VERSION ""

NS_ :

BS_:

BU_: Turbocharger OnBoardDataLogger OffBoardDiagnosticTool2 OffBoardDiagnosticTool1 FileServer ParkingBrakeController SeatControl2 FanDriveController SteeringColumnUnit CommunicationUnitRadio CommunicationUnitSatellite CommunicationUnitCellular PropulsionBatteryCharger ChassisController2 ChassisController1 EngineValveControl AuxiliaryHeater2 AuxiliaryHeater1 ClutchUnit RampControl InformationSystem1 SuspensionSystemController2 OilSensor VehicleDynamicStability ExhaustEmissionController TransmissionDisplay2 TransmissionDisplay1 ClimateControl2 WaterPumpController RearAxleSteeringController LightingOperatorControl SeatController1 IgnitionController2 IgnitionController1 TirePressureController CabController2 CabController1 PneumaticSystemController SuspensionSystemController1 HydraulicPumpController EnduranceBrakingSystem RetarderExhaustEngine2 OnBoardDiagnosticUnit HeadwayController RetarderExhaustEngine1 CabDisplay1 ManagementComputer VirtualTerminal OffVehicleGateway PowerTakeOffFront HitchControl AuxiliaryValveControl BodyController TractorTrailerBridge1 StarterSystem ElectricalSystem VehicleSecurity VehicleNavigation AerodynamicControl ElectricalChargingSystem ClimateControl1 TripRecorder InstrumentCluster SuspensionDriveAxle2 SuspensionDriveAxle1 SuspensionSteerAxle SteeringController FuelSystem CruiseControl RetarderDriveline RetarderEngine BrakesDriveAxle2 BrakesDriveAxle1 BrakesSystemController BrakesSteerAxle AxleDrive2 AxleDrive1 AxleSteering PowerTakeOff ShiftConsoleSecondary ShiftConsolePrimary Transmission2 Transmission1 Engine2 Engine1

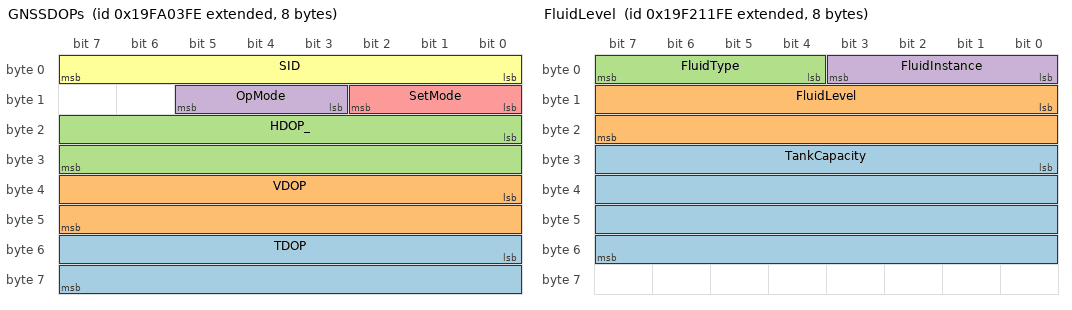
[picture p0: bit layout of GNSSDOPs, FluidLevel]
BO_ 2583299070 GNSSDOPs: 8 Vector__XXX
 SG_ TDOP : 48|16@1- (0.01,0) [-327.64|327.64] "" Vector__XXX
 SG_ VDOP : 32|16@1- (0.01,0) [-327.64|327.64] "" Vector__XXX
 SG_ HDOP_ : 16|16@1- (0.01,0) [-327.64|327.64] "" Vector__XXX
 SG_ OpMode : 11|3@1+ (1,0) [0|7] "" Vector__XXX
 SG_ SetMode : 8|3@1+ (1,0) [0|7] "" Vector__XXX
 SG_ SID : 0|8@1+ (1,0) [0|252] "" Vector__XXX

BO_ 2583298814 GNSSCtrlStatus: 16 Vector__XXX
 SG_ UseAntennaAltitudeFor2DMode : 120|2@1+ (1,0) [0|3] "" Vector__XXX
 SG_ AntennaAltitudeFor2DMode : 88|32@1- (0.01,0) [-21470000|21470000] "m" Vector__XXX
 SG_ MaxCorrectionAge : 72|16@1+ (0.01,0) [0|655.32] "sec" Vector__XXX
 SG_ Pos_VelocityFilter : 70|2@1+ (1,0) [0|3] "" Vector__XXX
 SG_ DGNSSMode : 67|3@1+ (1,0) [0|7] "" Vector__XXX
 SG_ GNSSMode : 64|3@1+ (1,0) [0|7] "" Vector__XXX
 SG_ SNRMask : 48|16@1- (0.01,0) [-327.64|327.64] "dB" Vector__XXX
 SG_ PDOPSwitch : 32|16@1- (0.01,0) [-327.64|327.64] "" Vector__XXX
 SG_ PDOPMask : 16|16@1- (0.01,0) [-327.64|327.64] "" Vector__XXX
 SG_ SVElevationMask : 0|16@1- (0.0001,0) [-3.14159|3.14159] "rad" Vector__XXX

BO_ 2583303422 GLONASSAlmanacData: 26 Vector__XXX
 SG_ tnA2 : 196|12@1+ (1,0) [0|4095] "" Vector__XXX
 SG_ tcA : 168|28@1+ (1,0) [0|268435455] "" Vector__XXX
 SG_ inA : 144|24@1+ (1,0) [0|16777215] "" Vector__XXX
 SG_ nA3 : 120|24@1+ (1,0) [0|16777215] "" Vector__XXX
 SG_ tnA : 96|24@1+ (1,0) [0|16777215] "" Vector__XXX
 SG_ TnA : 72|24@1+ (1,0) [0|16777215] "" Vector__XXX
 SG_ nA2 : 56|16@1+ (1,0) [0|65535] "" Vector__XXX
 SG_ DOT : 48|8@1+ (1,0) [0|255] "" Vector__XXX
 SG_ nA : 32|16@1+ (1,0) [0|65535] "" Vector__XXX
 SG_ HnA : 27|5@1+ (1,0) [0|31] "" Vector__XXX
 SG_ CnA : 26|1@1+ (1,0) [0|1] "" Vector__XXX
 SG_ NA : 8|16@1+ (1,0) [0|65532] "" Vector__XXX
 SG_ PRN : 0|8@1+ (1,0) [0|252] "" Vector__XXX

BO_ 2582778366 FluidLevel: 8 Vector__XXX
 SG_ TankCapacity : 24|32@1+ (0.0001,0) [0|429600] "cu m" Vector__XXX
 SG_ FluidLevel : 8|16@1- (1,0) [-124|124] "" Vector__XXX
 SG_ FluidType : 4|4@1+ (1,0) [0|15] "" Vector__XXX
 SG_ FluidInstance : 0|4@1+ (1,0) [0|15] "" Vector__XXX

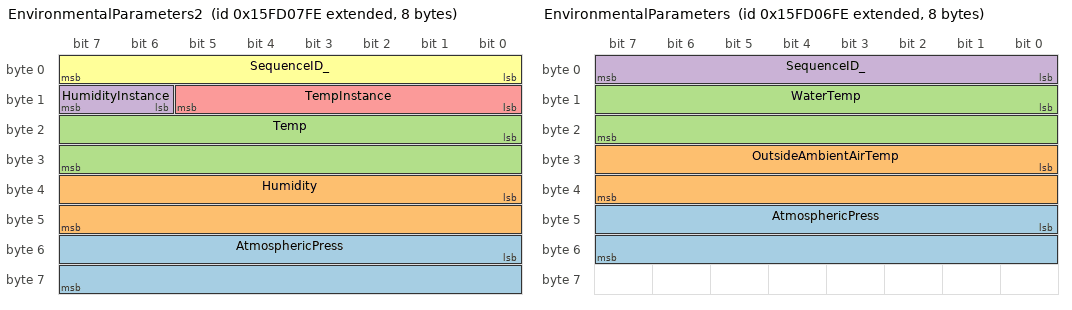
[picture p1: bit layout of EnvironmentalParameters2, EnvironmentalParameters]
BO_ 2516387838 EnvironmentalParameters2: 8 Vector__XXX
 SG_ AtmosphericPress : 48|16@1+ (100,0) [0|6553200] "Pa" Vector__XXX
 SG_ Humidity : 32|16@1- (1,0) [-124|124] "" Vector__XXX
 SG_ Temp : 16|16@1+ (0.01,0) [0|655.32] "°K" Vector__XXX
 SG_ HumidityInstance : 14|2@1+ (1,0) [0|3] "" Vector__XXX
 SG_ TempInstance : 8|6@1+ (1,0) [0|63] "" Vector__XXX
 SG_ SequenceID_ : 0|8@1+ (1,0) [0|252] "" Vector__XXX

BO_ 2516387582 EnvironmentalParameters: 8 Vector__XXX
 SG_ AtmosphericPress : 40|16@1+ (100,0) [0|6553200] "Pa" Vector__XXX
 SG_ OutsideAmbientAirTemp : 24|16@1+ (0.01,0) [0|655.32] "°K" Vector__XXX
 SG_ WaterTemp : 8|16@1+ (0.01,0) [0|655.32] "°K" Vector__XXX
 SG_ SequenceID_ : 0|8@1+ (1,0) [0|252] "" Vector__XXX

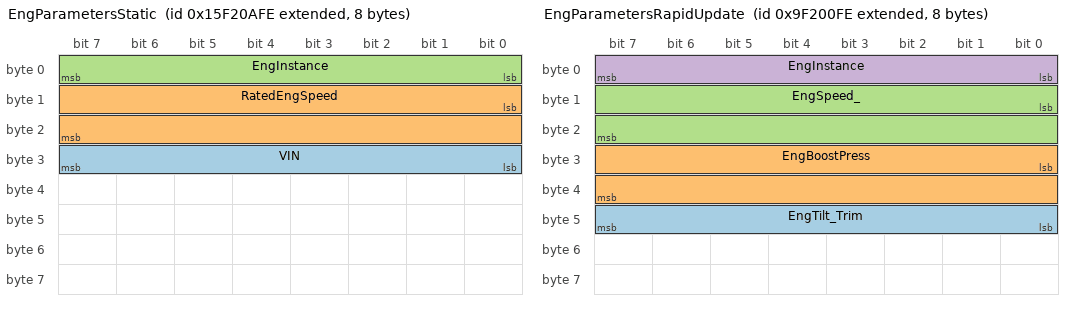
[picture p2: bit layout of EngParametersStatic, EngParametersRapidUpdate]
BO_ 2515667710 EngParametersStatic: 8 Vector__XXX
 SG_ VIN : 24|8@1+ (1,0) [0|255] "ASCII" Vector__XXX
 SG_ RatedEngSpeed : 8|16@1+ (1,0) [0|16383] "rpm" Vector__XXX
 SG_ EngInstance : 0|8@1+ (1,0) [0|255] "" Vector__XXX

BO_ 2314338558 EngParametersRapidUpdate: 8 Vector__XXX
 SG_ EngTilt_Trim : 40|8@1- (1,0) [-124|124] "" Vector__XXX
 SG_ EngBoostPress : 24|16@1+ (100,0) [0|6553200] "Pa" Vector__XXX
 SG_ EngSpeed_ : 8|16@1+ (1,0) [0|16383] "rpm" Vector__XXX
 SG_ EngInstance : 0|8@1+ (1,0) [0|255] "" Vector__XXX

BO_ 2314338814 EngParametersDynamic: 26 Vector__XXX
 SG_ PercentEngTorque : 200|8@1- (1,0) [-124|124] "" Vector__XXX
 SG_ PercentEngLoad : 192|8@1- (1,0) [-124|124] "" Vector__XXX
 SG_ EngDiscreteStatus2 : 176|16@1+ (1,0) [0|65535] "" Vector__XXX
 SG_ EngDiscreteStatus1 : 160|16@1+ (1,0) [0|65535] "" Vector__XXX
 SG_ FuelPress : 136|16@1+ (1000,0) [0|65532000] "Pa" Vector__XXX
 SG_ EngCoolantPress_ : 120|16@1+ (100,0) [0|6553200] "Pa" Vector__XXX
 SG_ TotalEngHours : 88|32@1+ (1,0) [0|32704] "sec" Vector__XXX
 SG_ FuelRate : 72|16@1- (0.0001,0) [-3.2764|3.2764] "(cu m)/hr" Vector__XXX
 SG_ AltPotential : 56|16@1- (0.01,0) [-327.64|327.64] "V" Vector__XXX
 SG_ EngTemp : 40|16@1+ (0.01,0) [0|655.32] "°K" Vector__XXX
 SG_ EngOilTemp : 24|16@1+ (0.1,0) [0|6553.2] "°K" Vector__XXX
 SG_ EngOilPress_ : 8|16@1+ (100,0) [0|6553200] "Pa" Vector__XXX
 SG_ EngInstance : 0|8@1+ (1,0) [0|255] "" Vector__XXX

BO_ 2582975486 DistanceLog: 14 Vector__XXX
 SG_ DistanceSinceLastReset : 80|32@1+ (1,0) [0|32704] "m" Vector__XXX
 SG_ TotalCumulativeDistance : 48|32@1+ (1,0) [0|32704] "m" Vector__XXX
 SG_ MeasurementTime : 16|32@1+ (0.0001,0) [0|86401] "sec" Vector__XXX
 SG_ MeasurementDate : 0|16@1+ (1,0) [0|65532] "day" Vector__XXX

BO_ 2382238206 DirectionData: 14 Vector__XXX
 SG_ Drift : 96|16@1+ (0.01,0) [0|655.32] "m/s" Vector__XXX
 SG_ Set : 80|16@1+ (0.0001,0) [0|6.28318] "rad" Vector__XXX
 SG_ SpeedThroughWater : 64|16@1+ (0.01,0) [0|655.32] "m/s" Vector__XXX
 SG_ Heading : 48|16@1+ (0.0001,0) [0|6.28318] "rad" Vector__XXX
 SG_ SpeedOverGround : 32|16@1+ (0.01,0) [0|655.32] "m/s" Vector__XXX
 SG_ CourseOverGround : 16|16@1+ (0.0001,0) [0|6.28318] "rad" Vector__XXX
 SG_ SID : 8|8@1+ (1,0) [0|252] "" Vector__XXX
 SG_ Set_COG_HeadingRef : 4|2@1+ (1,0) [0|3] "" Vector__XXX
 SG_ DataMode : 0|4@1+ (1,0) [0|15] "" Vector__XXX

BO_ 2583172350 Datum: 8 Vector__XXX
 SG_ LocalDatum : 0|8@1+ (1,0) [0|255] "ASCII" Vector__XXX

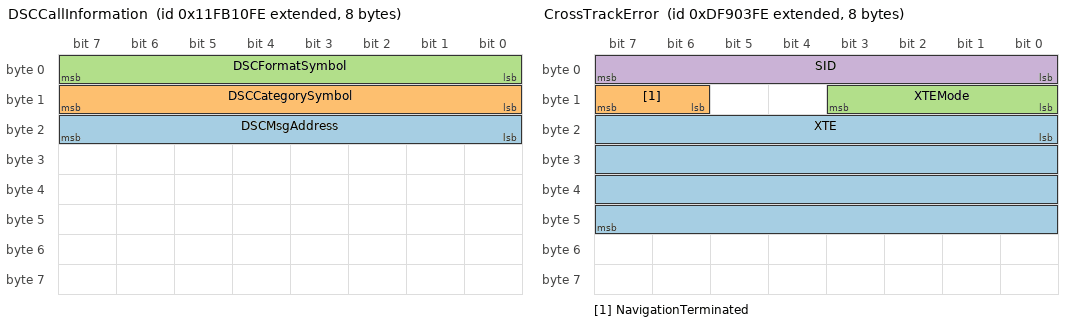
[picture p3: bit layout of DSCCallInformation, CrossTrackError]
BO_ 2449150206 DSCCallInformation: 8 Vector__XXX
 SG_ DSCMsgAddress : 16|8@1+ (1,0) [0|255] "ASCII" Vector__XXX
 SG_ DSCCategorySymbol : 8|8@1+ (1,0) [0|252] "" Vector__XXX
 SG_ DSCFormatSymbol : 0|8@1+ (1,0) [0|252] "" Vector__XXX

BO_ 2583301630 DGNSSCorrections: 16 Vector__XXX
 SG_ IOD : 120|8@1+ (1,0) [0|252] "" Vector__XXX
 SG_ UDRE : 104|16@1+ (0.01,0) [0|655.32] "m" Vector__XXX
 SG_ RRC : 88|16@1- (0.0001,0) [-3.2764|3.2764] "m/s" Vector__XXX
 SG_ PRC : 56|32@1- (0.0001,0) [-214700|214700] "m" Vector__XXX
 SG_ SatelliteID : 48|8@1+ (1,0) [0|252] "" Vector__XXX
 SG_ StationHealth : 40|4@1+ (1,0) [0|15] "" Vector__XXX
 SG_ TimeOfCorrections : 24|16@1+ (1,0) [0|6553.2] "sec" Vector__XXX
 SG_ ReferenceStationType : 20|4@1+ (1,0) [0|15] "" Vector__XXX
 SG_ ReferenceStationID : 8|12@1+ (1,0) [0|4095] "" Vector__XXX
 SG_ SequenceID_ : 0|8@1+ (1,0) [0|252] "" Vector__XXX

BO_ 2583499518 CurrentStationData: 26 Vector__XXX
 SG_ StationIDString : 200|8@1+ (1,0) [0|255] "ASCII" Vector__XXX
 SG_ WaterTemp : 184|16@1+ (0.01,0) [0|655.32] "°K" Vector__XXX
 SG_ CurrentFlowDirection : 168|16@1+ (0.0001,0) [0|6.28318] "rad" Vector__XXX
 SG_ CurrentSpeed : 152|16@1+ (0.01,0) [0|655.32] "m/s" Vector__XXX
 SG_ MeasurementDepth : 120|32@1+ (0.01,0) [0|42950000] "m" Vector__XXX
 SG_ StationLocationLongitude : 88|32@1- (1E-007,0) [-180|180] "deg" Vector__XXX
 SG_ StationLocationLatitude : 56|32@1- (1E-007,0) [-90|90] "deg" Vector__XXX
 SG_ MeasurementTime : 24|32@1+ (0.0001,0) [0|86401] "sec" Vector__XXX
 SG_ MeasurementDate : 8|16@1+ (1,0) [0|65532] "day" Vector__XXX
 SG_ State : 4|3@1+ (1,0) [0|7] "" Vector__XXX
 SG_ Mode : 0|4@1+ (1,0) [0|15] "" Vector__XXX

BO_ 2381906942 CrossTrackError: 8 Vector__XXX
 SG_ XTE : 16|32@1- (0.01,0) [-21470000|21470000] "m" Vector__XXX
 SG_ NavigationTerminated : 14|2@1+ (1,0) [0|3] "" Vector__XXX
 SG_ XTEMode : 8|4@1+ (1,0) [0|15] "" Vector__XXX
 SG_ SID : 0|8@1+ (1,0) [0|252] "" Vector__XXX

BO_ 2582648574 ConfigInformation: 8 Vector__XXX
 SG_ InstallationDescriptionField1 : 0|8@1+ (1,0) [0|255] "ASCII" Vector__XXX

BO_ 2583238398 BringAndDistanceBetweenTwoMarks: 17 Vector__XXX
 SG_ DestinationMarkID : 104|32@1+ (1,0) [0|4294967292] "" Vector__XXX
 SG_ OriginMarkId : 72|32@1+ (1,0) [0|4294967292] "" Vector__XXX
 SG_ DestinationMarkType : 68|4@1+ (1,0) [0|15] "" Vector__XXX
 SG_ OriginMarkType : 64|4@1+ (1,0) [0|15] "" Vector__XXX
 SG_ Distance : 32|32@1- (0.01,0) [-21470000|21470000] "m" Vector__XXX
 SG_ BearingiginToDestination : 16|16@1+ (0.0001,0) [0|6.28318] "rad" Vector__XXX
 SG_ CalculationType : 10|2@1+ (1,0) [0|3] "" Vector__XXX
 SG_ BearingRef : 8|2@1+ (1,0) [0|3] "" Vector__XXX
 SG_ SID : 0|8@1+ (1,0) [0|252] "" Vector__XXX

BO_ 2381450750 BinarySwitchBankStatus: 8 Vector__XXX
 SG_ Indic28 : 62|2@1+ (1,0) [0|3] "" Vector__XXX
 SG_ Indic27 : 60|2@1+ (1,0) [0|3] "" Vector__XXX
 SG_ Indic26 : 58|2@1+ (1,0) [0|3] "" Vector__XXX
 SG_ Indic25 : 56|2@1+ (1,0) [0|3] "" Vector__XXX
 SG_ Indic24 : 54|2@1+ (1,0) [0|3] "" Vector__XXX
 SG_ Indic23 : 52|2@1+ (1,0) [0|3] "" Vector__XXX
 SG_ Indic22 : 50|2@1+ (1,0) [0|3] "" Vector__XXX
 SG_ Indic21 : 48|2@1+ (1,0) [0|3] "" Vector__XXX
 SG_ Indic20 : 46|2@1+ (1,0) [0|3] "" Vector__XXX
 SG_ Indic19 : 44|2@1+ (1,0) [0|3] "" Vector__XXX
 SG_ Indic18 : 42|2@1+ (1,0) [0|3] "" Vector__XXX
 SG_ Indic17 : 40|2@1+ (1,0) [0|3] "" Vector__XXX
 SG_ Indic16 : 38|2@1+ (1,0) [0|3] "" Vector__XXX
 SG_ Indic15 : 36|2@1+ (1,0) [0|3] "" Vector__XXX
 SG_ Indic14 : 34|2@1+ (1,0) [0|3] "" Vector__XXX
 SG_ Indic13 : 32|2@1+ (1,0) [0|3] "" Vector__XXX
 SG_ Indic12 : 30|2@1+ (1,0) [0|3] "" Vector__XXX
 SG_ Indic11 : 28|2@1+ (1,0) [0|3] "" Vector__XXX
 SG_ Indic10 : 26|2@1+ (1,0) [0|3] "" Vector__XXX
 SG_ Indic9 : 24|2@1+ (1,0) [0|3] "" Vector__XXX
 SG_ Indic8 : 22|2@1+ (1,0) [0|3] "" Vector__XXX
 SG_ Indic7 : 20|2@1+ (1,0) [0|3] "" Vector__XXX
 SG_ Indic6 : 18|2@1+ (1,0) [0|3] "" Vector__XXX
 SG_ Indic5 : 16|2@1+ (1,0) [0|3] "" Vector__XXX
 SG_ Indic4 : 14|2@1+ (1,0) [0|3] "" Vector__XXX
 SG_ Indic3 : 12|2@1+ (1,0) [0|3] "" Vector__XXX
 SG_ Indic2 : 10|2@1+ (1,0) [0|3] "" Vector__XXX
 SG_ Indic1 : 8|2@1+ (1,0) [0|3] "" Vector__XXX
 SG_ IndicatorBankInstance : 0|8@1+ (1,0) [0|252] "" Vector__XXX

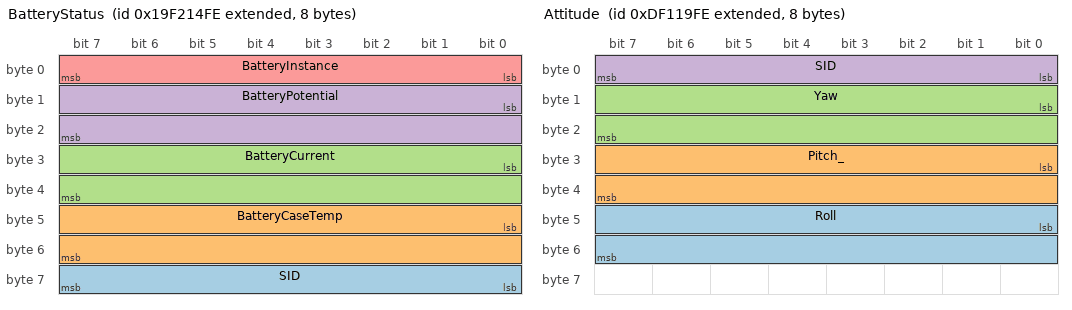
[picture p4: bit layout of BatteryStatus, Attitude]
BO_ 2582779134 BatteryStatus: 8 Vector__XXX
 SG_ SID : 56|8@1+ (1,0) [0|252] "" Vector__XXX
 SG_ BatteryCaseTemp : 40|16@1+ (0.01,0) [0|655.32] "°K" Vector__XXX
 SG_ BatteryCurrent : 24|16@1- (0.1,0) [-3276.4|3276.4] "A" Vector__XXX
 SG_ BatteryPotential : 8|16@1- (0.01,0) [-327.64|327.64] "V" Vector__XXX
 SG_ BatteryInstance : 0|8@1+ (1,0) [0|252] "" Vector__XXX

BO_ 2381388286 Attitude: 8 Vector__XXX
 SG_ Roll : 40|16@1- (0.0001,0) [-3.14159|3.14159] "rad" Vector__XXX
 SG_ Pitch_ : 24|16@1+ (0.0001,0) [-3.14159|3.14159] "rad" Vector__XXX
 SG_ Yaw : 8|16@1- (0.0001,0) [-3.14159|3.14159] "rad" Vector__XXX
 SG_ SID : 0|8@1+ (1,0) [0|252] "" Vector__XXX

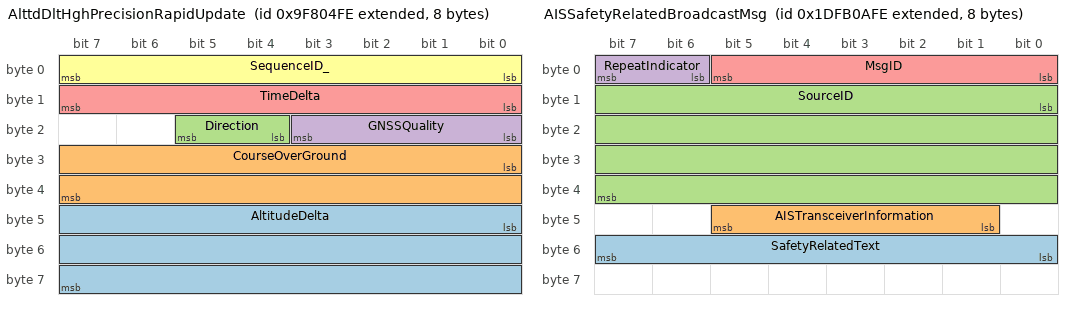
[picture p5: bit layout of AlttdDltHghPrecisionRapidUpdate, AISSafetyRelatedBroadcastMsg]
BO_ 2314732798 AlttdDltHghPrecisionRapidUpdate: 8 Vector__XXX
 SG_ AltitudeDelta : 40|24@1- (0.001,0) [-8388|8388] "m" Vector__XXX
 SG_ CourseOverGround : 24|16@1+ (0.0001,0) [0|6.28318] "rad" Vector__XXX
 SG_ Direction : 20|2@1+ (1,0) [0|3] "" Vector__XXX
 SG_ GNSSQuality : 16|4@1+ (1,0) [0|15] "" Vector__XXX
 SG_ TimeDelta : 8|8@1+ (0.005,0) [0|1.26] "sec" Vector__XXX
 SG_ SequenceID_ : 0|8@1+ (1,0) [0|252] "" Vector__XXX

BO_ 2650474750 AISUTC_DateInquiry: 11 Vector__XXX
 SG_ DestinationID : 48|32@1+ (1,0) [0|4294967292] "" Vector__XXX
 SG_ AISTransceiverInformation : 41|5@1+ (1,0) [0|31] "" Vector__XXX
 SG_ SourceID : 8|32@1+ (1,0) [0|4294967292] "" Vector__XXX
 SG_ RepeatIndicator : 6|2@1+ (1,0) [0|3] "" Vector__XXX
 SG_ MsgID : 0|6@1+ (1,0) [0|63] "" Vector__XXX

BO_ 2650472958 AISUTCAndDateReport: 26 Vector__XXX
 SG_ TypeOfElectronicPosingDevice : 188|4@1+ (1,0) [0|15] "" Vector__XXX
 SG_ PosDate : 168|16@1+ (1,0) [0|65532] "day" Vector__XXX
 SG_ AISTransceiverInformation : 163|5@1+ (1,0) [0|31] "" Vector__XXX
 SG_ CommunicationState : 144|19@1+ (1,0) [0|524287] "" Vector__XXX
 SG_ PosTime : 112|32@1+ (0.0001,0) [0|86401] "sec" Vector__XXX
 SG_ RAIMflag : 105|1@1+ (1,0) [0|1] "" Vector__XXX
 SG_ PosAccuracy : 104|1@1+ (1,0) [0|1] "" Vector__XXX
 SG_ Latitude_ : 72|32@1- (1E-007,0) [-90|90] "deg" Vector__XXX
 SG_ Longitude_ : 40|32@1- (1E-007,0) [-180|180] "deg" Vector__XXX
 SG_ UserID : 8|32@1+ (1,0) [0|4294967292] "" Vector__XXX
 SG_ RepeatIndicator : 6|2@1+ (1,0) [0|3] "" Vector__XXX
 SG_ MsgID : 0|6@1+ (1,0) [0|63] "" Vector__XXX

BO_ 2650475262 AISSafetyRelatedBroadcastMsg: 8 Vector__XXX
 SG_ SafetyRelatedText : 48|8@1+ (1,0) [0|255] "ASCII" Vector__XXX
 SG_ AISTransceiverInformation : 41|5@1+ (1,0) [0|31] "" Vector__XXX
 SG_ SourceID : 8|32@1+ (1,0) [0|4294967292] "" Vector__XXX
 SG_ RepeatIndicator : 6|2@1+ (1,0) [0|3] "" Vector__XXX
 SG_ MsgID : 0|6@1+ (1,0) [0|63] "" Vector__XXX

BO_ 2650474238 AISSARAircraftPosReport: 27 Vector__XXX
 SG_ DataTerminalEquipment : 208|1@1+ (1,0) [0|1] "" Vector__XXX
 SG_ Altitude_ : 168|32@1- (0.01,0) [-21470000|21470000] "m" Vector__XXX
 SG_ AISTransceiverInformation : 163|5@1+ (1,0) [0|31] "" Vector__XXX
 SG_ CommunicationState : 144|19@1+ (1,0) [0|524287] "" Vector__XXX
 SG_ SOG : 128|16@1+ (0.01,0) [0|655.32] "m/s" Vector__XXX
 SG_ COG : 112|16@1+ (0.0001,0) [0|6.28318] "rad" Vector__XXX
 SG_ TimeStamp : 106|6@1+ (1,0) [0|63] "" Vector__XXX
 SG_ RAIMFlag : 105|1@1+ (1,0) [0|1] "" Vector__XXX
 SG_ PosAccuracy : 104|1@1+ (1,0) [0|1] "" Vector__XXX
 SG_ Latitude_ : 72|32@1- (1E-007,0) [-90|90] "deg" Vector__XXX
 SG_ Longitude_ : 40|32@1- (1E-007,0) [-180|180] "deg" Vector__XXX
 SG_ UserID : 8|32@1+ (1,0) [0|4294967292] "" Vector__XXX
 SG_ RepeatIndicator : 6|2@1+ (1,0) [0|3] "" Vector__XXX
 SG_ MsgID : 0|6@1+ (1,0) [0|63] "" Vector__XXX

BO_ 2650475518 AISInterrogation: 25 Vector__XXX
 SG_ SlotOffset21 : 176|16@1+ (1,0) [0|65532] "" Vector__XXX
 SG_ MsgID21 : 170|6@1+ (1,0) [0|63] "" Vector__XXX
 SG_ DestinationID2 : 136|32@1+ (1,0) [0|4294967292] "" Vector__XXX
 SG_ SlotOffset12 : 112|16@1+ (1,0) [0|65532] "" Vector__XXX
 SG_ MsgID12 : 106|6@1+ (1,0) [0|63] "" Vector__XXX
 SG_ SlotOffset11 : 88|16@1+ (1,0) [0|65532] "" Vector__XXX
 SG_ MsgID11 : 82|6@1+ (1,0) [0|63] "" Vector__XXX
 SG_ DestinationID1 : 48|32@1+ (1,0) [0|4294967292] "" Vector__XXX
 SG_ AISTransceiverInformation : 41|5@1+ (1,0) [0|31] "" Vector__XXX
 SG_ SourceID : 8|32@1+ (1,0) [0|4294967292] "" Vector__XXX
 SG_ RepeatIndicator : 6|2@1+ (1,0) [0|3] "" Vector__XXX
 SG_ MsgID : 0|6@1+ (1,0) [0|63] "" Vector__XXX

BO_ 2650476030 AISDataLinkManagementMsg: 31 Vector__XXX
 SG_ Increment4 : 224|16@1+ (1,0) [0|65532] "" Vector__XXX
 SG_ TimeOut4 : 216|8@1+ (1,0) [0|252] "" Vector__XXX
 SG_ NumberOfSlots4 : 208|8@1+ (1,0) [0|252] "" Vector__XXX
 SG_ OffsetNumber4 : 192|16@1+ (1,0) [0|65532] "" Vector__XXX
 SG_ Increment3 : 176|16@1+ (1,0) [0|65532] "" Vector__XXX
 SG_ TimeOut3 : 168|8@1+ (1,0) [0|252] "" Vector__XXX
 SG_ NumberOfSlots3 : 160|8@1+ (1,0) [0|252] "" Vector__XXX
 SG_ OffsetNumber3 : 144|16@1+ (1,0) [0|65532] "" Vector__XXX
 SG_ Increment2 : 128|16@1+ (1,0) [0|65532] "" Vector__XXX
 SG_ TimeOut2 : 120|8@1+ (1,0) [0|252] "" Vector__XXX
 SG_ NumberOfSlots2 : 112|8@1+ (1,0) [0|252] "" Vector__XXX
 SG_ OffsetNumber2 : 96|16@1+ (1,0) [0|65532] "" Vector__XXX
 SG_ Increment1 : 80|16@1+ (1,0) [0|65532] "" Vector__XXX
 SG_ TimeOut1 : 72|8@1+ (1,0) [0|252] "" Vector__XXX
 SG_ NumberOfSlots1 : 64|8@1+ (1,0) [0|252] "" Vector__XXX
 SG_ OffsetNumber1 : 48|16@1+ (1,0) [0|65532] "" Vector__XXX
 SG_ AISTransceiverInformation : 41|5@1+ (1,0) [0|31] "" Vector__XXX
 SG_ SourceStationID : 8|32@1+ (1,0) [0|4294967292] "" Vector__XXX
 SG_ RepeatIndicator : 6|2@1+ (1,0) [0|3] "" Vector__XXX
 SG_ MsgID : 0|6@1+ (1,0) [0|63] "" Vector__XXX

BO_ 2583363838 AISDGNSSBroadcastBinaryMsg: 17 Vector__XXX
 SG_ NumberOfBitsInBinaryDataField : 120|16@1+ (1,0) [0|65532] "" Vector__XXX
 SG_ Latitude_ : 80|32@1- (1E-007,0) [-90|90] "deg" Vector__XXX
 SG_ Longitude_ : 48|32@1- (1E-007,0) [-180|180] "deg" Vector__XXX
 SG_ AISTransceiverInformation : 41|5@1+ (1,0) [0|31] "" Vector__XXX
 SG_ SourceID : 8|32@1+ (1,0) [0|4294967292] "" Vector__XXX
 SG_ RepeatIndicator : 6|2@1+ (1,0) [0|3] "" Vector__XXX
 SG_ MsgID : 0|6@1+ (1,0) [0|63] "" Vector__XXX

BO_ 2650473214 AISClssASttcAndVyageRelatedData: 10 Vector__XXX
 SG_ CallSign : 72|8@1+ (1,0) [0|255] "ASCII" Vector__XXX
 SG_ IMO : 40|32@1+ (1,0) [0|4294967292] "" Vector__XXX
 SG_ UserID : 8|32@1+ (1,0) [0|4294967292] "" Vector__XXX
 SG_ RepeatIndicator : 6|2@1+ (1,0) [0|3] "" Vector__XXX
 SG_ MsgID : 0|6@1+ (1,0) [0|63] "" Vector__XXX

BO_ 2448953342 AISClassBPosReport: 26 Vector__XXX
 SG_ ComminicationStateSelectorFlag : 200|1@1+ (1,0) [0|1] "" Vector__XXX
 SG_ TrueHeading : 168|16@1+ (0.0001,0) [0|6.28318] "rad" Vector__XXX
 SG_ AISTransceiverInformation : 163|5@1+ (1,0) [0|31] "" Vector__XXX
 SG_ CommunicationState : 144|19@1+ (1,0) [0|524287] "" Vector__XXX
 SG_ SOG : 128|16@1+ (0.01,0) [0|655.32] "m/s" Vector__XXX
 SG_ COG : 112|16@1+ (0.0001,0) [0|6.28318] "rad" Vector__XXX
 SG_ TimeStamp : 106|6@1+ (1,0) [0|63] "" Vector__XXX
 SG_ RAIMflag : 105|1@1+ (1,0) [0|1] "" Vector__XXX
 SG_ PosAccuracy : 104|1@1+ (1,0) [0|1] "" Vector__XXX
 SG_ Latitude_ : 72|32@1- (1E-007,0) [-90|90] "deg" Vector__XXX
 SG_ Longitude_ : 40|32@1- (1E-007,0) [-180|180] "deg" Vector__XXX
 SG_ UserID : 8|32@1+ (1,0) [0|4294967292] "" Vector__XXX
 SG_ RepeatIndicator : 6|2@1+ (1,0) [0|3] "" Vector__XXX
 SG_ MsgID : 0|6@1+ (1,0) [0|63] "" Vector__XXX

BO_ 2448953598 AISClassBExPosReport: 33 Vector__XXX
 SG_ Name : 256|8@1+ (1,0) [0|255] "ASCII" Vector__XXX
 SG_ PosReferencePointAftOfShipsBow : 240|16@1+ (0.1,0) [0|6553.2] "m" Vector__XXX
 SG_ PosReferencePointFromStarboard : 224|16@1+ (0.1,0) [0|6553.2] "m" Vector__XXX
 SG_ ShipBeam : 208|16@1+ (0.1,0) [0|6553.2] "m" Vector__XXX
 SG_ ShipLength : 192|16@1+ (0.1,0) [0|6553.2] "m" Vector__XXX
 SG_ TypeOfElectronicPosingDevice : 188|4@1+ (1,0) [0|15] "" Vector__XXX
 SG_ TrueHeading : 168|16@1+ (0.0001,0) [0|6.28318] "rad" Vector__XXX
 SG_ Ship_CargoType : 160|8@1+ (1,0) [0|255] "" Vector__XXX
 SG_ SOG : 128|16@1+ (0.01,0) [0|655.32] "m/s" Vector__XXX
 SG_ COG : 112|16@1+ (0.0001,0) [0|6.28318] "rad" Vector__XXX
 SG_ TimeStamp : 106|6@1+ (1,0) [0|63] "" Vector__XXX
 SG_ RAIMflag : 105|1@1+ (1,0) [0|1] "" Vector__XXX
 SG_ PosAccuracy : 104|1@1+ (1,0) [0|1] "" Vector__XXX
 SG_ Latitude_ : 72|32@1- (1E-007,0) [-90|90] "deg" Vector__XXX
 SG_ Longitude_ : 40|32@1- (1E-007,0) [-180|180] "deg" Vector__XXX
 SG_ UserID : 8|32@1+ (1,0) [0|4294967292] "" Vector__XXX
 SG_ RepeatIndicator : 6|2@1+ (1,0) [0|3] "" Vector__XXX
 SG_ MsgID : 0|6@1+ (1,0) [0|63] "" Vector__XXX

BO_ 2448953086 AISClassAPosReport: 27 Vector__XXX
 SG_ NavigationalStatus : 200|4@1+ (1,0) [0|15] "" Vector__XXX
 SG_ RateOfTurn : 184|16@1- (1,0) [-32768|32767] "rad/s" Vector__XXX
 SG_ TrueHeading : 168|16@1+ (0.0001,0) [0|6.28318] "rad" Vector__XXX
 SG_ AISTransceiverInformation : 163|5@1+ (1,0) [0|31] "" Vector__XXX
 SG_ CommunicationState : 144|19@1+ (1,0) [0|524287] "" Vector__XXX
 SG_ SOG : 128|16@1+ (0.01,0) [0|655.32] "m/s" Vector__XXX
 SG_ COG : 112|16@1+ (0.0001,0) [0|6.28318] "rad" Vector__XXX
 SG_ TimeStamp : 106|6@1+ (1,0) [0|63] "" Vector__XXX
 SG_ RAIMflag : 105|1@1+ (1,0) [0|1] "" Vector__XXX
 SG_ PosAccuracy : 104|1@1+ (1,0) [0|1] "" Vector__XXX
 SG_ Latitude_ : 72|32@1- (1E-007,0) [-90|90] "deg" Vector__XXX
 SG_ Longitude_ : 40|32@1- (1E-007,0) [-180|180] "deg" Vector__XXX
 SG_ UserID : 8|32@1+ (1,0) [0|4294967292] "" Vector__XXX
 SG_ RepeatIndicator : 6|2@1+ (1,0) [0|3] "" Vector__XXX
 SG_ MsgID : 0|6@1+ (1,0) [0|63] "" Vector__XXX

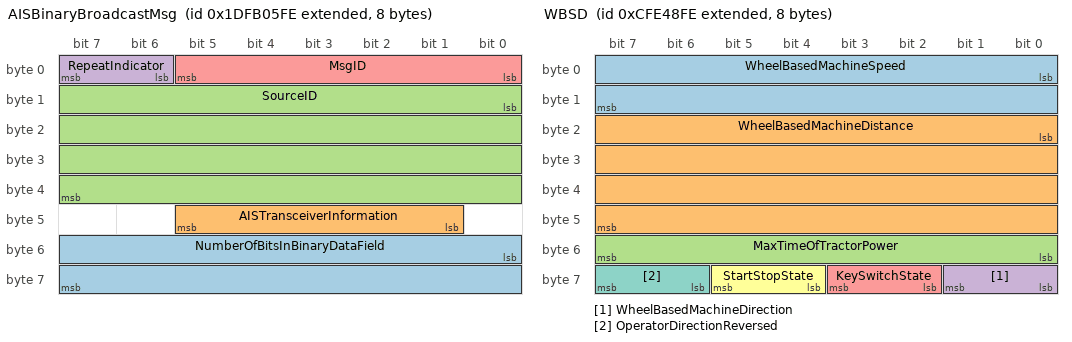
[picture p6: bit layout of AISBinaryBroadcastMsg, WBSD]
BO_ 2650473982 AISBinaryBroadcastMsg: 8 Vector__XXX
 SG_ NumberOfBitsInBinaryDataField : 48|16@1+ (1,0) [0|65532] "" Vector__XXX
 SG_ AISTransceiverInformation : 41|5@1+ (1,0) [0|31] "" Vector__XXX
 SG_ SourceID : 8|32@1+ (1,0) [0|4294967292] "" Vector__XXX
 SG_ RepeatIndicator : 6|2@1+ (1,0) [0|3] "" Vector__XXX
 SG_ MsgID : 0|6@1+ (1,0) [0|63] "" Vector__XXX

BO_ 2650475774 AISAssignmentModeCmd: 23 Vector__XXX
 SG_ IncrementB : 160|16@1+ (1,0) [0|65532] "" Vector__XXX
 SG_ OffsetB : 144|16@1+ (1,0) [0|65532] "" Vector__XXX
 SG_ DestinationIDB : 112|32@1+ (1,0) [0|4294967292] "" Vector__XXX
 SG_ IncrementA : 96|16@1+ (1,0) [0|65532] "" Vector__XXX
 SG_ OffsetA : 80|16@1+ (1,0) [0|65532] "" Vector__XXX
 SG_ DestinationIDA : 48|32@1+ (1,0) [0|4294967292] "" Vector__XXX
 SG_ AISTransceiverInformation : 41|5@1+ (1,0) [0|31] "" Vector__XXX
 SG_ SourceID : 8|32@1+ (1,0) [0|4294967292] "" Vector__XXX
 SG_ RepeatIndicator : 6|2@1+ (1,0) [0|3] "" Vector__XXX
 SG_ MsgID : 0|6@1+ (1,0) [0|63] "" Vector__XXX

BO_ 2650475006 AISAddressedSafetyRelatedMsg: 12 Vector__XXX
 SG_ SafetyRelatedText : 88|8@1+ (1,0) [0|255] "ASCII" Vector__XXX
 SG_ RetransmitFlag : 86|1@1+ (1,0) [0|1] "" Vector__XXX
 SG_ DestinationID : 48|32@1+ (1,0) [0|4294967292] "" Vector__XXX
 SG_ SequenceNumber_ : 46|2@1+ (1,0) [0|3] "" Vector__XXX
 SG_ AISTransceiverInformation : 41|5@1+ (1,0) [0|31] "" Vector__XXX
 SG_ SourceID : 8|32@1+ (1,0) [0|4294967292] "" Vector__XXX
 SG_ RepeatIndicator : 6|2@1+ (1,0) [0|3] "" Vector__XXX
 SG_ MsgID : 0|6@1+ (1,0) [0|63] "" Vector__XXX

BO_ 2650473470 AISAddressedBinaryMsg: 13 Vector__XXX
 SG_ NumberOfBitsInBinaryDataField : 88|16@1+ (1,0) [0|65532] "" Vector__XXX
 SG_ RetransmitFlag : 86|1@1+ (1,0) [0|1] "" Vector__XXX
 SG_ DestinationID : 48|32@1+ (1,0) [0|4294967292] "" Vector__XXX
 SG_ SequenceNumber_ : 46|2@1+ (1,0) [0|3] "" Vector__XXX
 SG_ AISTransceiverInformation : 41|5@1+ (1,0) [0|31] "" Vector__XXX
 SG_ SourceID : 8|32@1+ (1,0) [0|4294967292] "" Vector__XXX
 SG_ RepeatIndicator : 6|2@1+ (1,0) [0|3] "" Vector__XXX
 SG_ MsgID : 0|6@1+ (1,0) [0|63] "" Vector__XXX

BO_ 2650473726 AISAcknowledge: 12 Vector__XXX
 SG_ SequenceNumberForIDn : 94|2@1+ (1,0) [0|3] "" Vector__XXX
 SG_ SequenceNumberForID1 : 86|2@1+ (1,0) [0|3] "" Vector__XXX
 SG_ DestinationID1 : 48|32@1+ (1,0) [0|4294967292] "" Vector__XXX
 SG_ AISTransceiverInformation : 41|5@1+ (1,0) [0|31] "" Vector__XXX
 SG_ SourceID : 8|32@1+ (1,0) [0|4294967292] "" Vector__XXX
 SG_ RepeatIndicator : 6|2@1+ (1,0) [0|3] "" Vector__XXX
 SG_ MsgID : 0|6@1+ (1,0) [0|63] "" Vector__XXX

BO_ 2365475070 WBSD: 8 Vector__XXX
 SG_ WheelBasedMachineSpeed : 0|16@1+ (0.001,0) [0|64.255] "m/s" Vector__XXX
 SG_ WheelBasedMachineDistance : 16|32@1+ (0.001,0) [0|4211081.215] "m" Vector__XXX
 SG_ MaxTimeOfTractorPower : 48|8@1+ (1,0) [0|250] "min" Vector__XXX
 SG_ WheelBasedMachineDirection : 56|2@1+ (1,0) [0|3] "" Vector__XXX
 SG_ KeySwitchState : 58|2@1+ (1,0) [0|3] "" Vector__XXX
 SG_ StartStopState : 60|2@1+ (1,0) [0|4] "" Vector__XXX
 SG_ OperatorDirectionReversed : 62|2@1+ (1,0) [0|3] "" Vector__XXX

BO_ 2565340926 VT21: 33 Vector__XXX
 SG_ InputObjectId m33 : 8|16@1+ (1,0) [0|255] "" Vector__XXX
 SG_ KeyActivationCode m0 : 8|8@1+ (1,0) [0|2] "" Vector__XXX
 SG_ ButtonActivationCode m1 : 8|8@1+ (1,0) [0|2] "" Vector__XXX
 SG_ XPosition m2 : 8|16@1+ (1,0) [0|65535] "" Vector__XXX
 SG_ VTSelectInputObjectID m3 : 8|16@1+ (1,0) [0|65535] "" Vector__XXX
 SG_ VTEscObjectID m4 : 8|16@1+ (1,0) [0|65535] "" Vector__XXX
 SG_ VTChangeNumericValueObjectID m5 : 8|16@1+ (1,0) [0|65535] "" Vector__XXX
 SG_ VTChangeActiveMaskObjectID m6 : 8|16@1+ (1,0) [0|65535] "" Vector__XXX
 SG_ VTChangeSoftKeyMaskParentID m7 : 8|16@1+ (1,0) [0|65535] "" Vector__XXX
 SG_ AuxiliaryFunctionObjectID m36 : 8|16@1+ (1,0) [0|65535] "" Vector__XXX
 SG_ InputStatusObjectId m37 : 8|16@1+ (1,0) [0|255] "" Vector__XXX
 SG_ SelectInputObjectID m162 : 8|16@1+ (1,0) [0|65535] "" Vector__XXX
 SG_ ObjectToSizeID m166 : 8|16@1+ (1,0) [0|65535] "" Vector__XXX
 SG_ ObjectToChangeColourID m167 : 8|16@1+ (1,0) [0|65535] "" Vector__XXX
 SG_ ObjectToChangeNumValueID m168 : 8|16@1+ (1,0) [0|65535] "" Vector__XXX
 SG_ ObjectToChangeEndPointID m169 : 8|16@1+ (1,0) [0|65535] "" Vector__XXX
 SG_ ObjectToChangeFontID m170 : 8|16@1+ (1,0) [0|65535] "" Vector__XXX
 SG_ ObjectToChangeFillAttributesID m172 : 8|16@1+ (1,0) [0|65535] "" Vector__XXX
 SG_ ObjectToChangeAttributeID m175 : 8|16@1+ (1,0) [0|65535] "" Vector__XXX
 SG_ AlarmMaskObjectID m176 : 8|16@1+ (1,0) [0|65535] "" Vector__XXX
 SG_ ListInputObjectID m177 : 8|16@1+ (1,0) [0|65535] "" Vector__XXX
 SG_ PolygonObjectToChangeID m182 : 8|16@1+ (1,0) [0|65535] "" Vector__XXX
 SG_ PolygonObjectToScaleID m183 : 8|16@1+ (1,0) [0|65535] "" Vector__XXX
 SG_ GraphicsContextObjectID m184 : 8|16@1+ (1,0) [0|65535] "" Vector__XXX
 SG_ ObjectToGetAttributeID m185 : 8|16@1+ (1,0) [0|65535] "" Vector__XXX
 SG_ ColourMapObjectID m186 : 8|16@1+ (1,0) [0|65535] "" Vector__XXX
 SG_ LockUnlockCommand m189 : 8|8@1+ (1,0) [0|1] "" Vector__XXX
 SG_ MacroObjecID m190 : 8|8@1+ (1,0) [0|255] "" Vector__XXX
 SG_ CodePlane m193 : 8|8@1+ (1,0) [0|16] "" Vector__XXX
 SG_ KeyObjectID m0 : 16|16@1+ (1,0) [0|65535] "" Vector__XXX
 SG_ ButtonObjectID m1 : 16|16@1+ (1,0) [0|65535] "" Vector__XXX
 SG_ DataOrAlarmMaskObjectID m174 : 16|16@1+ (1,0) [0|65535] "" Vector__XXX
 SG_ MemoryRequired m192 : 16|32@1+ (1,0) [0|4294967295] "" Vector__XXX
 SG_ FirstWideChar m193 : 16|16@1+ (1,0) [0|65535] "" Vector__XXX
 SG_ IdentityNumber m34 : 16|21@1+ (1,0) [0|2097152] "" Vector__XXX
 SG_ Status_1 m9 : 24|8@1+ (1,0) [0|1] "" Vector__XXX
 SG_ YPosition m2 : 24|16@1+ (1,0) [0|65535] "" Vector__XXX
 SG_ VTSelectInputObjectStatus m3 : 24|8@1+ (1,0) [0|1] "" Vector__XXX
 SG_ VTChangeSoftKeyMaskObjectID m7 : 24|16@1+ (1,0) [0|65535] "" Vector__XXX
 SG_ AuxInputEnable m37 : 24|8@1+ (1,0) [0|1] "" Vector__XXX
 SG_ ChangeChildPositionObjectID m180 : 24|16@1+ (1,0) [0|65535] "" Vector__XXX
 SG_ NewBackgroundColour m167 : 24|8@1+ (1,0) [0|255] "" Vector__XXX
 SG_ AttributeID m185 : 24|8@1+ (1,0) [0|16777200] "" Vector__XXX
 SG_ NewPriority m176 : 24|8@1+ (1,0) [0|255] "" Vector__XXX
 SG_ ListIndex m177 : 24|8@1+ (1,0) [0|255] "" Vector__XXX
 SG_ ChangeChildLocationObjectID m165 : 24|16@1+ (1,0) [0|65535] "" Vector__XXX
 SG_ NewWidthAttribute m183 : 24|16@1+ (1,0) [0|65535] "" Vector__XXX
 SG_ SubCommandID m184M : 24|8@1+ (1,0) [0|0] "" Vector__XXX
 SG_ Value1 m33 : 24|16@1+ (1,0) [0|65535] "" Vector__XXX
 SG_ KeyObjectParentID m0 : 32|16@1+ (1,0) [0|65535] "" Vector__XXX
 SG_ ButtonObjectParentID m1 : 32|16@1+ (1,0) [0|65535] "" Vector__XXX
 SG_ VTChangeNumericValueValue m5 : 32|32@1+ (1,0) [0|4294967295] "" Vector__XXX
 SG_ NewObjectID m177 : 32|16@1+ (1,0) [0|65535] "" Vector__XXX
 SG_ LastWideChar m193 : 32|16@1+ (1,0) [0|65535] "" Vector__XXX
 SG_ ManufacturerCode m34 : 37|11@1+ (1,0) [0|2047] "" Vector__XXX
 SG_ TouchState m2 : 40|8@1+ (1,0) [0|255] "" Vector__XXX
 SG_ NewHeigthAttribute m183 : 40|16@1+ (1,0) [0|0] "" Vector__XXX
 SG_ Value2 m33 : 40|16@1+ (1,0) [0|65535] "" Vector__XXX
 SG_ Status_2 m9 : 48|8@1+ (1,0) [0|1] "" Vector__XXX
 SG_ SoftKeyCode m0 : 48|8@1+ (1,0) [0|255] "" Vector__XXX
 SG_ ButtonKeyCode m1 : 48|8@1+ (1,0) [0|255] "" Vector__XXX
 SG_ ECUInstance m34 : 48|3@1+ (1,0) [0|7] "" Vector__XXX
 SG_ FunctionInstance m34 : 51|5@1+ (1,0) [0|31] "" Vector__XXX
 SG_ OperatingState1 m33 : 56|1@1+ (1,0) [0|1] "" Vector__XXX
 SG_ Function m34 : 56|8@1+ (1,0) [0|255] "" Vector__XXX
 SG_ OperatingState2 m33 : 57|1@1+ (1,0) [0|1] "" Vector__XXX
 SG_ VehicleSystem2 m34 : 65|7@1+ (1,0) [0|127] "" Vector__XXX
 SG_ VehicleSystemInstance m34 : 72|4@1+ (1,0) [0|15] "" Vector__XXX
 SG_ IndustryGroup m34 : 76|3@1+ (1,0) [0|7] "" Vector__XXX
 SG_ ArbitraryAddressCapable m34 : 79|1@1+ (1,0) [0|1] "" Vector__XXX
 SG_ VTFunctionECUtoVT M : 0|8@1+ (1,0) [0|255] "" Vector__XXX
 SG_ ObjectId_1 m9 : 8|16@1+ (1,0) [0|65535] "" Vector__XXX
 SG_ SourceAddressOfAuxiliaryInputDev m32 : 8|8@1+ (1,0) [0|255] "" Vector__XXX
 SG_ ChangeChildPositionParentOb_0000 m180 : 8|16@1+ (1,0) [0|65535] "" Vector__XXX
 SG_ ObjectPoolRecord m17 : 8|56@1+ (1,0) [0|3338120000] "" Vector__XXX
 SG_ NumberOfInpuUnits m34 : 8|8@1+ (1,0) [0|255] "" Vector__XXX
 SG_ AuxModelIdentification m35 : 8|16@1+ (1,0) [0|65535] "" Vector__XXX
 SG_ ObjectToShowHideID m160 : 8|16@1+ (1,0) [0|65535] "" Vector__XXX
 SG_ ObjectoEnableDisbaleID m161 : 8|16@1+ (1,0) [0|65535] "" Vector__XXX
 SG_ NumberOfRepetitions_Audio m163 : 8|8@1+ (1,0) [0|255] "" Vector__XXX
 SG_ AudioVolume m164 : 8|8@1+ (1,0) [0|100] "%" Vector__XXX
 SG_ ChangeChildLocationParentOb_0000 m165 : 8|16@1+ (1,0) [0|65535] "" Vector__XXX
 SG_ ObjectToChangeLineAttributesID m171 : 8|16@1+ (1,0) [0|65535] "" Vector__XXX
 SG_ WorkingSetObjectID m173 : 8|16@1+ (1,0) [0|65535] "" Vector__XXX
 SG_ MaskType m174 : 8|8@1+ (1,0) [0|255] "" Vector__XXX
 SG_ ObjectToChangeStringValueID m179 : 8|16@1+ (1,0) [0|65535] "" Vector__XXX
 SG_ ParentObjectID m8 : 8|16@1+ (1,0) [0|65535] "" Vector__XXX
 SG_ ObjectToAssociateLabelWithID m181 : 8|16@1+ (1,0) [0|65535] "" Vector__XXX
 SG_ VersionLabelToStore m208 : 8|56@1+ (1,0) [0|3338120000] "" Vector__XXX
 SG_ VersionLabelToLoad m209 : 8|56@1+ (1,0) [0|3338120000] "" Vector__XXX
 SG_ VersionLabelToDelete m210 : 8|56@1+ (1,0) [0|3338120000] "" Vector__XXX
 SG_ WSMaintenanceInitiating m3 : 8|1@1+ (1,0) [0|1] "" Vector__XXX
 SG_ AuxCapabilitiesRequestType m39 : 8|8@1+ (1,0) [0|255] "" Vector__XXX
 SG_ OperationCode m191M : 8|7@1+ (1,0) [0|127] "" Vector__XXX
 SG_ MacroObjectID_2 m188 : 8|16@1+ (1,0) [0|65535] "" Vector__XXX
 SG_ ExtendedVersionLabelToStore m212 : 8|256@1+ (1,0) [0|3338120000] "" Vector__XXX
 SG_ ExtendedVersionLabelToLoad m213 : 8|256@1+ (1,0) [0|3338120000] "" Vector__XXX
 SG_ ExtendedVersionLabelToDelete m214 : 8|256@1+ (1,0) [0|3338120000] "" Vector__XXX
 SG_ RValueSelector m1M : 15|1@1+ (1,0) [0|1] "" Vector__XXX
 SG_ LeftObjectID m1 : 16|16@1+ (1,0) [0|65535] "" Vector__XXX
 SG_ AuxiliaryInputNumber m32 : 16|8@1+ (1,0) [0|255] "" Vector__XXX
 SG_ WSMaintenanceVersion m255M : 16|8@1+ (1,0) [0|255] "" Vector__XXX
 SG_ Frequency_Audio m163 : 16|16@1+ (1,0) [0|65535] "hz" Vector__XXX
 SG_ ObjectIDOfDataMaskToLock m189 : 16|16@1+ (1,0) [0|65535] "" Vector__XXX
 SG_ AuxiliaryFunctionID m32 : 24|16@1+ (1,0) [0|65535] "" Vector__XXX
 SG_ ObjectOfChangedStringValueID m8 : 24|16@1+ (1,0) [0|65535] "" Vector__XXX
 SG_ AssignmentErrorNotAccepted m36 : 24|1@1+ (1,0) [0|1] "" Vector__XXX
 SG_ ShowOrHide m160 : 24|8@1+ (1,0) [0|1] "" Vector__XXX
 SG_ EnableOrDisable m161 : 24|8@1+ (1,0) [0|1] "" Vector__XXX
 SG_ SetFocusOpenForEditing m162 : 24|8@1+ (1,0) [0|255] "" Vector__XXX
 SG_ NewWidth m166 : 24|16@1+ (1,0) [0|65535] "" Vector__XXX
 SG_ Width m169 : 24|16@1+ (1,0) [0|65535] "" Vector__XXX
 SG_ FontColour m170 : 24|8@1+ (1,0) [0|255] "" Vector__XXX
 SG_ LineColour m171 : 24|8@1+ (1,0) [0|255] "" Vector__XXX
 SG_ FillType m172 : 24|8@1+ (1,0) [0|255] "" Vector__XXX
 SG_ NewActiveMaskObjectID m173 : 24|16@1+ (1,0) [0|65535] "" Vector__XXX
 SG_ StringVariableObjectID m181 : 24|16@1+ (1,0) [0|65535] "" Vector__XXX
 SG_ IndexOfThePointToReplace m182 : 24|8@1+ (1,0) [0|255] "" Vector__XXX
 SG_ AttributeIDToChange m175 : 24|8@1+ (1,0) [0|0] "" Vector__XXX
 SG_ TotalNumberOfBytes m179 : 24|16@1- (1,0) [0|0] "bytes" Vector__XXX
 SG_ ObjectId_2 m9 : 32|16@1+ (1,0) [0|65535] "" Vector__XXX
 SG_ AuxErrorInvalidInputID m37 : 32|1@1+ (1,0) [0|1] "" Vector__XXX
 SG_ OnTimeDuration_Audio m163 : 32|16@1+ (1,0) [0|65535] "ms" Vector__XXX
 SG_ NewValue m168 : 32|32@1+ (1,0) [0|65535] "" Vector__XXX
 SG_ FontSize m170 : 32|8@1+ (1,0) [0|255] "" Vector__XXX
 SG_ LineWidth m171 : 32|8@1+ (1,0) [0|255] "" Vector__XXX
 SG_ FillColour m172 : 32|8@1+ (1,0) [0|255] "" Vector__XXX
 SG_ NewSoftKeyMaskObjectID m174 : 32|16@1+ (1,0) [0|65535] "" Vector__XXX
 SG_ NewAttributeValue m175 : 32|32@1+ (1,0) [0|0] "" Vector__XXX
 SG_ NewValueX m182 : 32|16@1+ (1,0) [0|65535] "" Vector__XXX
 SG_ LockTimeout m189 : 32|16@1+ (1,0) [0|65535] "" Vector__XXX
 SG_ PictureGraphicsID_Viewport m20 : 32|16@1+ (1,0) [0|65534] "" Vector__XXX
 SG_ PictureGraphicsID_Canvas m19 : 32|16@1+ (1,0) [0|65534] "" Vector__XXX
 SG_ ObjectID m18 : 32|16@1+ (1,0) [0|65534] "" Vector__XXX
 SG_ NewViewportWidth m17 : 32|16@1+ (1,0) [0|65535] "" Vector__XXX
 SG_ ViewportX_PanZoom m16 : 32|16@1- (1,0) [-32768|32767] "" Vector__XXX
 SG_ ZoomValue m15 : 32|32@1- (1,0) [-32|32] "" Vector__XXX
 SG_ ViewportX m14 : 32|16@1- (1,0) [-32768|32767] "" Vector__XXX
 SG_ TextOption m13 : 32|8@1+ (1,0) [0|1] "" Vector__XXX
 SG_ NumberOfPoints m12 : 32|8@1+ (1,0) [0|255] "" Vector__XXX
 SG_ EllipseWidth m11 : 32|16@1+ (1,0) [0|65535] "" Vector__XXX
 SG_ RectangleWidth_Draw m10 : 32|16@1+ (1,0) [0|65535] "" Vector__XXX
 SG_ EndPixelOffsetX m9 : 32|16@1- (1,0) [-32768|32767] "" Vector__XXX
 SG_ PixelOffsetX m8 : 32|16@1- (1,0) [-32768|32767] "" Vector__XXX
 SG_ RectangleHeight_Erase m7 : 48|16@1+ (1,0) [0|65535] "" Vector__XXX
 SG_ RectangleWidth_Erase m7 : 32|16@1+ (1,0) [0|65535] "" Vector__XXX
 SG_ FontAttributesObjectID m6 : 32|16@1+ (1,0) [0|65535] "" Vector__XXX
 SG_ FillAttributesObjectID m5 : 32|16@1+ (1,0) [0|65535] "" Vector__XXX
 SG_ LineAttributesObjectID m4 : 32|16@1+ (1,0) [0|65535] "" Vector__XXX
 SG_ BackgroundColour m3 : 32|8@1+ (1,0) [0|255] "" Vector__XXX
 SG_ ForegroundColour m2 : 32|8@1+ (1,0) [0|255] "" Vector__XXX
 SG_ LeftAID m1 : 32|8@1+ (1,0) [0|255] "" Vector__XXX
 SG_ ImmediateOperandValue m0 : 40|32@1+ (1,0) [0|0] "" Vector__XXX
 SG_ RightObjectID m1 : 40|16@1+ (1,0) [0|65535] "" Vector__XXX
 SG_ CursorOffsetX m1 : 32|16@1- (1,0) [-32768|32767] "" Vector__XXX
 SG_ CursorPosX m0 : 32|16@1- (1,0) [-32768|32767] "" Vector__XXX
 SG_ AuxErrorAnyOther m37 : 33|1@1+ (1,0) [0|1] "" Vector__XXX
 SG_ TextLength m13 : 40|8@1+ (1,0) [0|255] "bytes" Vector__XXX
 SG_ XPosChangeTopLeft m165 : 40|8@1+ (1,-127) [-127|128] "" Vector__XXX
 SG_ NewHeight m166 : 40|16@1+ (1,0) [0|65535] "" Vector__XXX
 SG_ Height m169 : 40|16@1+ (1,0) [0|65535] "" Vector__XXX
 SG_ LabelFontType m181 : 40|8@1+ (1,0) [0|255] "" Vector__XXX
 SG_ LineArt m171 : 40|16@1+ (1,0) [0|65535] "" Vector__XXX
 SG_ FillPatternObjectID m172 : 40|16@1+ (1,0) [0|65535] "" Vector__XXX
 SG_ XPosChangeTopLeftLong m180 : 40|16@1- (1,0) [-32768|32767] "" Vector__XXX
 SG_ FontType m170 : 40|8@1+ (1,0) [0|255] "" Vector__XXX
 SG_ NewStringValue m179 : 40|16@1+ (1,0) [0|65535] "" Vector__XXX
 SG_ CursorPosY m0 : 48|16@1- (1,0) [-32768|32767] "" Vector__XXX
 SG_ CursorOffsetY m1 : 48|16@1- (1,0) [-32768|32767] "" Vector__XXX
 SG_ PixelOffsetY m8 : 48|16@1- (1,0) [-32768|32767] "" Vector__XXX
 SG_ EndPixelOffsetY m9 : 48|16@1- (1,0) [-32768|32767] "" Vector__XXX
 SG_ RectangleHeight_Draw m10 : 48|16@1+ (1,0) [0|65535] "" Vector__XXX
 SG_ EllipseHeight m11 : 48|16@1+ (1,0) [0|65535] "" Vector__XXX
 SG_ ViewportY m14 : 48|16@1- (1,0) [-32768|32767] "" Vector__XXX
 SG_ ViewportY_PanZoom m16 : 48|16@1- (1,0) [-32768|32767] "" Vector__XXX
 SG_ NewViewportHeight m17 : 48|16@1+ (1,0) [0|65535] "" Vector__XXX
 SG_ OffTimeDuration_Audio m163 : 48|16@1+ (1,0) [0|65535] "ms" Vector__XXX
 SG_ YPosChangeTopLeft m165 : 48|8@1+ (1,-127) [-127|128] "" Vector__XXX
 SG_ FontStyle m170 : 48|8@1+ (1,0) [0|255] "" Vector__XXX
 SG_ GraphicRepresentationObjectID m181 : 48|16@1+ (1,0) [0|255] "" Vector__XXX
 SG_ NewValueY m182 : 48|16@1+ (1,0) [0|65535] "" Vector__XXX
 SG_ LineDirection m169 : 56|8@1+ (1,0) [0|1] "" Vector__XXX
 SG_ YPosChangeTopLeftLong m180 : 56|16@1- (1,0) [-32768|32767] "" Vector__XXX
 SG_ RightAID m1 : 56|8@1+ (1,0) [0|255] "" Vector__XXX
 SG_ ZoomValue_PanZoom m16 : 64|32@1- (1,0) [-32|32] "" Vector__XXX
 SG_ NotificationValue1 m0 : 72|16@1+ (1,0) [0|65535] "" Vector__XXX
 SG_ ThenMacroObjectID m31 : 72|16@1+ (1,0) [0|65535] "" Vector__XXX
 SG_ ModelIdentificationCode m34 : 80|16@1+ (1,0) [0|65535] "" Vector__XXX
 SG_ NotificationValue2 m0 : 88|16@1+ (1,0) [0|65535] "" Vector__XXX
 SG_ ElseMacroObjectID m31 : 88|16@1+ (1,0) [0|65535] "" Vector__XXX
 SG_ NumOfPreferredFunctions m34 : 96|8@1- (1,0) [0|255] "" Vector__XXX
 SG_ AuxiliaryFunctionID_1 m34 : 104|16@1+ (1,0) [0|65535] "" Vector__XXX
 SG_ AuxiliaryInputID_1 m34 : 120|16@1+ (1,0) [0|65535] "" Vector__XXX

CM_ BO_ 2583299070 "This PGN provides a single Trans containing GNSS status and dilution of precision components(DOP)that indicate contribution of satellite geometry to overall Posing error.There are three DOP parameters reported,horizontal(HDOP),Vertical(VDOP)and time(TDOP)";
CM_ SG_ 2583299070 TDOP "Dilution of Precision(DOP)indicates contribution of satellite Config geometry to Posing error.A lower DOP value is preferred because less error is being introduced.Reported as components:HDOP(Horizontal),VDOP(Vertical),TDOP(Time).Min DOP value is 1.0(no e";
CM_ SG_ 2583299070 VDOP "Dilution of Precision(DOP)indicates contribution of satellite Config geometry to Posing error.A lower DOP value is preferred because less error is being introduced.Reported as components:HDOP(Horizontal),VDOP(Vertical),TDOP(Time).Min DOP value is 1.0(no e";
CM_ SG_ 2583299070 HDOP_ "Dilution of Precision(DOP)indicates contribution of satellite Config geometry to Posing error.A lower DOP value is preferred because less error is being introduced.Reported as components:HDOP(Horizontal),VDOP(Vertical),TDOP(Time).Min DOP value is 1.0(no e";
CM_ SG_ 2583299070 OpMode "0 = 1D, 
 1 = 2D, 
 2 = 3D, 
 3 = Auto, 
4-5 = Reserved, 
 6 = Error, 
 7 = Null";
CM_ SG_ 2583299070 SetMode "0 = 1D, 
 1 = 2D, 
 2 = 3D, 
 3 = Auto, 
4-5 = Reserved, 
 6 = Error, 
 7 = Null";
CM_ SG_ 2583299070 SID "An upward counting number used to tie related information together between different PGNs.For example,SID would be used to tie together COG,SOG and RAIM values to a given Pos.255=no valid Pos fix to tie it to.Range 0 to 250 for valid Pos fixes.";
CM_ BO_ 2583298814 "GNSS common satellite receiver parameter status";
CM_ SG_ 2583298814 UseAntennaAltitudeFor2DMode "MSB/LSB: 
00 = [No, Off, Disabled, Reset, '0'], 
01 = [Yes, On, Enabled, Set, '1'], 
10 = Error, 
11= [Unavailable, Unknown]";
CM_ SG_ 2583298814 MaxCorrectionAge "Age of Differential corrections";
CM_ SG_ 2583298814 Pos_VelocityFilter "MSB/LSB: 
00 = [No, Off, Disabled, Reset, '0'], 
01 = [Yes, On, Enabled, Set, '1'], 
10 = Error, 
11= [Unavailable, Unknown]";
CM_ SG_ 2583298814 DGNSSMode "0 = Off,
1 = Auto,
2 = RTCM SC104 Pseudorange Corrections,
3 = RTCA SC159 Network Corrections,
4 = RTK Differential Corrections,
5 = Reserved,
6 = Error; 
7 = Null";
CM_ SG_ 2583298814 GNSSMode "0 = 1D, 
 1 = 2D, 
 2 = 3D, 
 3 = Auto, 
4-5 = Reserved, 
 6 = Error, 
 7 = Null";
CM_ SG_ 2583298814 PDOPSwitch "Dilution of Precision(DOP)indicates contribution of satellite Config geometry to Posing error.A lower DOP value is preferred because less error is being introduced.Reported as components:HDOP(Horizontal),VDOP(Vertical),TDOP(Time).Min DOP value is 1.0(no e";
CM_ SG_ 2583298814 PDOPMask "Dilution of Precision(DOP)indicates contribution of satellite Config geometry to Posing error.A lower DOP value is preferred because less error is being introduced.Reported as components:HDOP(Horizontal),VDOP(Vertical),TDOP(Time).Min DOP value is 1.0(no e";
CM_ SG_ 2583298814 SVElevationMask "Angle above or below the horizon. -90° to +90°; negative below the horizon";
CM_ BO_ 2583303422 "This PGN provides a single Trans that contains relevant almanac data for Glonass products.almanac contains satellite vehicle coursebital parameters.This information is not considered precise and is only valid for several months at a time.Glonass products ";
CM_ SG_ 2583303422 tnA2 "Course value of the time scale shift, reference GLONASS ICD Section 4.5 Table 4.3 (fill unused bits with zeros).";
CM_ SG_ 2583303422 tcA "System time scale correction, reference GLONASS ICD Section 4.5 Table 4.3 (fill unused bits with zeros).";
CM_ SG_ 2583303422 inA "Correction to the average value of the inclination angle, reference GLONASS ICD Section 4.5 Table 4.3 (fill unused bits with zeros).";
CM_ SG_ 2583303422 nA3 "Greenwich longitude of the ascension node, reference GLONASS ICD Section 4.5 Table 4.3 (fill unused bits with zeros).";
CM_ SG_ 2583303422 tnA "Time of the ascension node, almanac reference time, reference GLONASS ICD Section 4.5 Table 4.3 (fill unused bits with zeros).";
CM_ SG_ 2583303422 TnA "Correction to the average value of the draconitic circling time, reference GLONASS ICD Section 4.5 Table 4.3 (fill unused bits with zeros).";
CM_ SG_ 2583303422 nA2 "Argument of Perigee, reference GLONASS ICD Section 4.5 Table 4.3 (fill unused bits with zeros).";
CM_ SG_ 2583303422 DOT "Rate of change of the draconitic circling time, reference GLONASS ICD Section 4.5 Table 4.3 (fill unused bits with zeros).";
CM_ SG_ 2583303422 nA "Eccentricity, reference GLONASS ICD Section 4.5 Table 4.3 (fill unused bits with zeros).";
CM_ SG_ 2583303422 HnA "Carrier frequency number respectively, reference GLONASS ICD.";
CM_ SG_ 2583303422 CnA "Generalized health of the Satellite, reference GLONASS ICD.";
CM_ SG_ 2583303422 NA "Calendar day count within the four year period beginning with the previous leap year";
CM_ SG_ 2583303422 PRN "0 = value not used,
  1-32 = GPS,
33-64 = SBAS,Satellite,Based Augmentation System(ie WAAS)
65-96 = GLONASS.
For GLONASS,satellites are identified by 64+satellite slot number.slot numbers are 1 through 24 for full GLONASS constellation of 24 satellite";
CM_ BO_ 2582778366 "Fluid Level contains an instance number, type of fluid, level of fluid, and tank capacity.  For example the fluid instance may be the level of fuel in a tank or the level of water in the bilge.  Used primarily by display or instrumentation devices.";
CM_ SG_ 2582778366 FluidType "0x00 = Fuel,
0x01 = Fresh Water,
0x02 = Waste Water,
0x03 = Live Well,
0x04 = Oil, 
0x05 = Black Water (Sewage)
0x06 = Reserved,
  thru
0x0D = Reserved,
0x0E = Error, 
0x0F = Data not available";
CM_ SG_ 2582778366 FluidInstance "0x0 to 0xF = Instance number 0 to 15;";
CM_ BO_ 2516387838 "Environmental Conditions contains Temperature, Humidity, and Atmospheric Pressure.  This PGN is a rework of PGN 130310 and is to be used for new designs.";
CM_ SG_ 2516387838 HumidityInstance "0x00 = Inside Humidity,
0x01 = Outside Humidity,
0x02 = reserved,
0x03 = Data Not Available";
CM_ SG_ 2516387838 TempInstance "0x00 = Sea Temperature,
0x01 = Outside Temperature,
0x02 = Inside Temperature,
0x03 = Engine Room Temperature,
0x04 = Main Cabin Temperature,
0x05 = Reserve,
 thru
0x3E = Reserve,
0x3F = Data Not Available";
CM_ SG_ 2516387838 SequenceID_ "An upward counting number used to tie related information together between different PGNs.For example,SID would be used to tie together COG,SOG and RAIM values to a given Pos.255=no valid Pos fix to tie it to.Range 0 to 250 for valid Pos fixes.";
CM_ BO_ 2516387582 "Local atmospheric environmental conditions";
CM_ SG_ 2516387582 SequenceID_ "An upward counting number used to tie related information together between different PGNs.For example,SID would be used to tie together COG,SOG and RAIM values to a given Pos.255=no valid Pos fix to tie it to.Range 0 to 250 for valid Pos fixes.";
CM_ BO_ 2515667710 "Provides identification information and rated engine speed for the engine indicated by the engine instance field. Used primarily by display devices.";
CM_ SG_ 2515667710 VIN "Name of place, route, waypoint, destination, vessel, vehicle, etc.";
CM_ SG_ 2515667710 EngInstance "For Engs:
0 = Instance 0;          0 = Single Eng Dual Eng Port
1 = Instance 1;          1 = Dual Eng StarBoard  
                                  (for Multiple Engs,Instances will start 
        thru                            from Bow,Port(0)to Ste";
CM_ BO_ 2314338558 "Provides data with a high update rate for a specific engine in a single frame message.  The first field provides information as to which engine.  This PGN if  used with PGN 127489 will provide most Engine data.";
CM_ SG_ 2314338558 EngInstance "For Engs:
0 = Instance 0;          0 = Single Eng Dual Eng Port
1 = Instance 1;          1 = Dual Eng StarBoard  
                                  (for Multiple Engs,Instances will start 
        thru                            from Bow,Port(0)to Ste";
CM_ BO_ 2314338814 "Used to provide real-time operational data and status relevant to a specific engine,  indicated by the engine instance field.  This message would normally be broadcasted periodically to provide information for instrumentation or control functions.";
CM_ SG_ 2314338814 EngDiscreteStatus2 "xxxx xxxx xxxx xxx1 = Warning Level 1,
xxxx xxxx xxxx xx1x = Warning Level 2,
xxxx xxxx xxxx x1xx = Power Reduction,
xxxx xxxx xxxx 1xxx = Maintenance Needed,
xxxx xxxx xxx1 xxxx = Eng Comm Error,
xxxx xxxx xx1x xxxx = Sub Second Throttle,
xxxx xxxx";
CM_ SG_ 2314338814 EngDiscreteStatus1 "xxxx xxxx  xxxx xxx1 = Check Eng,
xxxx xxxx  xxxx xx1x = Over Temp,
xxxx xxxx  xxxx x1xx = Low Oil Press,
xxxx xxxx  xxxx 1xxx = Low Oil Level,
xxxx xxxx  xxx1 xxxx = Low Fuel Press,
xxxx xxxx  xx1x xxxx = Low System Voltage,
xxxx xxxx  x1xx xxxx = ";
CM_ SG_ 2314338814 EngInstance "For Engs:
0 = Instance 0;          0 = Single Eng Dual Eng Port
1 = Instance 1;          1 = Dual Eng StarBoard  
                                  (for Multiple Engs,Instances will start 
        thru                            from Bow,Port(0)to Ste";
CM_ BO_ 2582975486 "This PGN provides cumulative voyage distance traveled since last reset.distance is tagged with time and date of distance measurement.distances through water are accumulated and values stored during power down and resume counting after power up.
  
-Tota";
CM_ SG_ 2582975486 MeasurementTime "24 hour clock, 0 =  midnight,  time is in UTC";
CM_ SG_ 2582975486 MeasurementDate "Days since January 1, 1970,   Date is relative to UTC Time.";
CM_ BO_ 2382238206 "purpose of this PGN is to group three fundamental vectors related to vessel motion,

-Speed and heading referenced to water
-Speed and course referenced to ground
-Current speed and flow direction

Products that are primary form of navigation would ";
CM_ SG_ 2382238206 Set "Direction towards which current flows.  Degrees relative to True North.";
CM_ SG_ 2382238206 Heading "The horizontal direction in which a ship actually points or heads at any instant, expressed in angular units from a reference direction, usually from 000 at the reference direction clockwise through 359 degrees.";
CM_ SG_ 2382238206 CourseOverGround "The direction of the path over ground actually followed by a vessel.";
CM_ SG_ 2382238206 SID "An upward counting number used to tie related information together between different PGNs.For example,SID would be used to tie together COG,SOG and RAIM values to a given Pos.255=no valid Pos fix to tie it to.Range 0 to 250 for valid Pos fixes.";
CM_ SG_ 2382238206 Set_COG_HeadingRef "0 = True, 
1 = Magnetic, 
2 = Error, 
3 = Null";
CM_ SG_ 2382238206 DataMode "0x0 = Autonomous mode, 
0x1 = Differential, enhanced mode, 
0x2 = Estimated mode, 
0x3 = Simulator mode, 
0x4 = Manual mode, 
0xE = Error, 
0xF = Data not available";
CM_ BO_ 2583172350 "Local geodetic datum and datum offsets from a reference datum. This PGN is used to define the datum to which a position location output by the same device in other PGNs is referenced.";
CM_ SG_ 2583172350 LocalDatum "4-character code for datum currently being output for Pos solution.datum's are defined in IHO Publication S-60,Appendices B and C.first three chars are datum ID as per IHO tables.fourth char is local datum subdivision code.A null char indicates datum subd";
CM_ BO_ 2449150206 "This PGN provides Digital Selective Calling(DSC)data according to ITU M.493-9 with optional expansion according to ITU M.821-1.
DSC is a paging system that is used to automate distress alerts sent over terrestrial communication systems such as VHF,MF and";
CM_ SG_ 2449150206 DSCMsgAddress "Individual characters having only decimal values in range 0 to 127 for DSC symbols defined by ITU-R M.493 are used to code address geographic area as defined in ITU-R M.493-9 Section 5.This may represent an individual MMSI,a group MMSI,or a geographic are";
CM_ SG_ 2449150206 DSCCategorySymbol "Integer numbers within the range 000 to 127 representing DSC Symbols defined by ITU-R M.493 Table 3 for: Phasing and Unique Functions; Format Specifier; Category; Nature of Distress; First Telecommand; Second Telecommand";
CM_ SG_ 2449150206 DSCFormatSymbol "Integer numbers within the range 000 to 127 representing DSC Symbols defined by ITU-R M.493 Table 3 for: Phasing and Unique Functions; Format Specifier; Category; Nature of Distress; First Telecommand; Second Telecommand";
CM_ BO_ 2583301630 "This PGN provides a means to pass Diff GNSS corrections between NMEA 2000 devices.Passing DGNSS data this way allows for more flexibility than traditional methods.One Diff correction receiver could supply multiple GNSS receivers.Multiple Diff correction r";
CM_ SG_ 2583301630 IOD "Number of route, waypoint, event, mark, etc.";
CM_ SG_ 2583301630 UDRE "Dependent upon PG Field definition.";
CM_ SG_ 2583301630 SatelliteID "0 = value not used,
  1-32 = GPS,
33-64 = SBAS,Satellite,Based Augmentation System(ie WAAS)
65-96 = GLONASS.
For GLONASS,satellites are identified by 64+satellite slot number.slot numbers are 1 through 24 for full GLONASS constellation of 24 satellite";
CM_ SG_ 2583301630 StationHealth "0x00 = Not Working,
0x01 = Unmonitored,
0x02 = Healthy & Operational,
0x03 = Healthy & in Test Mode,
0x04 = In Test Mode - DO NOT USE,
0x05 - 0x15 = Reserved";
CM_ SG_ 2583301630 ReferenceStationType "Reference Station Type. 
0x0=GPS; 
0x1=GLONASS; 
0x3 to 0xD=Reserved; 
0XE=Error; 
0XF=Null";
CM_ SG_ 2583301630 ReferenceStationID "Reference Station ID.  Reference Station number as provided by the Service Provider.[Reference document required]";
CM_ SG_ 2583301630 SequenceID_ "An upward counting number used to tie related information together between different PGNs.For example,SID would be used to tie together COG,SOG and RAIM values to a given Pos.255=no valid Pos fix to tie it to.Range 0 to 250 for valid Pos fixes.";
CM_ BO_ 2583499518 "Current station measurement data including station location, numeric identifier, and name.";
CM_ SG_ 2583499518 StationIDString "Name of place, route, waypoint, destination, vessel, vehicle, etc.";
CM_ SG_ 2583499518 CurrentFlowDirection "Direction towards which current flows.  Degrees relative to True North.";
CM_ SG_ 2583499518 MeasurementDepth "Water depth measured from the water surface";
CM_ SG_ 2583499518 MeasurementTime "24 hour clock, 0 =  midnight,  time is in UTC";
CM_ SG_ 2583499518 MeasurementDate "Days since January 1, 1970,   Date is relative to UTC Time.";
CM_ SG_ 2583499518 State "000 = Flood, 
001 = Slack, 
010 = Ebb, 
011 = Reserved, 
100 = Reserved, 
101 = Reserved, 
110 = Error, 
111 = Unavailable, Unknown";
CM_ SG_ 2583499518 Mode "Range Residual used in position calculation or range residuals were calculated after the position.  
0=range residuals were used to calculate data; 
1=range residuals were calculated after the position., 
2=Error, 
3=Null";
CM_ BO_ 2381906942 "This PGN provides the magnitude of position error perpendicular to the desired course.";
CM_ SG_ 2381906942 XTE "Cross-track-error of a route.  '-' = Left of track, need to steer right";
CM_ SG_ 2381906942 NavigationTerminated "MSB/LSB: 
00 = [No, Off, Disabled, Reset, '0'], 
01 = [Yes, On, Enabled, Set, '1'], 
10 = Error, 
11= [Unavailable, Unknown]";
CM_ SG_ 2381906942 XTEMode "0x0 = Autonomous mode, 
0x1 = Differential, enhanced mode, 
0x2 = Estimated mode, 
0x3 = Simulator mode, 
0x4 = Manual mode, 
0xE = Error, 
0xF = Data not available";
CM_ SG_ 2381906942 SID "An upward counting number used to tie related information together between different PGNs.For example,SID would be used to tie together COG,SOG and RAIM values to a given Pos.255=no valid Pos fix to tie it to.Range 0 to 250 for valid Pos fixes.";
CM_ BO_ 2582648574 "Free-form alphanumeric fields describing the installation  (e.g., starboard engine room location) of the device and installation notes (e.g., calibration data)";
CM_ SG_ 2582648574 InstallationDescriptionField1 "Name of place, route, waypoint, destination, vessel, vehicle, etc.";
CM_ BO_ 2583238398 "Bearing and distance from the origin mark to the destination mark, calculated at the origin mark, for any two arbitrary generic marks. The calculation type (Rhumb Line, Great Circle) is specified, as well as the bearing reference (Mag, True).";
CM_ SG_ 2583238398 DestinationMarkID "Number of route, waypoint, event, mark, etc.";
CM_ SG_ 2583238398 OriginMarkId "Number of route, waypoint, event, mark, etc.";
CM_ SG_ 2583238398 DestinationMarkType "0   = Collision, 
  1   = Turning Point, 
  2   = Reference (general), 
  3   = Wheelover, 
  4   = Waypoint, 
5-13 = Reserved, 
 14  = Error, 
 15  = Null";
CM_ SG_ 2583238398 OriginMarkType "0   = Collision, 
  1   = Turning Point, 
  2   = Reference (general), 
  3   = Wheelover, 
  4   = Waypoint, 
5-13 = Reserved, 
 14  = Error, 
 15  = Null";
CM_ SG_ 2583238398 BearingiginToDestination "The horizontal direction of one terrestrial point from another, expressed as the angular distance from a reference direction, measured from 000 at the reference direction clockwise through 359 degrees.";
CM_ SG_ 2583238398 CalculationType "0 = Great Circle calculations, 
1 = Rhumb Line calculations, 
2 = Error, 
3 = Null";
CM_ SG_ 2583238398 BearingRef "0 = True, 
1 = Magnetic, 
2 = Error, 
3 = Null";
CM_ SG_ 2583238398 SID "An upward counting number used to tie related information together between different PGNs.For example,SID would be used to tie together COG,SOG and RAIM values to a given Pos.255=no valid Pos fix to tie it to.Range 0 to 250 for valid Pos fixes.";
CM_ BO_ 2381450750 "Universal status report for multiple banks of two-state indicators.";
CM_ SG_ 2381450750 Indic28 "MSB/LSB: 
00 = [No, Off, Disabled, Reset, '0'], 
01 = [Yes, On, Enabled, Set, '1'], 
10 = Error, 
11= [Unavailable, Unknown]";
CM_ SG_ 2381450750 Indic27 "MSB/LSB: 
00 = [No, Off, Disabled, Reset, '0'], 
01 = [Yes, On, Enabled, Set, '1'], 
10 = Error, 
11= [Unavailable, Unknown]";
CM_ SG_ 2381450750 Indic26 "MSB/LSB: 
00 = [No, Off, Disabled, Reset, '0'], 
01 = [Yes, On, Enabled, Set, '1'], 
10 = Error, 
11= [Unavailable, Unknown]";
CM_ SG_ 2381450750 Indic25 "MSB/LSB: 
00 = [No, Off, Disabled, Reset, '0'], 
01 = [Yes, On, Enabled, Set, '1'], 
10 = Error, 
11= [Unavailable, Unknown]";
CM_ SG_ 2381450750 Indic24 "MSB/LSB: 
00 = [No, Off, Disabled, Reset, '0'], 
01 = [Yes, On, Enabled, Set, '1'], 
10 = Error, 
11= [Unavailable, Unknown]";
CM_ SG_ 2381450750 Indic23 "MSB/LSB: 
00 = [No, Off, Disabled, Reset, '0'], 
01 = [Yes, On, Enabled, Set, '1'], 
10 = Error, 
11= [Unavailable, Unknown]";
CM_ SG_ 2381450750 Indic22 "MSB/LSB: 
00 = [No, Off, Disabled, Reset, '0'], 
01 = [Yes, On, Enabled, Set, '1'], 
10 = Error, 
11= [Unavailable, Unknown]";
CM_ SG_ 2381450750 Indic21 "MSB/LSB: 
00 = [No, Off, Disabled, Reset, '0'], 
01 = [Yes, On, Enabled, Set, '1'], 
10 = Error, 
11= [Unavailable, Unknown]";
CM_ SG_ 2381450750 Indic20 "MSB/LSB: 
00 = [No, Off, Disabled, Reset, '0'], 
01 = [Yes, On, Enabled, Set, '1'], 
10 = Error, 
11= [Unavailable, Unknown]";
CM_ SG_ 2381450750 Indic19 "MSB/LSB: 
00 = [No, Off, Disabled, Reset, '0'], 
01 = [Yes, On, Enabled, Set, '1'], 
10 = Error, 
11= [Unavailable, Unknown]";
CM_ SG_ 2381450750 Indic18 "MSB/LSB: 
00 = [No, Off, Disabled, Reset, '0'], 
01 = [Yes, On, Enabled, Set, '1'], 
10 = Error, 
11= [Unavailable, Unknown]";
CM_ SG_ 2381450750 Indic17 "MSB/LSB: 
00 = [No, Off, Disabled, Reset, '0'], 
01 = [Yes, On, Enabled, Set, '1'], 
10 = Error, 
11= [Unavailable, Unknown]";
CM_ SG_ 2381450750 Indic16 "MSB/LSB: 
00 = [No, Off, Disabled, Reset, '0'], 
01 = [Yes, On, Enabled, Set, '1'], 
10 = Error, 
11= [Unavailable, Unknown]";
CM_ SG_ 2381450750 Indic15 "MSB/LSB: 
00 = [No, Off, Disabled, Reset, '0'], 
01 = [Yes, On, Enabled, Set, '1'], 
10 = Error, 
11= [Unavailable, Unknown]";
CM_ SG_ 2381450750 Indic14 "MSB/LSB: 
00 = [No, Off, Disabled, Reset, '0'], 
01 = [Yes, On, Enabled, Set, '1'], 
10 = Error, 
11= [Unavailable, Unknown]";
CM_ SG_ 2381450750 Indic13 "MSB/LSB: 
00 = [No, Off, Disabled, Reset, '0'], 
01 = [Yes, On, Enabled, Set, '1'], 
10 = Error, 
11= [Unavailable, Unknown]";
CM_ SG_ 2381450750 Indic12 "MSB/LSB: 
00 = [No, Off, Disabled, Reset, '0'], 
01 = [Yes, On, Enabled, Set, '1'], 
10 = Error, 
11= [Unavailable, Unknown]";
CM_ SG_ 2381450750 Indic11 "MSB/LSB: 
00 = [No, Off, Disabled, Reset, '0'], 
01 = [Yes, On, Enabled, Set, '1'], 
10 = Error, 
11= [Unavailable, Unknown]";
CM_ SG_ 2381450750 Indic10 "MSB/LSB: 
00 = [No, Off, Disabled, Reset, '0'], 
01 = [Yes, On, Enabled, Set, '1'], 
10 = Error, 
11= [Unavailable, Unknown]";
CM_ SG_ 2381450750 Indic9 "MSB/LSB: 
00 = [No, Off, Disabled, Reset, '0'], 
01 = [Yes, On, Enabled, Set, '1'], 
10 = Error, 
11= [Unavailable, Unknown]";
CM_ SG_ 2381450750 Indic8 "MSB/LSB: 
00 = [No, Off, Disabled, Reset, '0'], 
01 = [Yes, On, Enabled, Set, '1'], 
10 = Error, 
11= [Unavailable, Unknown]";
CM_ SG_ 2381450750 Indic7 "MSB/LSB: 
00 = [No, Off, Disabled, Reset, '0'], 
01 = [Yes, On, Enabled, Set, '1'], 
10 = Error, 
11= [Unavailable, Unknown]";
CM_ SG_ 2381450750 Indic6 "MSB/LSB: 
00 = [No, Off, Disabled, Reset, '0'], 
01 = [Yes, On, Enabled, Set, '1'], 
10 = Error, 
11= [Unavailable, Unknown]";
CM_ SG_ 2381450750 Indic5 "MSB/LSB: 
00 = [No, Off, Disabled, Reset, '0'], 
01 = [Yes, On, Enabled, Set, '1'], 
10 = Error, 
11= [Unavailable, Unknown]";
CM_ SG_ 2381450750 Indic4 "MSB/LSB: 
00 = [No, Off, Disabled, Reset, '0'], 
01 = [Yes, On, Enabled, Set, '1'], 
10 = Error, 
11= [Unavailable, Unknown]";
CM_ SG_ 2381450750 Indic3 "MSB/LSB: 
00 = [No, Off, Disabled, Reset, '0'], 
01 = [Yes, On, Enabled, Set, '1'], 
10 = Error, 
11= [Unavailable, Unknown]";
CM_ SG_ 2381450750 Indic2 "MSB/LSB: 
00 = [No, Off, Disabled, Reset, '0'], 
01 = [Yes, On, Enabled, Set, '1'], 
10 = Error, 
11= [Unavailable, Unknown]";
CM_ SG_ 2381450750 Indic1 "MSB/LSB: 
00 = [No, Off, Disabled, Reset, '0'], 
01 = [Yes, On, Enabled, Set, '1'], 
10 = Error, 
11= [Unavailable, Unknown]";
CM_ SG_ 2381450750 IndicatorBankInstance "Number of route, waypoint, event, mark, etc.";
CM_ BO_ 2582779134 "Provides parametric data for a specific battery, indicated by the battery instance field. Used primarily by display or instrumentation devices, but may also be used by battery management controls.";
CM_ SG_ 2582779134 SID "An upward counting number used to tie related information together between different PGNs.For example,SID would be used to tie together COG,SOG and RAIM values to a given Pos.255=no valid Pos fix to tie it to.Range 0 to 250 for valid Pos fixes.";
CM_ SG_ 2582779134 BatteryCurrent "+ = current consumed, - = current supplied";
CM_ SG_ 2582779134 BatteryInstance "Number of route, waypoint, event, mark, etc.";
CM_ BO_ 2381388286 "This PGN provides a single Trans that describes Pos of a vessel relative to both horizontal and vertical planes.This would typically be used for vessel stabilization,vessel Ctrl and onboard platform stabilization.

Products that directly interface to pi";
CM_ SG_ 2381388286 Roll "Oscillation of ship about it's longitudinal axis.  Roll to the starboard is positive.";
CM_ SG_ 2381388286 Pitch_ "Oscillation of ship about it's latitudinal axis.  Bow moving up is positive.";
CM_ SG_ 2381388286 Yaw "Oscillation of ship about it's vertical axis.  Bow moving to starboard is positive.";
CM_ SG_ 2381388286 SID "An upward counting number used to tie related information together between different PGNs.For example,SID would be used to tie together COG,SOG and RAIM values to a given Pos.255=no valid Pos fix to tie it to.Range 0 to 250 for valid Pos fixes.";
CM_ BO_ 2314732798 "The'Altitude Delta,High Precision Rapid Update'Parameter Group is intended for Apps where very high precision and very fast update rates are needed for altitude and course over ground data.This PG can provide delta altitude changes down to 1 millimeter,a ";
CM_ SG_ 2314732798 CourseOverGround "The direction of the path over ground actually followed by a vessel.";
CM_ SG_ 2314732798 Direction "0 = True, 
1 = Magnetic, 
2 = Error, 
3 = Null";
CM_ SG_ 2314732798 GNSSQuality "0 = no GPS,
1 = GNSS fix,
2 = DGNSS fix,
3 = Precise GNSS*,
4 = RTK Fixed Integer,
5 = RTK Float,
6 = Est(DR)mode,
7 = Manual Input,
8 = Simulate mode,
9-13 = Reserved,
14 = Error,
15 = Null.*Precise GNSS means no deliberate degradation(such as";
CM_ SG_ 2314732798 SequenceID_ "An upward counting number used to tie related information together between different PGNs.For example,SID would be used to tie together COG,SOG and RAIM values to a given Pos.255=no valid Pos fix to tie it to.Range 0 to 250 for valid Pos fixes.";
CM_ BO_ 2650474750 "This parameter group provides data associated with ITU-R M.1371 Msg 10 UTC and Date Inquiry Msg used to Rq current UTC and date.An AIS device may generate this parameter group either upon receiving a VHF data link Msg 10,or upon receipt of an ISO NMEA Rq ";
CM_ SG_ 2650474750 DestinationID "Number of route, waypoint, event, mark, etc.";
CM_ SG_ 2650474750 AISTransceiverInformation "0 = Channel A VDL reception,
1 = Channel B VDL reception,
2 = Channel A VDL transmission,
3 = Channel B VDL transmission,
4 = Own information not broadcast,
5-31 = Reserved.";
CM_ SG_ 2650474750 SourceID "Number of route, waypoint, event, mark, etc.";
CM_ SG_ 2650474750 RepeatIndicator "Used by the repeater to indicate how many times a message has been repeated (range of 0 to 3).

0 = Default
1 = First retransmission
2 = Second retransmission
3 = Final retransmission

See ITU-R M.1371-1 for more information.";
CM_ SG_ 2650474750 MsgID "Message Identifier (range of 0 to 63).

See ITU-R M.1371-1 for more information.";
CM_ BO_ 2650472958 "This parameter group provides data from ITU-R M.1371 Msg 4 Base Station Report providing Pos,time,date,and current slot number of a base station,and 11 UTC and date Resp Msg providing current UTC and date if available.An AIS device may generate this param";
CM_ SG_ 2650472958 TypeOfElectronicPosingDevice "0=Undefined (default), 
1=GPS, 
2=GLONASS, 
3=Combined GPS/GLONASS, 
4=Loran-C, 
5=Chayka, 
6=Integrated Navigation System, 
7=Surveyed (Base Station), 
8-15=Reserve for future use.

See ITU-R M.1371-1 for more information.";
CM_ SG_ 2650472958 PosDate "Days since January 1, 1970,   Date is relative to UTC Time.";
CM_ SG_ 2650472958 AISTransceiverInformation "0 = Channel A VDL reception,
1 = Channel B VDL reception,
2 = Channel A VDL transmission,
3 = Channel B VDL transmission,
4 = Own information not broadcast,
5-31 = Reserved.";
CM_ SG_ 2650472958 CommunicationState "The Communication State contains information used by the various TDMA slot allocation algorithms and synchronization information

See ITU-R M.1371-1 for more information.";
CM_ SG_ 2650472958 PosTime "24 hour clock, 0 =  midnight,  time is in UTC";
CM_ SG_ 2650472958 RAIMflag "0 = RAIM not in use (default),
1 = RAIM in use

See ITU-R M.1371-1 for more information.";
CM_ SG_ 2650472958 PosAccuracy "0=low accuracy>10m such as nondifferential GNSS (default), 
1=high accuracy <10m such as DGNSS

See ITU-R M.1371-1 for more information.";
CM_ SG_ 2650472958 UserID "Number of route, waypoint, event, mark, etc.";
CM_ SG_ 2650472958 RepeatIndicator "Used by the repeater to indicate how many times a message has been repeated (range of 0 to 3).

0 = Default
1 = First retransmission
2 = Second retransmission
3 = Final retransmission

See ITU-R M.1371-1 for more information.";
CM_ SG_ 2650472958 MsgID "Message Identifier (range of 0 to 63).

See ITU-R M.1371-1 for more information.";
CM_ BO_ 2650475262 "This parameter group provides data associated with ITU-R M.1371 Msg 14 Safety Related Broadcast Msg supporting broadcast communication of safety related data.An AIS device may generate this parameter group either upon receiving a VHF data link Msg 14,or u";
CM_ SG_ 2650475262 SafetyRelatedText "Name of place, route, waypoint, destination, vessel, vehicle, etc.";
CM_ SG_ 2650475262 AISTransceiverInformation "0 = Channel A VDL reception,
1 = Channel B VDL reception,
2 = Channel A VDL transmission,
3 = Channel B VDL transmission,
4 = Own information not broadcast,
5-31 = Reserved.";
CM_ SG_ 2650475262 SourceID "Number of route, waypoint, event, mark, etc.";
CM_ SG_ 2650475262 RepeatIndicator "Used by the repeater to indicate how many times a message has been repeated (range of 0 to 3).

0 = Default
1 = First retransmission
2 = Second retransmission
3 = Final retransmission

See ITU-R M.1371-1 for more information.";
CM_ SG_ 2650475262 MsgID "Message Identifier (range of 0 to 63).

See ITU-R M.1371-1 for more information.";
CM_ BO_ 2650474238 "This parameter group provides data associated with ITU-R M.1371 Msg 9 SAR Aircraft Pos Report Msg for Airborne AIS units conducting Search and Rescue operations.An AIS device may generate this parameter group either upon receiving a VHF data link Msg 9,or";
CM_ SG_ 2650474238 DataTerminalEquipment "0=Available,
1=not available.

See ITU-R M.1371-1 for more information.";
CM_ SG_ 2650474238 AISTransceiverInformation "0 = Channel A VDL reception,
1 = Channel B VDL reception,
2 = Channel A VDL transmission,
3 = Channel B VDL transmission,
4 = Own information not broadcast,
5-31 = Reserved.";
CM_ SG_ 2650474238 CommunicationState "The Communication State contains information used by the various TDMA slot allocation algorithms and synchronization information

See ITU-R M.1371-1 for more information.";
CM_ SG_ 2650474238 COG "The direction of the path over ground actually followed by a vessel.";
CM_ SG_ 2650474238 TimeStamp "0-59=UTC second when report was generated,
60=time stamp not available(default),
61=Posing system is in manual input mode,
62=Electronic Pos fixing system operates in Est(dead reckoning)mode,
63=Posing system is inoperative

See ITU-R M.1371-1 for m";
CM_ SG_ 2650474238 RAIMFlag "0 = RAIM not in use (default),
1 = RAIM in use

See ITU-R M.1371-1 for more information.";
CM_ SG_ 2650474238 PosAccuracy "0=low accuracy>10m such as nondifferential GNSS (default), 
1=high accuracy <10m such as DGNSS

See ITU-R M.1371-1 for more information.";
CM_ SG_ 2650474238 UserID "Number of route, waypoint, event, mark, etc.";
CM_ SG_ 2650474238 RepeatIndicator "Used by the repeater to indicate how many times a message has been repeated (range of 0 to 3).

0 = Default
1 = First retransmission
2 = Second retransmission
3 = Final retransmission

See ITU-R M.1371-1 for more information.";
CM_ SG_ 2650474238 MsgID "Message Identifier (range of 0 to 63).

See ITU-R M.1371-1 for more information.";
CM_ BO_ 2650475518 "This parameter group provides data associated with ITU-R M.1371 Msg 15 Interrogation Msg used to Rq a specific ITU-R M.1371 Msg resulting in Resps from one more AIS mobile units.An AIS device may generate this parameter group either upon receiving a VHF d";
CM_ SG_ 2650475518 SlotOffset21 "Number of route, waypoint, event, mark, etc.";
CM_ SG_ 2650475518 MsgID21 "Message Identifier (range of 0 to 63).

See ITU-R M.1371-1 for more information.";
CM_ SG_ 2650475518 DestinationID2 "Number of route, waypoint, event, mark, etc.";
CM_ SG_ 2650475518 SlotOffset12 "Number of route, waypoint, event, mark, etc.";
CM_ SG_ 2650475518 MsgID12 "Message Identifier (range of 0 to 63).

See ITU-R M.1371-1 for more information.";
CM_ SG_ 2650475518 SlotOffset11 "Number of route, waypoint, event, mark, etc.";
CM_ SG_ 2650475518 MsgID11 "Message Identifier (range of 0 to 63).

See ITU-R M.1371-1 for more information.";
CM_ SG_ 2650475518 DestinationID1 "Number of route, waypoint, event, mark, etc.";
CM_ SG_ 2650475518 AISTransceiverInformation "0 = Channel A VDL reception,
1 = Channel B VDL reception,
2 = Channel A VDL transmission,
3 = Channel B VDL transmission,
4 = Own information not broadcast,
5-31 = Reserved.";
CM_ SG_ 2650475518 SourceID "Number of route, waypoint, event, mark, etc.";
CM_ SG_ 2650475518 RepeatIndicator "Used by the repeater to indicate how many times a message has been repeated (range of 0 to 3).

0 = Default
1 = First retransmission
2 = Second retransmission
3 = Final retransmission

See ITU-R M.1371-1 for more information.";
CM_ SG_ 2650475518 MsgID "Message Identifier (range of 0 to 63).

See ITU-R M.1371-1 for more information.";
CM_ BO_ 2650476030 "This parameter group provides data associated with ITU-R M.1371 Msg 20 Data Link Management Msg for reserving slots for base stations.An AIS device may generate this parameter group either upon receiving a VHF data link Msg 20,or upon receipt of an ISO NM";
CM_ SG_ 2650476030 Increment4 "Number of route, waypoint, event, mark, etc.";
CM_ SG_ 2650476030 TimeOut4 "Number of route, waypoint, event, mark, etc.";
CM_ SG_ 2650476030 NumberOfSlots4 "Number of route, waypoint, event, mark, etc.";
CM_ SG_ 2650476030 OffsetNumber4 "Number of route, waypoint, event, mark, etc.";
CM_ SG_ 2650476030 Increment3 "Number of route, waypoint, event, mark, etc.";
CM_ SG_ 2650476030 TimeOut3 "Number of route, waypoint, event, mark, etc.";
CM_ SG_ 2650476030 NumberOfSlots3 "Number of route, waypoint, event, mark, etc.";
CM_ SG_ 2650476030 OffsetNumber3 "Number of route, waypoint, event, mark, etc.";
CM_ SG_ 2650476030 Increment2 "Number of route, waypoint, event, mark, etc.";
CM_ SG_ 2650476030 TimeOut2 "Number of route, waypoint, event, mark, etc.";
CM_ SG_ 2650476030 NumberOfSlots2 "Number of route, waypoint, event, mark, etc.";
CM_ SG_ 2650476030 OffsetNumber2 "Number of route, waypoint, event, mark, etc.";
CM_ SG_ 2650476030 Increment1 "Number of route, waypoint, event, mark, etc.";
CM_ SG_ 2650476030 TimeOut1 "Number of route, waypoint, event, mark, etc.";
CM_ SG_ 2650476030 NumberOfSlots1 "Number of route, waypoint, event, mark, etc.";
CM_ SG_ 2650476030 OffsetNumber1 "Number of route, waypoint, event, mark, etc.";
CM_ SG_ 2650476030 AISTransceiverInformation "0 = Channel A VDL reception,
1 = Channel B VDL reception,
2 = Channel A VDL transmission,
3 = Channel B VDL transmission,
4 = Own information not broadcast,
5-31 = Reserved.";
CM_ SG_ 2650476030 SourceStationID "Number of route, waypoint, event, mark, etc.";
CM_ SG_ 2650476030 RepeatIndicator "Used by the repeater to indicate how many times a message has been repeated (range of 0 to 3).

0 = Default
1 = First retransmission
2 = Second retransmission
3 = Final retransmission

See ITU-R M.1371-1 for more information.";
CM_ SG_ 2650476030 MsgID "Message Identifier (range of 0 to 63).

See ITU-R M.1371-1 for more information.";
CM_ BO_ 2583363838 "This parameter group provides data associated with ITU-R M.1371 Msg 17 GNSS Broadcast Binary Msg containing DGNSS corrections from a base station.An AIS device may generate this parameter group either upon receiving a VHF data link Msg 17,or upon receipt ";
CM_ SG_ 2583363838 NumberOfBitsInBinaryDataField "Number of route, waypoint, event, mark, etc.";
CM_ SG_ 2583363838 AISTransceiverInformation "0 = Channel A VDL reception,
1 = Channel B VDL reception,
2 = Channel A VDL transmission,
3 = Channel B VDL transmission,
4 = Own information not broadcast,
5-31 = Reserved.";
CM_ SG_ 2583363838 SourceID "Number of route, waypoint, event, mark, etc.";
CM_ SG_ 2583363838 RepeatIndicator "Used by the repeater to indicate how many times a message has been repeated (range of 0 to 3).

0 = Default
1 = First retransmission
2 = Second retransmission
3 = Final retransmission

See ITU-R M.1371-1 for more information.";
CM_ SG_ 2583363838 MsgID "Message Identifier (range of 0 to 63).

See ITU-R M.1371-1 for more information.";
CM_ BO_ 2650473214 "This parameter group provides data associated with ITU-R M.1371 Msg 5 Ship Static and Voyage Related Data Msg.An AIS device may generate this parameter group either upon receiving a VHF data link Msg 5,or upon receipt of an ISO NMEA Rq PGN.Cmd Group Funct";
CM_ SG_ 2650473214 CallSign "Length specified by PGN field definition.";
CM_ SG_ 2650473214 IMO "Number of route, waypoint, event, mark, etc.";
CM_ SG_ 2650473214 UserID "Number of route, waypoint, event, mark, etc.";
CM_ SG_ 2650473214 RepeatIndicator "Used by the repeater to indicate how many times a message has been repeated (range of 0 to 3).

0 = Default
1 = First retransmission
2 = Second retransmission
3 = Final retransmission

See ITU-R M.1371-1 for more information.";
CM_ SG_ 2650473214 MsgID "Message Identifier (range of 0 to 63).

See ITU-R M.1371-1 for more information.";
CM_ BO_ 2448953342 "This parameter group provides data associated with ITU-R M.1371 Msg 18 Standard Class B Equipment Pos Report.An AIS device may generate this parameter group either upon receiving a VHF data link Msg 18,or upon receipt of an ISO NMEA Rq PGN(see ITU-R M.137";
CM_ SG_ 2448953342 ComminicationStateSelectorFlag "0=SOTDMA communication state,
1=ITDMA communication state follows.

See ITU-R M.1371-1 for more information.";
CM_ SG_ 2448953342 TrueHeading "Degrees clockwise relative to True North.";
CM_ SG_ 2448953342 AISTransceiverInformation "0 = Channel A VDL reception,
1 = Channel B VDL reception,
2 = Channel A VDL transmission,
3 = Channel B VDL transmission,
4 = Own information not broadcast,
5-31 = Reserved.";
CM_ SG_ 2448953342 CommunicationState "The Communication State contains information used by the various TDMA slot allocation algorithms and synchronization information

See ITU-R M.1371-1 for more information.";
CM_ SG_ 2448953342 COG "The direction of the path over ground actually followed by a vessel.";
CM_ SG_ 2448953342 TimeStamp "0-59=UTC second when report was generated,
60=time stamp not available(default),
61=Posing system is in manual input mode,
62=Electronic Pos fixing system operates in Est(dead reckoning)mode,
63=Posing system is inoperative

See ITU-R M.1371-1 for m";
CM_ SG_ 2448953342 RAIMflag "0 = RAIM not in use (default),
1 = RAIM in use

See ITU-R M.1371-1 for more information.";
CM_ SG_ 2448953342 PosAccuracy "0=low accuracy>10m such as nondifferential GNSS (default), 
1=high accuracy <10m such as DGNSS

See ITU-R M.1371-1 for more information.";
CM_ SG_ 2448953342 UserID "Number of route, waypoint, event, mark, etc.";
CM_ SG_ 2448953342 RepeatIndicator "Used by the repeater to indicate how many times a message has been repeated (range of 0 to 3).

0 = Default
1 = First retransmission
2 = Second retransmission
3 = Final retransmission

See ITU-R M.1371-1 for more information.";
CM_ SG_ 2448953342 MsgID "Message Identifier (range of 0 to 63).

See ITU-R M.1371-1 for more information.";
CM_ BO_ 2448953598 "This parameter group provides data associated with ITU-R M.1371 Msg 19 Ex Class B Equipment Pos Report containing Pos and static information.An AIS device may generate this parameter group either upon receiving a VHF data link Msg 19,or upon receipt of an";
CM_ SG_ 2448953598 Name "Name of place, route, waypoint, destination, vessel, vehicle, etc.";
CM_ SG_ 2448953598 PosReferencePointAftOfShipsBow "Dependent upon PG Field definition.";
CM_ SG_ 2448953598 PosReferencePointFromStarboard "Dependent upon PG Field definition.";
CM_ SG_ 2448953598 ShipBeam "Dependent upon PG Field definition.";
CM_ SG_ 2448953598 ShipLength "Dependent upon PG Field definition.";
CM_ SG_ 2448953598 TypeOfElectronicPosingDevice "0=Undefined (default), 
1=GPS, 
2=GLONASS, 
3=Combined GPS/GLONASS, 
4=Loran-C, 
5=Chayka, 
6=Integrated Navigation System, 
7=Surveyed (Base Station), 
8-15=Reserve for future use.

See ITU-R M.1371-1 for more information.";
CM_ SG_ 2448953598 TrueHeading "Degrees clockwise relative to True North.";
CM_ SG_ 2448953598 Ship_CargoType "0=Not Available or no ship (default), 
1-99= (See ITU-R M.1371-1 Section 3.3.8.2.3.2 Table 18), 
100-199=Reserved for Regional (See ITU-R M.1371-1), 
200-255=Reserved for future (See ITU-R M.1371-1).";
CM_ SG_ 2448953598 COG "The direction of the path over ground actually followed by a vessel.";
CM_ SG_ 2448953598 TimeStamp "0-59=UTC second when report was generated,
60=time stamp not available(default),
61=Posing system is in manual input mode,
62=Electronic Pos fixing system operates in Est(dead reckoning)mode,
63=Posing system is inoperative

See ITU-R M.1371-1 for m";
CM_ SG_ 2448953598 RAIMflag "0 = RAIM not in use (default),
1 = RAIM in use

See ITU-R M.1371-1 for more information.";
CM_ SG_ 2448953598 PosAccuracy "0=low accuracy>10m such as nondifferential GNSS (default), 
1=high accuracy <10m such as DGNSS

See ITU-R M.1371-1 for more information.";
CM_ SG_ 2448953598 UserID "Number of route, waypoint, event, mark, etc.";
CM_ SG_ 2448953598 RepeatIndicator "Used by the repeater to indicate how many times a message has been repeated (range of 0 to 3).

0 = Default
1 = First retransmission
2 = Second retransmission
3 = Final retransmission

See ITU-R M.1371-1 for more information.";
CM_ SG_ 2448953598 MsgID "Message Identifier (range of 0 to 63).

See ITU-R M.1371-1 for more information.";
CM_ BO_ 2448953086 "This parameter group provides data associated with ITU-R M.1371 Msgs 1,2,and 3 Pos Reports,autonomous,assigned,and Resp to interrogation,respectively.An AIS device may generate this parameter group either upon receiving a VHF data link Msg 1,2 3,or upon r";
CM_ SG_ 2448953086 NavigationalStatus "0 = under way using Eng,
1 = at anchor,
2 = not under Cmd,
3 = restricted manoeuvrability,
4 = constrained by her draught,
5 = moored,
6 = aground,
7 = engaged in fishing,
8 = under way sailing,
9 = reserved for future amendment of navigational s";
CM_ SG_ 2448953086 RateOfTurn "+ = Bow turning to starboard, 1 deg/min = .00029 rad/sec";
CM_ SG_ 2448953086 TrueHeading "Degrees clockwise relative to True North.";
CM_ SG_ 2448953086 AISTransceiverInformation "0 = Channel A VDL reception,
1 = Channel B VDL reception,
2 = Channel A VDL transmission,
3 = Channel B VDL transmission,
4 = Own information not broadcast,
5-31 = Reserved.";
CM_ SG_ 2448953086 CommunicationState "The Communication State contains information used by the various TDMA slot allocation algorithms and synchronization information

See ITU-R M.1371-1 for more information.";
CM_ SG_ 2448953086 COG "The direction of the path over ground actually followed by a vessel.";
CM_ SG_ 2448953086 TimeStamp "0-59=UTC second when report was generated,
60=time stamp not available(default),
61=Posing system is in manual input mode,
62=Electronic Pos fixing system operates in Est(dead reckoning)mode,
63=Posing system is inoperative

See ITU-R M.1371-1 for m";
CM_ SG_ 2448953086 RAIMflag "0 = RAIM not in use (default),
1 = RAIM in use

See ITU-R M.1371-1 for more information.";
CM_ SG_ 2448953086 PosAccuracy "0=low accuracy>10m such as nondifferential GNSS (default), 
1=high accuracy <10m such as DGNSS

See ITU-R M.1371-1 for more information.";
CM_ SG_ 2448953086 UserID "Number of route, waypoint, event, mark, etc.";
CM_ SG_ 2448953086 RepeatIndicator "Used by the repeater to indicate how many times a message has been repeated (range of 0 to 3).

0 = Default
1 = First retransmission
2 = Second retransmission
3 = Final retransmission

See ITU-R M.1371-1 for more information.";
CM_ SG_ 2448953086 MsgID "Message Identifier (range of 0 to 63).

See ITU-R M.1371-1 for more information.";
CM_ BO_ 2650473982 "This parameter group provides data associated with ITU-R M.1371 Msg 8 Binary Broadcast Msg supporting broadcast communication of binary data.An AIS device may generate this parameter group either upon receiving a VHF data link Msg 8,or upon receipt of an ";
CM_ SG_ 2650473982 NumberOfBitsInBinaryDataField "Number of route, waypoint, event, mark, etc.";
CM_ SG_ 2650473982 AISTransceiverInformation "0 = Channel A VDL reception,
1 = Channel B VDL reception,
2 = Channel A VDL transmission,
3 = Channel B VDL transmission,
4 = Own information not broadcast,
5-31 = Reserved.";
CM_ SG_ 2650473982 SourceID "Number of route, waypoint, event, mark, etc.";
CM_ SG_ 2650473982 RepeatIndicator "Used by the repeater to indicate how many times a message has been repeated (range of 0 to 3).

0 = Default
1 = First retransmission
2 = Second retransmission
3 = Final retransmission

See ITU-R M.1371-1 for more information.";
CM_ SG_ 2650473982 MsgID "Message Identifier (range of 0 to 63).

See ITU-R M.1371-1 for more information.";
CM_ BO_ 2650475774 "This parameter group provides data associated with ITU-R M.1371 Msg 16 Assigned Mode Cmd Msg for assigning specific behavior by a competent authority.An AIS device may generate this parameter group either upon receiving a VHF data link Msg 16,or upon rece";
CM_ SG_ 2650475774 IncrementB "Number of route, waypoint, event, mark, etc.";
CM_ SG_ 2650475774 OffsetB "Number of route, waypoint, event, mark, etc.";
CM_ SG_ 2650475774 DestinationIDB "Number of route, waypoint, event, mark, etc.";
CM_ SG_ 2650475774 IncrementA "Number of route, waypoint, event, mark, etc.";
CM_ SG_ 2650475774 OffsetA "Number of route, waypoint, event, mark, etc.";
CM_ SG_ 2650475774 DestinationIDA "Number of route, waypoint, event, mark, etc.";
CM_ SG_ 2650475774 AISTransceiverInformation "0 = Channel A VDL reception,
1 = Channel B VDL reception,
2 = Channel A VDL transmission,
3 = Channel B VDL transmission,
4 = Own information not broadcast,
5-31 = Reserved.";
CM_ SG_ 2650475774 SourceID "Number of route, waypoint, event, mark, etc.";
CM_ SG_ 2650475774 RepeatIndicator "Used by the repeater to indicate how many times a message has been repeated (range of 0 to 3).

0 = Default
1 = First retransmission
2 = Second retransmission
3 = Final retransmission

See ITU-R M.1371-1 for more information.";
CM_ SG_ 2650475774 MsgID "Message Identifier (range of 0 to 63).

See ITU-R M.1371-1 for more information.";
CM_ BO_ 2650475006 "This parameter group provides data associated with ITU-R M.1371 Msg 12 Addressed Safety Related Msg supporting addressed communication of safety related data.An AIS device may generate this parameter group either upon receiving a VHF data link Msg 12,or u";
CM_ SG_ 2650475006 SafetyRelatedText "Name of place, route, waypoint, destination, vessel, vehicle, etc.";
CM_ SG_ 2650475006 RetransmitFlag "0=No retransmission,
1=retransmitted.

See ITU-R M.1371-1 for more information.";
CM_ SG_ 2650475006 DestinationID "Number of route, waypoint, event, mark, etc.";
CM_ SG_ 2650475006 SequenceNumber_ "Range 0-3

See ITU-R M.1371-1 for more information.";
CM_ SG_ 2650475006 AISTransceiverInformation "0 = Channel A VDL reception,
1 = Channel B VDL reception,
2 = Channel A VDL transmission,
3 = Channel B VDL transmission,
4 = Own information not broadcast,
5-31 = Reserved.";
CM_ SG_ 2650475006 SourceID "Number of route, waypoint, event, mark, etc.";
CM_ SG_ 2650475006 RepeatIndicator "Used by the repeater to indicate how many times a message has been repeated (range of 0 to 3).

0 = Default
1 = First retransmission
2 = Second retransmission
3 = Final retransmission

See ITU-R M.1371-1 for more information.";
CM_ SG_ 2650475006 MsgID "Message Identifier (range of 0 to 63).

See ITU-R M.1371-1 for more information.";
CM_ BO_ 2650473470 "This parameter group provides data associated with ITU-R M.1371 Msg 6 Addressed Binary Msg supporting address communication of binary data.An AIS device may generate this parameter group either upon receiving a VHF data link Msg 6,or upon receipt of an IS";
CM_ SG_ 2650473470 NumberOfBitsInBinaryDataField "Number of route, waypoint, event, mark, etc.";
CM_ SG_ 2650473470 RetransmitFlag "0=No retransmission,
1=retransmitted.

See ITU-R M.1371-1 for more information.";
CM_ SG_ 2650473470 DestinationID "Number of route, waypoint, event, mark, etc.";
CM_ SG_ 2650473470 SequenceNumber_ "Range 0-3

See ITU-R M.1371-1 for more information.";
CM_ SG_ 2650473470 AISTransceiverInformation "0 = Channel A VDL reception,
1 = Channel B VDL reception,
2 = Channel A VDL transmission,
3 = Channel B VDL transmission,
4 = Own information not broadcast,
5-31 = Reserved.";
CM_ SG_ 2650473470 SourceID "Number of route, waypoint, event, mark, etc.";
CM_ SG_ 2650473470 RepeatIndicator "Used by the repeater to indicate how many times a message has been repeated (range of 0 to 3).

0 = Default
1 = First retransmission
2 = Second retransmission
3 = Final retransmission

See ITU-R M.1371-1 for more information.";
CM_ SG_ 2650473470 MsgID "Message Identifier (range of 0 to 63).

See ITU-R M.1371-1 for more information.";
CM_ BO_ 2650473726 "This parameter group provides data associated with ITU-R M.1371 Msgs 7 Binary Acknowledge Msg and 13 Safety Related Acknowledge Msg.Msg 7 acknowledges receipt of Msg 6 while Msg 13 acknowledges receipt of Msg 14.An AIS device may generate this parameter g";
CM_ SG_ 2650473726 SequenceNumberForIDn "Range 0-3

See ITU-R M.1371-1 for more information.";
CM_ SG_ 2650473726 SequenceNumberForID1 "Range 0-3

See ITU-R M.1371-1 for more information.";
CM_ SG_ 2650473726 DestinationID1 "Number of route, waypoint, event, mark, etc.";
CM_ SG_ 2650473726 AISTransceiverInformation "0 = Channel A VDL reception,
1 = Channel B VDL reception,
2 = Channel A VDL transmission,
3 = Channel B VDL transmission,
4 = Own information not broadcast,
5-31 = Reserved.";
CM_ SG_ 2650473726 SourceID "Number of route, waypoint, event, mark, etc.";
CM_ SG_ 2650473726 RepeatIndicator "Used by the repeater to indicate how many times a message has been repeated (range of 0 to 3).

0 = Default
1 = First retransmission
2 = Second retransmission
3 = Final retransmission

See ITU-R M.1371-1 for more information.";
CM_ SG_ 2650473726 MsgID "Message Identifier (range of 0 to 63).

See ITU-R M.1371-1 for more information.";
CM_ BO_ 2365475070 "Wheel-based Speed and Distance";
CM_ SG_ 2365475070 OperatorDirectionReversed "This parameter indicates whether the reported direction is reversed from the perspective of the operator.";
CM_ BO_ 2565340926 "ECU to VT";
CM_ SG_ 2565340926 AuxInputEnable "Auxiliary Input EnableAuxiliary Input Enable";
CM_ SG_ 2565340926 AuxModelIdentification "Model Identification Code of the Auxiliary Input Unit";
CM_ SG_ 2565340926 AuxErrorInvalidInputID "Invalid Auxiliary Input Object ID";
CM_ SG_ 2565340926 AuxErrorAnyOther "Any other error";
BA_DEF_ BO_  "GenMsgCycleTimeFast" INT 0 3600000;
BA_DEF_ SG_  "SigType" ENUM  "Default","Range","RangeSigned","ASCII","Discrete","Control","ReferencePGN","DTC","StringDelimiter","StringLength","StringLengthControl";
BA_DEF_ SG_  "GenSigStartValue" INT 0 10000;
BA_DEF_ SG_  "GenSigSendType" ENUM  "Cyclic","OnWrite","reserved","OnChange","reserved","reserved","reserved","NoSigSendType";
BA_DEF_ SG_  "GenSigILSupport" ENUM  "Yes","No";
BA_DEF_ SG_  "GenSigEVName" STRING ;
BA_DEF_ SG_  "SPN" INT 0 524287;
BA_DEF_ SG_  "DDI" INT 0 65535;
BA_DEF_ SG_  "SAEDocument" STRING ;
BA_DEF_ BO_  "GenMsgStartDelayTime" INT 0 100000;
BA_DEF_ BO_  "GenMsgILSupport" ENUM  "Yes","No";
BA_DEF_ BO_  "GenMsgRequestable" INT 0 1;
BA_DEF_ BO_  "GenMsgSendType" ENUM  "cyclic","reserved","cyclicIfActive","reserved","reserved","reserved","reserved","reserved","noMsgSendType";
BA_DEF_ BO_  "VFrameFormat" ENUM  "StandardCAN","ExtendedCAN","reserved","J1939PG";
BA_DEF_ BO_  "SingleFrame" INT 0 1;
BA_DEF_ BO_  "GenMsgCycleTime" INT 0 3600000;
BA_DEF_ BO_  "SAE_Document" STRING ;
BA_DEF_ SG_  "SystemSignalLongSymbol" STRING ;
BA_DEF_DEF_  "GenMsgCycleTimeFast" 0;
BA_DEF_DEF_  "SigType" "Default";
BA_DEF_DEF_  "GenSigStartValue" 0;
BA_DEF_DEF_  "GenSigSendType" "NoSigSendType";
BA_DEF_DEF_  "GenSigILSupport" "Yes";
BA_DEF_DEF_  "GenSigEVName" "Env@Nodename_@Signame";
BA_DEF_DEF_  "SPN" 0;
BA_DEF_DEF_  "DDI" 0;
BA_DEF_DEF_  "SAEDocument" "";
BA_DEF_DEF_  "GenMsgStartDelayTime" 0;
BA_DEF_DEF_  "GenMsgILSupport" "Yes";
BA_DEF_DEF_  "GenMsgRequestable" 1;
BA_DEF_DEF_  "GenMsgSendType" "noMsgSendType";
BA_DEF_DEF_  "VFrameFormat" "J1939PG";
BA_DEF_DEF_  "SingleFrame" 1;
BA_DEF_DEF_  "GenMsgCycleTime" 0;
BA_DEF_DEF_  "SAE_Document" "";
BA_DEF_DEF_  "SystemSignalLongSymbol" "";
BA_ "SAE_Document" BO_ 2583299070 "NMEA2000";
BA_ "GenMsgCycleTime" BO_ 2583299070 1000;
BA_ "SAE_Document" BO_ 2583298814 "NMEA2000";
BA_ "SingleFrame" BO_ 2583298814 0;
BA_ "SAE_Document" BO_ 2583303422 "NMEA2000";
BA_ "SingleFrame" BO_ 2583303422 0;
BA_ "SAE_Document" BO_ 2582778366 "NMEA2000";
BA_ "GenMsgCycleTime" BO_ 2582778366 2500;
BA_ "SAE_Document" BO_ 2516387838 "NMEA2000";
BA_ "GenMsgCycleTime" BO_ 2516387838 500;
BA_ "SAE_Document" BO_ 2516387582 "NMEA2000";
BA_ "GenMsgCycleTime" BO_ 2516387582 500;
BA_ "SAE_Document" BO_ 2515667710 "NMEA2000";
BA_ "SingleFrame" BO_ 2515667710 0;
BA_ "SAE_Document" BO_ 2314338558 "NMEA2000";
BA_ "GenMsgCycleTime" BO_ 2314338558 100;
BA_ "SAE_Document" BO_ 2314338814 "NMEA2000";
BA_ "GenMsgCycleTime" BO_ 2314338814 500;
BA_ "SingleFrame" BO_ 2314338814 0;
BA_ "SAE_Document" BO_ 2582975486 "NMEA2000";
BA_ "GenMsgCycleTime" BO_ 2582975486 1000;
BA_ "SingleFrame" BO_ 2582975486 0;
BA_ "SAE_Document" BO_ 2382238206 "NMEA2000";
BA_ "GenMsgCycleTime" BO_ 2382238206 1000;
BA_ "SingleFrame" BO_ 2382238206 0;
BA_ "SAE_Document" BO_ 2583172350 "NMEA2000";
BA_ "GenMsgCycleTime" BO_ 2583172350 10000;
BA_ "SingleFrame" BO_ 2583172350 0;
BA_ "SAE_Document" BO_ 2449150206 "NMEA2000";
BA_ "SingleFrame" BO_ 2449150206 0;
BA_ "SAE_Document" BO_ 2583301630 "NMEA2000";
BA_ "SingleFrame" BO_ 2583301630 0;
BA_ "SAE_Document" BO_ 2583499518 "NMEA2000";
BA_ "GenMsgCycleTime" BO_ 2583499518 1000;
BA_ "SingleFrame" BO_ 2583499518 0;
BA_ "SAE_Document" BO_ 2381906942 "NMEA2000";
BA_ "GenMsgCycleTime" BO_ 2381906942 1000;
BA_ "SAE_Document" BO_ 2582648574 "NMEA2000";
BA_ "SingleFrame" BO_ 2582648574 0;
BA_ "SAE_Document" BO_ 2583238398 "NMEA2000";
BA_ "SingleFrame" BO_ 2583238398 0;
BA_ "SAE_Document" BO_ 2381450750 "NMEA2000";
BA_ "SAE_Document" BO_ 2582779134 "NMEA2000";
BA_ "GenMsgCycleTime" BO_ 2582779134 1500;
BA_ "SAE_Document" BO_ 2381388286 "NMEA2000";
BA_ "GenMsgCycleTime" BO_ 2381388286 1000;
BA_ "SAE_Document" BO_ 2314732798 "NMEA2000";
BA_ "GenMsgCycleTime" BO_ 2314732798 100;
BA_ "GenMsgRequestable" BO_ 2314732798 0;
BA_ "SAE_Document" BO_ 2650474750 "NMEA2000";
BA_ "SingleFrame" BO_ 2650474750 0;
BA_ "GenMsgRequestable" BO_ 2650474750 0;
BA_ "SAE_Document" BO_ 2650472958 "NMEA2000";
BA_ "SingleFrame" BO_ 2650472958 0;
BA_ "GenMsgRequestable" BO_ 2650472958 0;
BA_ "SAE_Document" BO_ 2650475262 "NMEA2000";
BA_ "SingleFrame" BO_ 2650475262 0;
BA_ "GenMsgRequestable" BO_ 2650475262 0;
BA_ "SAE_Document" BO_ 2650474238 "NMEA2000";
BA_ "SingleFrame" BO_ 2650474238 0;
BA_ "GenMsgRequestable" BO_ 2650474238 0;
BA_ "SAE_Document" BO_ 2650475518 "NMEA2000";
BA_ "SingleFrame" BO_ 2650475518 0;
BA_ "GenMsgRequestable" BO_ 2650475518 0;
BA_ "SAE_Document" BO_ 2650476030 "NMEA2000";
BA_ "SingleFrame" BO_ 2650476030 0;
BA_ "GenMsgRequestable" BO_ 2650476030 0;
BA_ "SAE_Document" BO_ 2583363838 "NMEA2000";
BA_ "SingleFrame" BO_ 2583363838 0;
BA_ "GenMsgRequestable" BO_ 2583363838 0;
BA_ "SAE_Document" BO_ 2650473214 "NMEA2000";
BA_ "SingleFrame" BO_ 2650473214 0;
BA_ "GenMsgRequestable" BO_ 2650473214 0;
BA_ "SAE_Document" BO_ 2448953342 "NMEA2000";
BA_ "SingleFrame" BO_ 2448953342 0;
BA_ "GenMsgRequestable" BO_ 2448953342 0;
BA_ "SAE_Document" BO_ 2448953598 "NMEA2000";
BA_ "SingleFrame" BO_ 2448953598 0;
BA_ "GenMsgRequestable" BO_ 2448953598 0;
BA_ "SAE_Document" BO_ 2448953086 "NMEA2000";
BA_ "SingleFrame" BO_ 2448953086 0;
BA_ "GenMsgRequestable" BO_ 2448953086 0;
BA_ "SAE_Document" BO_ 2650473982 "NMEA2000";
BA_ "SingleFrame" BO_ 2650473982 0;
BA_ "GenMsgRequestable" BO_ 2650473982 0;
BA_ "SAE_Document" BO_ 2650475774 "NMEA2000";
BA_ "SingleFrame" BO_ 2650475774 0;
BA_ "GenMsgRequestable" BO_ 2650475774 0;
BA_ "SAE_Document" BO_ 2650475006 "NMEA2000";
BA_ "SingleFrame" BO_ 2650475006 0;
BA_ "GenMsgRequestable" BO_ 2650475006 0;
BA_ "SAE_Document" BO_ 2650473470 "NMEA2000";
BA_ "SingleFrame" BO_ 2650473470 0;
BA_ "GenMsgRequestable" BO_ 2650473470 0;
BA_ "SAE_Document" BO_ 2650473726 "NMEA2000";
BA_ "SingleFrame" BO_ 2650473726 0;
BA_ "GenMsgRequestable" BO_ 2650473726 0;
BA_ "GenMsgCycleTime" BO_ 2365475070 100;
BA_ "GenMsgCycleTime" BO_ 2565340926 1000;
BA_ "SAEDocument" SG_ 2583299070 TDOP "NMEA2000";
BA_ "SigType" SG_ 2583299070 TDOP 2;
BA_ "SAEDocument" SG_ 2583299070 VDOP "NMEA2000";
BA_ "SigType" SG_ 2583299070 VDOP 2;
BA_ "SAEDocument" SG_ 2583299070 HDOP_ "NMEA2000";
BA_ "SigType" SG_ 2583299070 HDOP_ 2;
BA_ "SAEDocument" SG_ 2583299070 OpMode "NMEA2000";
BA_ "SAEDocument" SG_ 2583299070 SetMode "NMEA2000";
BA_ "SAEDocument" SG_ 2583299070 SID "NMEA2000";
BA_ "SigType" SG_ 2583299070 SID 1;
BA_ "SAEDocument" SG_ 2583298814 UseAntennaAltitudeFor2DMode "NMEA2000";
BA_ "SigType" SG_ 2583298814 UseAntennaAltitudeFor2DMode 4;
BA_ "SAEDocument" SG_ 2583298814 AntennaAltitudeFor2DMode "NMEA2000";
BA_ "SigType" SG_ 2583298814 AntennaAltitudeFor2DMode 2;
BA_ "SAEDocument" SG_ 2583298814 MaxCorrectionAge "NMEA2000";
BA_ "SigType" SG_ 2583298814 MaxCorrectionAge 1;
BA_ "SAEDocument" SG_ 2583298814 Pos_VelocityFilter "NMEA2000";
BA_ "SigType" SG_ 2583298814 Pos_VelocityFilter 4;
BA_ "SAEDocument" SG_ 2583298814 DGNSSMode "NMEA2000";
BA_ "SAEDocument" SG_ 2583298814 GNSSMode "NMEA2000";
BA_ "SAEDocument" SG_ 2583298814 SNRMask "NMEA2000";
BA_ "SigType" SG_ 2583298814 SNRMask 2;
BA_ "SAEDocument" SG_ 2583298814 PDOPSwitch "NMEA2000";
BA_ "SigType" SG_ 2583298814 PDOPSwitch 2;
BA_ "SAEDocument" SG_ 2583298814 PDOPMask "NMEA2000";
BA_ "SigType" SG_ 2583298814 PDOPMask 2;
BA_ "SAEDocument" SG_ 2583298814 SVElevationMask "NMEA2000";
BA_ "SigType" SG_ 2583298814 SVElevationMask 2;
BA_ "SAEDocument" SG_ 2583303422 tnA2 "NMEA2000";
BA_ "SigType" SG_ 2583303422 tnA2 1;
BA_ "SAEDocument" SG_ 2583303422 tcA "NMEA2000";
BA_ "SigType" SG_ 2583303422 tcA 1;
BA_ "SAEDocument" SG_ 2583303422 inA "NMEA2000";
BA_ "SigType" SG_ 2583303422 inA 1;
BA_ "SAEDocument" SG_ 2583303422 nA3 "NMEA2000";
BA_ "SigType" SG_ 2583303422 nA3 1;
BA_ "SAEDocument" SG_ 2583303422 tnA "NMEA2000";
BA_ "SigType" SG_ 2583303422 tnA 1;
BA_ "SAEDocument" SG_ 2583303422 TnA "NMEA2000";
BA_ "SigType" SG_ 2583303422 TnA 1;
BA_ "SAEDocument" SG_ 2583303422 nA2 "NMEA2000";
BA_ "SigType" SG_ 2583303422 nA2 1;
BA_ "SAEDocument" SG_ 2583303422 DOT "NMEA2000";
BA_ "SigType" SG_ 2583303422 DOT 1;
BA_ "SAEDocument" SG_ 2583303422 nA "NMEA2000";
BA_ "SigType" SG_ 2583303422 nA 1;
BA_ "SAEDocument" SG_ 2583303422 HnA "NMEA2000";
BA_ "SAEDocument" SG_ 2583303422 CnA "NMEA2000";
BA_ "SAEDocument" SG_ 2583303422 NA "NMEA2000";
BA_ "SigType" SG_ 2583303422 NA 1;
BA_ "SAEDocument" SG_ 2583303422 PRN "NMEA2000";
BA_ "SigType" SG_ 2583303422 PRN 1;
BA_ "SAEDocument" SG_ 2582778366 TankCapacity "NMEA2000";
BA_ "SigType" SG_ 2582778366 TankCapacity 1;
BA_ "SAEDocument" SG_ 2582778366 FluidLevel "NMEA2000";
BA_ "SigType" SG_ 2582778366 FluidLevel 2;
BA_ "SAEDocument" SG_ 2582778366 FluidType "NMEA2000";
BA_ "SAEDocument" SG_ 2582778366 FluidInstance "NMEA2000";
BA_ "SAEDocument" SG_ 2516387838 AtmosphericPress "NMEA2000";
BA_ "SigType" SG_ 2516387838 AtmosphericPress 1;
BA_ "SAEDocument" SG_ 2516387838 Humidity "NMEA2000";
BA_ "SigType" SG_ 2516387838 Humidity 2;
BA_ "SAEDocument" SG_ 2516387838 Temp "NMEA2000";
BA_ "SigType" SG_ 2516387838 Temp 1;
BA_ "SAEDocument" SG_ 2516387838 HumidityInstance "NMEA2000";
BA_ "SigType" SG_ 2516387838 HumidityInstance 4;
BA_ "SAEDocument" SG_ 2516387838 TempInstance "NMEA2000";
BA_ "SAEDocument" SG_ 2516387838 SequenceID_ "NMEA2000";
BA_ "SigType" SG_ 2516387838 SequenceID_ 1;
BA_ "SAEDocument" SG_ 2516387582 AtmosphericPress "NMEA2000";
BA_ "SigType" SG_ 2516387582 AtmosphericPress 1;
BA_ "SAEDocument" SG_ 2516387582 OutsideAmbientAirTemp "NMEA2000";
BA_ "SigType" SG_ 2516387582 OutsideAmbientAirTemp 1;
BA_ "SAEDocument" SG_ 2516387582 WaterTemp "NMEA2000";
BA_ "SigType" SG_ 2516387582 WaterTemp 1;
BA_ "SAEDocument" SG_ 2516387582 SequenceID_ "NMEA2000";
BA_ "SigType" SG_ 2516387582 SequenceID_ 1;
BA_ "SAEDocument" SG_ 2515667710 VIN "NMEA2000";
BA_ "SigType" SG_ 2515667710 VIN 1;
BA_ "SAEDocument" SG_ 2515667710 RatedEngSpeed "NMEA2000";
BA_ "SigType" SG_ 2515667710 RatedEngSpeed 1;
BA_ "SAEDocument" SG_ 2515667710 EngInstance "NMEA2000";
BA_ "SigType" SG_ 2515667710 EngInstance 1;
BA_ "SAEDocument" SG_ 2314338558 EngTilt_Trim "NMEA2000";
BA_ "SigType" SG_ 2314338558 EngTilt_Trim 2;
BA_ "SAEDocument" SG_ 2314338558 EngBoostPress "NMEA2000";
BA_ "SigType" SG_ 2314338558 EngBoostPress 1;
BA_ "SAEDocument" SG_ 2314338558 EngSpeed_ "NMEA2000";
BA_ "SigType" SG_ 2314338558 EngSpeed_ 1;
BA_ "SAEDocument" SG_ 2314338558 EngInstance "NMEA2000";
BA_ "SigType" SG_ 2314338558 EngInstance 1;
BA_ "SAEDocument" SG_ 2314338814 PercentEngTorque "NMEA2000";
BA_ "SigType" SG_ 2314338814 PercentEngTorque 2;
BA_ "SAEDocument" SG_ 2314338814 PercentEngLoad "NMEA2000";
BA_ "SigType" SG_ 2314338814 PercentEngLoad 2;
BA_ "SAEDocument" SG_ 2314338814 EngDiscreteStatus2 "NMEA2000";
BA_ "SigType" SG_ 2314338814 EngDiscreteStatus2 1;
BA_ "SAEDocument" SG_ 2314338814 EngDiscreteStatus1 "NMEA2000";
BA_ "SigType" SG_ 2314338814 EngDiscreteStatus1 1;
BA_ "SAEDocument" SG_ 2314338814 FuelPress "NMEA2000";
BA_ "SigType" SG_ 2314338814 FuelPress 1;
BA_ "SAEDocument" SG_ 2314338814 EngCoolantPress_ "NMEA2000";
BA_ "SigType" SG_ 2314338814 EngCoolantPress_ 1;
BA_ "SAEDocument" SG_ 2314338814 TotalEngHours "NMEA2000";
BA_ "SigType" SG_ 2314338814 TotalEngHours 1;
BA_ "SAEDocument" SG_ 2314338814 FuelRate "NMEA2000";
BA_ "SigType" SG_ 2314338814 FuelRate 2;
BA_ "SAEDocument" SG_ 2314338814 AltPotential "NMEA2000";
BA_ "SigType" SG_ 2314338814 AltPotential 2;
BA_ "SAEDocument" SG_ 2314338814 EngTemp "NMEA2000";
BA_ "SigType" SG_ 2314338814 EngTemp 1;
BA_ "SAEDocument" SG_ 2314338814 EngOilTemp "NMEA2000";
BA_ "SigType" SG_ 2314338814 EngOilTemp 1;
BA_ "SAEDocument" SG_ 2314338814 EngOilPress_ "NMEA2000";
BA_ "SigType" SG_ 2314338814 EngOilPress_ 1;
BA_ "SAEDocument" SG_ 2314338814 EngInstance "NMEA2000";
BA_ "SigType" SG_ 2314338814 EngInstance 1;
BA_ "SAEDocument" SG_ 2582975486 DistanceSinceLastReset "NMEA2000";
BA_ "SigType" SG_ 2582975486 DistanceSinceLastReset 1;
BA_ "SAEDocument" SG_ 2582975486 TotalCumulativeDistance "NMEA2000";
BA_ "SigType" SG_ 2582975486 TotalCumulativeDistance 1;
BA_ "SAEDocument" SG_ 2582975486 MeasurementTime "NMEA2000";
BA_ "SigType" SG_ 2582975486 MeasurementTime 1;
BA_ "SAEDocument" SG_ 2582975486 MeasurementDate "NMEA2000";
BA_ "SigType" SG_ 2582975486 MeasurementDate 1;
BA_ "SAEDocument" SG_ 2382238206 Drift "NMEA2000";
BA_ "SigType" SG_ 2382238206 Drift 1;
BA_ "SAEDocument" SG_ 2382238206 Set "NMEA2000";
BA_ "SigType" SG_ 2382238206 Set 1;
BA_ "SAEDocument" SG_ 2382238206 SpeedThroughWater "NMEA2000";
BA_ "SigType" SG_ 2382238206 SpeedThroughWater 1;
BA_ "SAEDocument" SG_ 2382238206 Heading "NMEA2000";
BA_ "SigType" SG_ 2382238206 Heading 1;
BA_ "SAEDocument" SG_ 2382238206 SpeedOverGround "NMEA2000";
BA_ "SigType" SG_ 2382238206 SpeedOverGround 1;
BA_ "SAEDocument" SG_ 2382238206 CourseOverGround "NMEA2000";
BA_ "SigType" SG_ 2382238206 CourseOverGround 1;
BA_ "SAEDocument" SG_ 2382238206 SID "NMEA2000";
BA_ "SigType" SG_ 2382238206 SID 1;
BA_ "SAEDocument" SG_ 2382238206 Set_COG_HeadingRef "NMEA2000";
BA_ "SigType" SG_ 2382238206 Set_COG_HeadingRef 4;
BA_ "SAEDocument" SG_ 2382238206 DataMode "NMEA2000";
BA_ "SAEDocument" SG_ 2583172350 LocalDatum "NMEA2000";
BA_ "SigType" SG_ 2583172350 LocalDatum 1;
BA_ "SAEDocument" SG_ 2449150206 DSCMsgAddress "NMEA2000";
BA_ "SigType" SG_ 2449150206 DSCMsgAddress 1;
BA_ "SAEDocument" SG_ 2449150206 DSCCategorySymbol "NMEA2000";
BA_ "SigType" SG_ 2449150206 DSCCategorySymbol 1;
BA_ "SAEDocument" SG_ 2449150206 DSCFormatSymbol "NMEA2000";
BA_ "SigType" SG_ 2449150206 DSCFormatSymbol 1;
BA_ "SAEDocument" SG_ 2583301630 IOD "NMEA2000";
BA_ "SigType" SG_ 2583301630 IOD 1;
BA_ "SAEDocument" SG_ 2583301630 UDRE "NMEA2000";
BA_ "SigType" SG_ 2583301630 UDRE 1;
BA_ "SAEDocument" SG_ 2583301630 RRC "NMEA2000";
BA_ "SigType" SG_ 2583301630 RRC 2;
BA_ "SAEDocument" SG_ 2583301630 PRC "NMEA2000";
BA_ "SigType" SG_ 2583301630 PRC 2;
BA_ "SAEDocument" SG_ 2583301630 SatelliteID "NMEA2000";
BA_ "SigType" SG_ 2583301630 SatelliteID 1;
BA_ "SAEDocument" SG_ 2583301630 StationHealth "NMEA2000";
BA_ "SAEDocument" SG_ 2583301630 TimeOfCorrections "NMEA2000";
BA_ "SigType" SG_ 2583301630 TimeOfCorrections 1;
BA_ "SAEDocument" SG_ 2583301630 ReferenceStationType "NMEA2000";
BA_ "SAEDocument" SG_ 2583301630 ReferenceStationID "NMEA2000";
BA_ "SigType" SG_ 2583301630 ReferenceStationID 1;
BA_ "SAEDocument" SG_ 2583301630 SequenceID_ "NMEA2000";
BA_ "SigType" SG_ 2583301630 SequenceID_ 1;
BA_ "SAEDocument" SG_ 2583499518 StationIDString "NMEA2000";
BA_ "SigType" SG_ 2583499518 StationIDString 1;
BA_ "SAEDocument" SG_ 2583499518 WaterTemp "NMEA2000";
BA_ "SigType" SG_ 2583499518 WaterTemp 1;
BA_ "SAEDocument" SG_ 2583499518 CurrentFlowDirection "NMEA2000";
BA_ "SigType" SG_ 2583499518 CurrentFlowDirection 1;
BA_ "SAEDocument" SG_ 2583499518 CurrentSpeed "NMEA2000";
BA_ "SigType" SG_ 2583499518 CurrentSpeed 1;
BA_ "SAEDocument" SG_ 2583499518 MeasurementDepth "NMEA2000";
BA_ "SigType" SG_ 2583499518 MeasurementDepth 1;
BA_ "SAEDocument" SG_ 2583499518 StationLocationLongitude "NMEA2000";
BA_ "SigType" SG_ 2583499518 StationLocationLongitude 2;
BA_ "SAEDocument" SG_ 2583499518 StationLocationLatitude "NMEA2000";
BA_ "SigType" SG_ 2583499518 StationLocationLatitude 2;
BA_ "SAEDocument" SG_ 2583499518 MeasurementTime "NMEA2000";
BA_ "SigType" SG_ 2583499518 MeasurementTime 1;
BA_ "SAEDocument" SG_ 2583499518 MeasurementDate "NMEA2000";
BA_ "SigType" SG_ 2583499518 MeasurementDate 1;
BA_ "SAEDocument" SG_ 2583499518 State "NMEA2000";
BA_ "SAEDocument" SG_ 2583499518 Mode "NMEA2000";
BA_ "SAEDocument" SG_ 2381906942 XTE "NMEA2000";
BA_ "SigType" SG_ 2381906942 XTE 2;
BA_ "SAEDocument" SG_ 2381906942 NavigationTerminated "NMEA2000";
BA_ "SigType" SG_ 2381906942 NavigationTerminated 4;
BA_ "SAEDocument" SG_ 2381906942 XTEMode "NMEA2000";
BA_ "SAEDocument" SG_ 2381906942 SID "NMEA2000";
BA_ "SigType" SG_ 2381906942 SID 1;
BA_ "SAEDocument" SG_ 2582648574 InstallationDescriptionField1 "NMEA2000";
BA_ "SigType" SG_ 2582648574 InstallationDescriptionField1 1;
BA_ "SAEDocument" SG_ 2583238398 DestinationMarkID "NMEA2000";
BA_ "SigType" SG_ 2583238398 DestinationMarkID 1;
BA_ "SAEDocument" SG_ 2583238398 OriginMarkId "NMEA2000";
BA_ "SigType" SG_ 2583238398 OriginMarkId 1;
BA_ "SAEDocument" SG_ 2583238398 DestinationMarkType "NMEA2000";
BA_ "SAEDocument" SG_ 2583238398 OriginMarkType "NMEA2000";
BA_ "SAEDocument" SG_ 2583238398 Distance "NMEA2000";
BA_ "SigType" SG_ 2583238398 Distance 2;
BA_ "SAEDocument" SG_ 2583238398 BearingiginToDestination "NMEA2000";
BA_ "SigType" SG_ 2583238398 BearingiginToDestination 1;
BA_ "SAEDocument" SG_ 2583238398 CalculationType "NMEA2000";
BA_ "SigType" SG_ 2583238398 CalculationType 4;
BA_ "SAEDocument" SG_ 2583238398 BearingRef "NMEA2000";
BA_ "SAEDocument" SG_ 2583238398 SID "NMEA2000";
BA_ "SigType" SG_ 2583238398 SID 1;
BA_ "SAEDocument" SG_ 2381450750 Indic28 "NMEA2000";
BA_ "SigType" SG_ 2381450750 Indic28 4;
BA_ "SAEDocument" SG_ 2381450750 Indic27 "NMEA2000";
BA_ "SigType" SG_ 2381450750 Indic27 4;
BA_ "SAEDocument" SG_ 2381450750 Indic26 "NMEA2000";
BA_ "SigType" SG_ 2381450750 Indic26 4;
BA_ "SAEDocument" SG_ 2381450750 Indic25 "NMEA2000";
BA_ "SigType" SG_ 2381450750 Indic25 4;
BA_ "SAEDocument" SG_ 2381450750 Indic24 "NMEA2000";
BA_ "SigType" SG_ 2381450750 Indic24 4;
BA_ "SAEDocument" SG_ 2381450750 Indic23 "NMEA2000";
BA_ "SigType" SG_ 2381450750 Indic23 4;
BA_ "SAEDocument" SG_ 2381450750 Indic22 "NMEA2000";
BA_ "SigType" SG_ 2381450750 Indic22 4;
BA_ "SAEDocument" SG_ 2381450750 Indic21 "NMEA2000";
BA_ "SigType" SG_ 2381450750 Indic21 4;
BA_ "SAEDocument" SG_ 2381450750 Indic20 "NMEA2000";
BA_ "SigType" SG_ 2381450750 Indic20 4;
BA_ "SAEDocument" SG_ 2381450750 Indic19 "NMEA2000";
BA_ "SigType" SG_ 2381450750 Indic19 4;
BA_ "SAEDocument" SG_ 2381450750 Indic18 "NMEA2000";
BA_ "SigType" SG_ 2381450750 Indic18 4;
BA_ "SAEDocument" SG_ 2381450750 Indic17 "NMEA2000";
BA_ "SigType" SG_ 2381450750 Indic17 4;
BA_ "SAEDocument" SG_ 2381450750 Indic16 "NMEA2000";
BA_ "SigType" SG_ 2381450750 Indic16 4;
BA_ "SAEDocument" SG_ 2381450750 Indic15 "NMEA2000";
BA_ "SigType" SG_ 2381450750 Indic15 4;
BA_ "SAEDocument" SG_ 2381450750 Indic14 "NMEA2000";
BA_ "SigType" SG_ 2381450750 Indic14 4;
BA_ "SAEDocument" SG_ 2381450750 Indic13 "NMEA2000";
BA_ "SigType" SG_ 2381450750 Indic13 4;
BA_ "SAEDocument" SG_ 2381450750 Indic12 "NMEA2000";
BA_ "SigType" SG_ 2381450750 Indic12 4;
BA_ "SAEDocument" SG_ 2381450750 Indic11 "NMEA2000";
BA_ "SigType" SG_ 2381450750 Indic11 4;
BA_ "SAEDocument" SG_ 2381450750 Indic10 "NMEA2000";
BA_ "SigType" SG_ 2381450750 Indic10 4;
BA_ "SAEDocument" SG_ 2381450750 Indic9 "NMEA2000";
BA_ "SigType" SG_ 2381450750 Indic9 4;
BA_ "SAEDocument" SG_ 2381450750 Indic8 "NMEA2000";
BA_ "SigType" SG_ 2381450750 Indic8 4;
BA_ "SAEDocument" SG_ 2381450750 Indic7 "NMEA2000";
BA_ "SigType" SG_ 2381450750 Indic7 4;
BA_ "SAEDocument" SG_ 2381450750 Indic6 "NMEA2000";
BA_ "SigType" SG_ 2381450750 Indic6 4;
BA_ "SAEDocument" SG_ 2381450750 Indic5 "NMEA2000";
BA_ "SigType" SG_ 2381450750 Indic5 4;
BA_ "SAEDocument" SG_ 2381450750 Indic4 "NMEA2000";
BA_ "SigType" SG_ 2381450750 Indic4 4;
BA_ "SAEDocument" SG_ 2381450750 Indic3 "NMEA2000";
BA_ "SigType" SG_ 2381450750 Indic3 4;
BA_ "SAEDocument" SG_ 2381450750 Indic2 "NMEA2000";
BA_ "SigType" SG_ 2381450750 Indic2 4;
BA_ "SAEDocument" SG_ 2381450750 Indic1 "NMEA2000";
BA_ "SigType" SG_ 2381450750 Indic1 4;
BA_ "SAEDocument" SG_ 2381450750 IndicatorBankInstance "NMEA2000";
BA_ "SigType" SG_ 2381450750 IndicatorBankInstance 1;
BA_ "SAEDocument" SG_ 2582779134 SID "NMEA2000";
BA_ "SigType" SG_ 2582779134 SID 1;
BA_ "SAEDocument" SG_ 2582779134 BatteryCaseTemp "NMEA2000";
BA_ "SigType" SG_ 2582779134 BatteryCaseTemp 1;
BA_ "SAEDocument" SG_ 2582779134 BatteryCurrent "NMEA2000";
BA_ "SigType" SG_ 2582779134 BatteryCurrent 2;
BA_ "SAEDocument" SG_ 2582779134 BatteryPotential "NMEA2000";
BA_ "SigType" SG_ 2582779134 BatteryPotential 2;
BA_ "SAEDocument" SG_ 2582779134 BatteryInstance "NMEA2000";
BA_ "SigType" SG_ 2582779134 BatteryInstance 1;
BA_ "SAEDocument" SG_ 2381388286 Roll "NMEA2000";
BA_ "SigType" SG_ 2381388286 Roll 2;
BA_ "SAEDocument" SG_ 2381388286 Pitch_ "NMEA2000";
BA_ "SigType" SG_ 2381388286 Pitch_ 1;
BA_ "SAEDocument" SG_ 2381388286 Yaw "NMEA2000";
BA_ "SigType" SG_ 2381388286 Yaw 2;
BA_ "SAEDocument" SG_ 2381388286 SID "NMEA2000";
BA_ "SigType" SG_ 2381388286 SID 1;
BA_ "SAEDocument" SG_ 2314732798 AltitudeDelta "NMEA2000";
BA_ "SigType" SG_ 2314732798 AltitudeDelta 2;
BA_ "SAEDocument" SG_ 2314732798 CourseOverGround "NMEA2000";
BA_ "SigType" SG_ 2314732798 CourseOverGround 1;
BA_ "SAEDocument" SG_ 2314732798 Direction "NMEA2000";
BA_ "SigType" SG_ 2314732798 Direction 4;
BA_ "SAEDocument" SG_ 2314732798 GNSSQuality "NMEA2000";
BA_ "SAEDocument" SG_ 2314732798 TimeDelta "NMEA2000";
BA_ "SigType" SG_ 2314732798 TimeDelta 1;
BA_ "SAEDocument" SG_ 2314732798 SequenceID_ "NMEA2000";
BA_ "SigType" SG_ 2314732798 SequenceID_ 1;
BA_ "SAEDocument" SG_ 2650474750 DestinationID "NMEA2000";
BA_ "SigType" SG_ 2650474750 DestinationID 1;
BA_ "SAEDocument" SG_ 2650474750 AISTransceiverInformation "NMEA2000";
BA_ "SAEDocument" SG_ 2650474750 SourceID "NMEA2000";
BA_ "SigType" SG_ 2650474750 SourceID 1;
BA_ "SAEDocument" SG_ 2650474750 RepeatIndicator "NMEA2000";
BA_ "SAEDocument" SG_ 2650474750 MsgID "NMEA2000";
BA_ "SAEDocument" SG_ 2650472958 TypeOfElectronicPosingDevice "NMEA2000";
BA_ "SAEDocument" SG_ 2650472958 PosDate "NMEA2000";
BA_ "SigType" SG_ 2650472958 PosDate 1;
BA_ "SAEDocument" SG_ 2650472958 AISTransceiverInformation "NMEA2000";
BA_ "SAEDocument" SG_ 2650472958 CommunicationState "NMEA2000";
BA_ "SigType" SG_ 2650472958 CommunicationState 1;
BA_ "SAEDocument" SG_ 2650472958 PosTime "NMEA2000";
BA_ "SigType" SG_ 2650472958 PosTime 1;
BA_ "SAEDocument" SG_ 2650472958 RAIMflag "NMEA2000";
BA_ "SAEDocument" SG_ 2650472958 PosAccuracy "NMEA2000";
BA_ "SAEDocument" SG_ 2650472958 Latitude_ "NMEA2000";
BA_ "SigType" SG_ 2650472958 Latitude_ 2;
BA_ "SAEDocument" SG_ 2650472958 Longitude_ "NMEA2000";
BA_ "SigType" SG_ 2650472958 Longitude_ 2;
BA_ "SAEDocument" SG_ 2650472958 UserID "NMEA2000";
BA_ "SigType" SG_ 2650472958 UserID 1;
BA_ "SAEDocument" SG_ 2650472958 RepeatIndicator "NMEA2000";
BA_ "SAEDocument" SG_ 2650472958 MsgID "NMEA2000";
BA_ "SAEDocument" SG_ 2650475262 SafetyRelatedText "NMEA2000";
BA_ "SigType" SG_ 2650475262 SafetyRelatedText 1;
BA_ "SAEDocument" SG_ 2650475262 AISTransceiverInformation "NMEA2000";
BA_ "SAEDocument" SG_ 2650475262 SourceID "NMEA2000";
BA_ "SigType" SG_ 2650475262 SourceID 1;
BA_ "SAEDocument" SG_ 2650475262 RepeatIndicator "NMEA2000";
BA_ "SAEDocument" SG_ 2650475262 MsgID "NMEA2000";
BA_ "SAEDocument" SG_ 2650474238 DataTerminalEquipment "NMEA2000";
BA_ "SAEDocument" SG_ 2650474238 Altitude_ "NMEA2000";
BA_ "SigType" SG_ 2650474238 Altitude_ 2;
BA_ "SAEDocument" SG_ 2650474238 AISTransceiverInformation "NMEA2000";
BA_ "SAEDocument" SG_ 2650474238 CommunicationState "NMEA2000";
BA_ "SigType" SG_ 2650474238 CommunicationState 1;
BA_ "SAEDocument" SG_ 2650474238 SOG "NMEA2000";
BA_ "SigType" SG_ 2650474238 SOG 1;
BA_ "SAEDocument" SG_ 2650474238 COG "NMEA2000";
BA_ "SigType" SG_ 2650474238 COG 1;
BA_ "SAEDocument" SG_ 2650474238 TimeStamp "NMEA2000";
BA_ "SAEDocument" SG_ 2650474238 RAIMFlag "NMEA2000";
BA_ "SAEDocument" SG_ 2650474238 PosAccuracy "NMEA2000";
BA_ "SAEDocument" SG_ 2650474238 Latitude_ "NMEA2000";
BA_ "SigType" SG_ 2650474238 Latitude_ 2;
BA_ "SAEDocument" SG_ 2650474238 Longitude_ "NMEA2000";
BA_ "SigType" SG_ 2650474238 Longitude_ 2;
BA_ "SAEDocument" SG_ 2650474238 UserID "NMEA2000";
BA_ "SigType" SG_ 2650474238 UserID 1;
BA_ "SAEDocument" SG_ 2650474238 RepeatIndicator "NMEA2000";
BA_ "SAEDocument" SG_ 2650474238 MsgID "NMEA2000";
BA_ "SAEDocument" SG_ 2650475518 SlotOffset21 "NMEA2000";
BA_ "SigType" SG_ 2650475518 SlotOffset21 1;
BA_ "SAEDocument" SG_ 2650475518 MsgID21 "NMEA2000";
BA_ "SAEDocument" SG_ 2650475518 DestinationID2 "NMEA2000";
BA_ "SigType" SG_ 2650475518 DestinationID2 1;
BA_ "SAEDocument" SG_ 2650475518 SlotOffset12 "NMEA2000";
BA_ "SigType" SG_ 2650475518 SlotOffset12 1;
BA_ "SAEDocument" SG_ 2650475518 MsgID12 "NMEA2000";
BA_ "SAEDocument" SG_ 2650475518 SlotOffset11 "NMEA2000";
BA_ "SigType" SG_ 2650475518 SlotOffset11 1;
BA_ "SAEDocument" SG_ 2650475518 MsgID11 "NMEA2000";
BA_ "SAEDocument" SG_ 2650475518 DestinationID1 "NMEA2000";
BA_ "SigType" SG_ 2650475518 DestinationID1 1;
BA_ "SAEDocument" SG_ 2650475518 AISTransceiverInformation "NMEA2000";
BA_ "SAEDocument" SG_ 2650475518 SourceID "NMEA2000";
BA_ "SigType" SG_ 2650475518 SourceID 1;
BA_ "SAEDocument" SG_ 2650475518 RepeatIndicator "NMEA2000";
BA_ "SAEDocument" SG_ 2650475518 MsgID "NMEA2000";
BA_ "SAEDocument" SG_ 2650476030 Increment4 "NMEA2000";
BA_ "SigType" SG_ 2650476030 Increment4 1;
BA_ "SAEDocument" SG_ 2650476030 TimeOut4 "NMEA2000";
BA_ "SigType" SG_ 2650476030 TimeOut4 1;
BA_ "SAEDocument" SG_ 2650476030 NumberOfSlots4 "NMEA2000";
BA_ "SigType" SG_ 2650476030 NumberOfSlots4 1;
BA_ "SAEDocument" SG_ 2650476030 OffsetNumber4 "NMEA2000";
BA_ "SigType" SG_ 2650476030 OffsetNumber4 1;
BA_ "SAEDocument" SG_ 2650476030 Increment3 "NMEA2000";
BA_ "SigType" SG_ 2650476030 Increment3 1;
BA_ "SAEDocument" SG_ 2650476030 TimeOut3 "NMEA2000";
BA_ "SigType" SG_ 2650476030 TimeOut3 1;
BA_ "SAEDocument" SG_ 2650476030 NumberOfSlots3 "NMEA2000";
BA_ "SigType" SG_ 2650476030 NumberOfSlots3 1;
BA_ "SAEDocument" SG_ 2650476030 OffsetNumber3 "NMEA2000";
BA_ "SigType" SG_ 2650476030 OffsetNumber3 1;
BA_ "SAEDocument" SG_ 2650476030 Increment2 "NMEA2000";
BA_ "SigType" SG_ 2650476030 Increment2 1;
BA_ "SAEDocument" SG_ 2650476030 TimeOut2 "NMEA2000";
BA_ "SigType" SG_ 2650476030 TimeOut2 1;
BA_ "SAEDocument" SG_ 2650476030 NumberOfSlots2 "NMEA2000";
BA_ "SigType" SG_ 2650476030 NumberOfSlots2 1;
BA_ "SAEDocument" SG_ 2650476030 OffsetNumber2 "NMEA2000";
BA_ "SigType" SG_ 2650476030 OffsetNumber2 1;
BA_ "SAEDocument" SG_ 2650476030 Increment1 "NMEA2000";
BA_ "SigType" SG_ 2650476030 Increment1 1;
BA_ "SAEDocument" SG_ 2650476030 TimeOut1 "NMEA2000";
BA_ "SigType" SG_ 2650476030 TimeOut1 1;
BA_ "SAEDocument" SG_ 2650476030 NumberOfSlots1 "NMEA2000";
BA_ "SigType" SG_ 2650476030 NumberOfSlots1 1;
BA_ "SAEDocument" SG_ 2650476030 OffsetNumber1 "NMEA2000";
BA_ "SigType" SG_ 2650476030 OffsetNumber1 1;
BA_ "SAEDocument" SG_ 2650476030 AISTransceiverInformation "NMEA2000";
BA_ "SAEDocument" SG_ 2650476030 SourceStationID "NMEA2000";
BA_ "SigType" SG_ 2650476030 SourceStationID 1;
BA_ "SAEDocument" SG_ 2650476030 RepeatIndicator "NMEA2000";
BA_ "SAEDocument" SG_ 2650476030 MsgID "NMEA2000";
BA_ "SAEDocument" SG_ 2583363838 NumberOfBitsInBinaryDataField "NMEA2000";
BA_ "SigType" SG_ 2583363838 NumberOfBitsInBinaryDataField 1;
BA_ "SAEDocument" SG_ 2583363838 Latitude_ "NMEA2000";
BA_ "SigType" SG_ 2583363838 Latitude_ 2;
BA_ "SAEDocument" SG_ 2583363838 Longitude_ "NMEA2000";
BA_ "SigType" SG_ 2583363838 Longitude_ 2;
BA_ "SAEDocument" SG_ 2583363838 AISTransceiverInformation "NMEA2000";
BA_ "SAEDocument" SG_ 2583363838 SourceID "NMEA2000";
BA_ "SigType" SG_ 2583363838 SourceID 1;
BA_ "SAEDocument" SG_ 2583363838 RepeatIndicator "NMEA2000";
BA_ "SAEDocument" SG_ 2583363838 MsgID "NMEA2000";
BA_ "SAEDocument" SG_ 2650473214 CallSign "NMEA2000";
BA_ "SigType" SG_ 2650473214 CallSign 1;
BA_ "SAEDocument" SG_ 2650473214 IMO "NMEA2000";
BA_ "SigType" SG_ 2650473214 IMO 1;
BA_ "SAEDocument" SG_ 2650473214 UserID "NMEA2000";
BA_ "SigType" SG_ 2650473214 UserID 1;
BA_ "SAEDocument" SG_ 2650473214 RepeatIndicator "NMEA2000";
BA_ "SAEDocument" SG_ 2650473214 MsgID "NMEA2000";
BA_ "SAEDocument" SG_ 2448953342 ComminicationStateSelectorFlag "NMEA2000";
BA_ "SAEDocument" SG_ 2448953342 TrueHeading "NMEA2000";
BA_ "SigType" SG_ 2448953342 TrueHeading 1;
BA_ "SAEDocument" SG_ 2448953342 AISTransceiverInformation "NMEA2000";
BA_ "SAEDocument" SG_ 2448953342 CommunicationState "NMEA2000";
BA_ "SigType" SG_ 2448953342 CommunicationState 1;
BA_ "SAEDocument" SG_ 2448953342 SOG "NMEA2000";
BA_ "SigType" SG_ 2448953342 SOG 1;
BA_ "SAEDocument" SG_ 2448953342 COG "NMEA2000";
BA_ "SigType" SG_ 2448953342 COG 1;
BA_ "SAEDocument" SG_ 2448953342 TimeStamp "NMEA2000";
BA_ "SAEDocument" SG_ 2448953342 RAIMflag "NMEA2000";
BA_ "SAEDocument" SG_ 2448953342 PosAccuracy "NMEA2000";
BA_ "SAEDocument" SG_ 2448953342 Latitude_ "NMEA2000";
BA_ "SigType" SG_ 2448953342 Latitude_ 2;
BA_ "SAEDocument" SG_ 2448953342 Longitude_ "NMEA2000";
BA_ "SigType" SG_ 2448953342 Longitude_ 2;
BA_ "SAEDocument" SG_ 2448953342 UserID "NMEA2000";
BA_ "SigType" SG_ 2448953342 UserID 1;
BA_ "SAEDocument" SG_ 2448953342 RepeatIndicator "NMEA2000";
BA_ "SAEDocument" SG_ 2448953342 MsgID "NMEA2000";
BA_ "SAEDocument" SG_ 2448953598 Name "NMEA2000";
BA_ "SigType" SG_ 2448953598 Name 1;
BA_ "SAEDocument" SG_ 2448953598 PosReferencePointAftOfShipsBow "NMEA2000";
BA_ "SigType" SG_ 2448953598 PosReferencePointAftOfShipsBow 1;
BA_ "SAEDocument" SG_ 2448953598 PosReferencePointFromStarboard "NMEA2000";
BA_ "SigType" SG_ 2448953598 PosReferencePointFromStarboard 1;
BA_ "SAEDocument" SG_ 2448953598 ShipBeam "NMEA2000";
BA_ "SigType" SG_ 2448953598 ShipBeam 1;
BA_ "SAEDocument" SG_ 2448953598 ShipLength "NMEA2000";
BA_ "SigType" SG_ 2448953598 ShipLength 1;
BA_ "SAEDocument" SG_ 2448953598 TypeOfElectronicPosingDevice "NMEA2000";
BA_ "SAEDocument" SG_ 2448953598 TrueHeading "NMEA2000";
BA_ "SigType" SG_ 2448953598 TrueHeading 1;
BA_ "SAEDocument" SG_ 2448953598 Ship_CargoType "NMEA2000";
BA_ "SigType" SG_ 2448953598 Ship_CargoType 1;
BA_ "SAEDocument" SG_ 2448953598 SOG "NMEA2000";
BA_ "SigType" SG_ 2448953598 SOG 1;
BA_ "SAEDocument" SG_ 2448953598 COG "NMEA2000";
BA_ "SigType" SG_ 2448953598 COG 1;
BA_ "SAEDocument" SG_ 2448953598 TimeStamp "NMEA2000";
BA_ "SAEDocument" SG_ 2448953598 RAIMflag "NMEA2000";
BA_ "SAEDocument" SG_ 2448953598 PosAccuracy "NMEA2000";
BA_ "SAEDocument" SG_ 2448953598 Latitude_ "NMEA2000";
BA_ "SigType" SG_ 2448953598 Latitude_ 2;
BA_ "SAEDocument" SG_ 2448953598 Longitude_ "NMEA2000";
BA_ "SigType" SG_ 2448953598 Longitude_ 2;
BA_ "SAEDocument" SG_ 2448953598 UserID "NMEA2000";
BA_ "SigType" SG_ 2448953598 UserID 1;
BA_ "SAEDocument" SG_ 2448953598 RepeatIndicator "NMEA2000";
BA_ "SAEDocument" SG_ 2448953598 MsgID "NMEA2000";
BA_ "SAEDocument" SG_ 2448953086 NavigationalStatus "NMEA2000";
BA_ "SAEDocument" SG_ 2448953086 RateOfTurn "NMEA2000";
BA_ "SigType" SG_ 2448953086 RateOfTurn 2;
BA_ "SAEDocument" SG_ 2448953086 TrueHeading "NMEA2000";
BA_ "SigType" SG_ 2448953086 TrueHeading 1;
BA_ "SAEDocument" SG_ 2448953086 AISTransceiverInformation "NMEA2000";
BA_ "SAEDocument" SG_ 2448953086 CommunicationState "NMEA2000";
BA_ "SigType" SG_ 2448953086 CommunicationState 1;
BA_ "SAEDocument" SG_ 2448953086 SOG "NMEA2000";
BA_ "SigType" SG_ 2448953086 SOG 1;
BA_ "SAEDocument" SG_ 2448953086 COG "NMEA2000";
BA_ "SigType" SG_ 2448953086 COG 1;
BA_ "SAEDocument" SG_ 2448953086 TimeStamp "NMEA2000";
BA_ "SAEDocument" SG_ 2448953086 RAIMflag "NMEA2000";
BA_ "SAEDocument" SG_ 2448953086 PosAccuracy "NMEA2000";
BA_ "SAEDocument" SG_ 2448953086 Latitude_ "NMEA2000";
BA_ "SigType" SG_ 2448953086 Latitude_ 2;
BA_ "SAEDocument" SG_ 2448953086 Longitude_ "NMEA2000";
BA_ "SigType" SG_ 2448953086 Longitude_ 2;
BA_ "SAEDocument" SG_ 2448953086 UserID "NMEA2000";
BA_ "SigType" SG_ 2448953086 UserID 1;
BA_ "SAEDocument" SG_ 2448953086 RepeatIndicator "NMEA2000";
BA_ "SAEDocument" SG_ 2448953086 MsgID "NMEA2000";
BA_ "SAEDocument" SG_ 2650473982 NumberOfBitsInBinaryDataField "NMEA2000";
BA_ "SigType" SG_ 2650473982 NumberOfBitsInBinaryDataField 1;
BA_ "SAEDocument" SG_ 2650473982 AISTransceiverInformation "NMEA2000";
BA_ "SAEDocument" SG_ 2650473982 SourceID "NMEA2000";
BA_ "SigType" SG_ 2650473982 SourceID 1;
BA_ "SAEDocument" SG_ 2650473982 RepeatIndicator "NMEA2000";
BA_ "SAEDocument" SG_ 2650473982 MsgID "NMEA2000";
BA_ "SAEDocument" SG_ 2650475774 IncrementB "NMEA2000";
BA_ "SigType" SG_ 2650475774 IncrementB 1;
BA_ "SAEDocument" SG_ 2650475774 OffsetB "NMEA2000";
BA_ "SigType" SG_ 2650475774 OffsetB 1;
BA_ "SAEDocument" SG_ 2650475774 DestinationIDB "NMEA2000";
BA_ "SigType" SG_ 2650475774 DestinationIDB 1;
BA_ "SAEDocument" SG_ 2650475774 IncrementA "NMEA2000";
BA_ "SigType" SG_ 2650475774 IncrementA 1;
BA_ "SAEDocument" SG_ 2650475774 OffsetA "NMEA2000";
BA_ "SigType" SG_ 2650475774 OffsetA 1;
BA_ "SAEDocument" SG_ 2650475774 DestinationIDA "NMEA2000";
BA_ "SigType" SG_ 2650475774 DestinationIDA 1;
BA_ "SAEDocument" SG_ 2650475774 AISTransceiverInformation "NMEA2000";
BA_ "SAEDocument" SG_ 2650475774 SourceID "NMEA2000";
BA_ "SigType" SG_ 2650475774 SourceID 1;
BA_ "SAEDocument" SG_ 2650475774 RepeatIndicator "NMEA2000";
BA_ "SAEDocument" SG_ 2650475774 MsgID "NMEA2000";
BA_ "SAEDocument" SG_ 2650475006 SafetyRelatedText "NMEA2000";
BA_ "SigType" SG_ 2650475006 SafetyRelatedText 1;
BA_ "SAEDocument" SG_ 2650475006 RetransmitFlag "NMEA2000";
BA_ "SAEDocument" SG_ 2650475006 DestinationID "NMEA2000";
BA_ "SigType" SG_ 2650475006 DestinationID 1;
BA_ "SAEDocument" SG_ 2650475006 SequenceNumber_ "NMEA2000";
BA_ "SigType" SG_ 2650475006 SequenceNumber_ 4;
BA_ "SAEDocument" SG_ 2650475006 AISTransceiverInformation "NMEA2000";
BA_ "SAEDocument" SG_ 2650475006 SourceID "NMEA2000";
BA_ "SigType" SG_ 2650475006 SourceID 1;
BA_ "SAEDocument" SG_ 2650475006 RepeatIndicator "NMEA2000";
BA_ "SAEDocument" SG_ 2650475006 MsgID "NMEA2000";
BA_ "SAEDocument" SG_ 2650473470 NumberOfBitsInBinaryDataField "NMEA2000";
BA_ "SigType" SG_ 2650473470 NumberOfBitsInBinaryDataField 1;
BA_ "SAEDocument" SG_ 2650473470 RetransmitFlag "NMEA2000";
BA_ "SAEDocument" SG_ 2650473470 DestinationID "NMEA2000";
BA_ "SigType" SG_ 2650473470 DestinationID 1;
BA_ "SAEDocument" SG_ 2650473470 SequenceNumber_ "NMEA2000";
BA_ "SigType" SG_ 2650473470 SequenceNumber_ 4;
BA_ "SAEDocument" SG_ 2650473470 AISTransceiverInformation "NMEA2000";
BA_ "SAEDocument" SG_ 2650473470 SourceID "NMEA2000";
BA_ "SigType" SG_ 2650473470 SourceID 1;
BA_ "SAEDocument" SG_ 2650473470 RepeatIndicator "NMEA2000";
BA_ "SAEDocument" SG_ 2650473470 MsgID "NMEA2000";
BA_ "SAEDocument" SG_ 2650473726 SequenceNumberForIDn "NMEA2000";
BA_ "SigType" SG_ 2650473726 SequenceNumberForIDn 4;
BA_ "SAEDocument" SG_ 2650473726 SequenceNumberForID1 "NMEA2000";
BA_ "SigType" SG_ 2650473726 SequenceNumberForID1 4;
BA_ "SAEDocument" SG_ 2650473726 DestinationID1 "NMEA2000";
BA_ "SigType" SG_ 2650473726 DestinationID1 1;
BA_ "SAEDocument" SG_ 2650473726 AISTransceiverInformation "NMEA2000";
BA_ "SAEDocument" SG_ 2650473726 SourceID "NMEA2000";
BA_ "SigType" SG_ 2650473726 SourceID 1;
BA_ "SAEDocument" SG_ 2650473726 RepeatIndicator "NMEA2000";
BA_ "SAEDocument" SG_ 2650473726 MsgID "NMEA2000";
BA_ "SPN" SG_ 2365475070 WheelBasedMachineSpeed 1862;
BA_ "SigType" SG_ 2365475070 WheelBasedMachineSpeed 1;
BA_ "SPN" SG_ 2365475070 WheelBasedMachineDistance 1863;
BA_ "SigType" SG_ 2365475070 WheelBasedMachineDistance 1;
BA_ "SPN" SG_ 2365475070 MaxTimeOfTractorPower 1866;
BA_ "SigType" SG_ 2365475070 MaxTimeOfTractorPower 1;
BA_ "SPN" SG_ 2365475070 WheelBasedMachineDirection 1864;
BA_ "SigType" SG_ 2365475070 WheelBasedMachineDirection 4;
BA_ "SPN" SG_ 2365475070 KeySwitchState 1865;
BA_ "SigType" SG_ 2365475070 KeySwitchState 4;
BA_ "SPN" SG_ 2365475070 StartStopState 5203;
BA_ "SigType" SG_ 2365475070 StartStopState 4;
BA_ "SPN" SG_ 2365475070 OperatorDirectionReversed 5244;
BA_ "SigType" SG_ 2365475070 OperatorDirectionReversed 5;
BA_ "SPN" SG_ 2565340926 IdentityNumber 2837;
BA_ "SAEDocument" SG_ 2565340926 IdentityNumber "J1939-81";
BA_ "SigType" SG_ 2565340926 ManufacturerCode 1;
BA_ "SPN" SG_ 2565340926 ManufacturerCode 2838;
BA_ "SAEDocument" SG_ 2565340926 ManufacturerCode "NMEA2000";
BA_ "SPN" SG_ 2565340926 ECUInstance 2840;
BA_ "SAEDocument" SG_ 2565340926 ECUInstance "J1939-81";
BA_ "SPN" SG_ 2565340926 FunctionInstance 2839;
BA_ "SAEDocument" SG_ 2565340926 FunctionInstance "J1939-81";
BA_ "SPN" SG_ 2565340926 Function 2841;
BA_ "SAEDocument" SG_ 2565340926 Function "J1939-81";
BA_ "SAEDocument" SG_ 2565340926 VehicleSystem2 "J1939-81";
BA_ "SPN" SG_ 2565340926 VehicleSystemInstance 2843;
BA_ "SAEDocument" SG_ 2565340926 VehicleSystemInstance "J1939-81";
BA_ "SPN" SG_ 2565340926 IndustryGroup 2846;
BA_ "SAEDocument" SG_ 2565340926 IndustryGroup "NMEA2000";
BA_ "SPN" SG_ 2565340926 ArbitraryAddressCapable 2844;
BA_ "SAEDocument" SG_ 2565340926 ArbitraryAddressCapable "J1939-81";
BA_ "SystemSignalLongSymbol" SG_ 2565340926 ChangeChildPositionParentOb_0000 "ChangeChildPositionParentObjectID";
BA_ "SystemSignalLongSymbol" SG_ 2565340926 ChangeChildLocationParentOb_0000 "ChangeChildLocationParentObjectID";
BA_ "SigType" SG_ 2565340926 VersionLabelToStore 3;
BA_ "SigType" SG_ 2565340926 VersionLabelToLoad 3;
BA_ "SigType" SG_ 2565340926 VersionLabelToDelete 3;
BA_ "SigType" SG_ 2565340926 ExtendedVersionLabelToStore 3;
BA_ "SigType" SG_ 2565340926 ExtendedVersionLabelToLoad 3;
BA_ "SigType" SG_ 2565340926 ExtendedVersionLabelToDelete 3;
BA_ "SigType" SG_ 2565340926 NewStringValue 9;
VAL_ 2583299070 OpMode 7 "Null" 6 "Error" 4 "Reserved" 3 "Auto" 2 "3D" 1 "2D" 0 "1D" ;
VAL_ 2583299070 SetMode 7 "Null" 6 "Error" 4 "Reserved" 3 "Auto" 2 "3D" 1 "2D" 0 "1D" ;
VAL_ 2583299070 SID 255 "nVldPsFxTTItTRng0T250FrVldPstnFx" ;
VAL_ 2583298814 UseAntennaAltitudeFor2DMode 3 "[Unavailable, Unknown]" 2 "Error" 1 "[Yes, On, Enabled, Set, '1']" 0 "[No, Off, Disabled, Reset, '0']" ;
VAL_ 2583298814 Pos_VelocityFilter 2 "Error" 1 "[Yes, On, Enabled, Set, '1']" 0 "[No, Off, Disabled, Reset, '0']" 3 "[Unavailable, Unknown]" ;
VAL_ 2583298814 DGNSSMode 7 "Null" 6 "Error" 5 "Reserved" 4 "RTK Differential Corrections" 3 "RTCA SC159 Network Corrections" 2 "RTCMSC104PseudorangeCorrections" 1 "Auto" 0 "Off" ;
VAL_ 2583298814 GNSSMode 7 "Null" 6 "Error" 4 "Reserved" 3 "Auto" 2 "3D" 1 "2D" 0 "1D" ;
VAL_ 2583303422 PRN 96 "GLONASSFrGLONASSStlltsArIdntfdBy" 64 "SBASStlltBsdAgmentationSystem65" 1 "GPS, 

33-" 0 "value not used" ;
VAL_ 2582778366 FluidType 15 "Data not available" 14 "Error" 13 "Reserved" 6 "Reserved,

  thru" 5 "Black Water (Sewage)" 4 "Oil" 3 "Live Well" 2 "Waste Water" 1 "Fresh Water" 0 "Fuel" ;
VAL_ 2582778366 FluidInstance 15 "Instance number 0 to 15" ;
VAL_ 2516387838 HumidityInstance 3 "Data Not Available" 2 "reserved" 1 "Outside Humidity" 0 "Inside Humidity" ;
VAL_ 2516387838 TempInstance 63 "Data Not Available" 62 "Reserve" 5 "Reserve,

 thru" 4 "Main Cabin Temperature" 3 "Engine Room Temperature" 2 "Inside Temperature" 1 "Outside Temperature" 0 "Sea Temperature" ;
VAL_ 2516387838 SequenceID_ 255 "nVldPsFxTTItTRng0T250FrVldPstnFx" ;
VAL_ 2516387582 SequenceID_ 255 "nVldPsFxTTItTRng0T250FrVldPstnFx" ;
VAL_ 2515667710 EngInstance 255 "Not available" 254 "Error" 253 "Reserve" 1 "DlEngStrBrdTStrnStrbrdNInstncNWh" 0 "SingleEngDualEnginePort" ;
VAL_ 2314338558 EngInstance 255 "Not available" 254 "Error" 253 "Reserve" 1 "DlEngStrBrdTStrnStrbrdNInstncNWh" 0 "SingleEngDualEnginePort" ;
VAL_ 2314338814 EngInstance 255 "Not available" 254 "Error" 253 "Reserve" 1 "DlEngStrBrdTStrnStrbrdNInstncNWh" 0 "SingleEngDualEnginePort" ;
VAL_ 2582975486 MeasurementTime 0 "midnight,  time is in UTC" ;
VAL_ 2382238206 SID 255 "nVldPsFxTTItTRng0T250FrVldPstnFx" ;
VAL_ 2382238206 Set_COG_HeadingRef 3 "Null" 2 "Error" 1 "Magnetic" 0 "True" ;
VAL_ 2382238206 DataMode 15 "Data not available" 14 "Error" 4 "Manual mode" 3 "Simulator mode" 2 "Estimated mode" 1 "Differential, enhanced mode" 0 "Autonomous mode" ;
VAL_ 2583301630 SatelliteID 96 "GLONASSFrGLONASSStlltsArIdntfdBy" 64 "SBASStlltBsdAgmentationSystem65" 1 "GPS, 

33-" 0 "value not used" ;
VAL_ 2583301630 StationHealth 21 "Reserved" 4 "InTestModeDONOTUSE0x05" 3 "Healthy & in Test Mode" 2 "Healthy & Operational" 1 "Unmonitored" 0 "Not Working" ;
VAL_ 2583301630 ReferenceStationType 15 "Null" 14 "Error" 13 "Reserved" 1 "GLONASS; 

0x3 to" 0 "GPS" ;
VAL_ 2583301630 SequenceID_ 255 "nVldPsFxTTItTRng0T250FrVldPstnFx" ;
VAL_ 2583499518 MeasurementTime 0 "midnight,  time is in UTC" ;
VAL_ 2583499518 State 111 "Unavailable, Unknown" 110 "Error" 101 "Reserved" 10 "Ebb" 1 "Slack" 0 "Flood" ;
VAL_ 2583499518 Mode 15 "Data not available" 14 "Error" 4 "Manual mode" 3 "Simulator mode" 2 "Estimated mode" 1 "Differential, enhanced mode" 0 "Autonomous mode" ;
VAL_ 2381906942 NavigationTerminated 3 "[Unavailable, Unknown]" 2 "Error" 1 "[Yes, On, Enabled, Set, '1']" 0 "[No, Off, Disabled, Reset, '0']" ;
VAL_ 2381906942 XTEMode 15 "Data not available" 14 "Error" 4 "Manual mode" 3 "Simulator mode" 2 "Estimated mode" 1 "Differential, enhanced mode" 0 "Autonomous mode" ;
VAL_ 2381906942 SID 255 "nVldPsFxTTItTRng0T250FrVldPstnFx" ;
VAL_ 2583238398 DestinationMarkType 15 "Null" 14 "Error" 5 "Reserved" 4 "Waypoint" 3 "Wheelover" 2 "Reference (general)" 1 "Turning Point" 0 "Collision" ;
VAL_ 2583238398 OriginMarkType 15 "Null" 14 "Error" 5 "Reserved" 4 "Waypoint" 3 "Wheelover" 2 "Reference (general)" 1 "Turning Point" 0 "Collision" ;
VAL_ 2583238398 CalculationType 3 "Null" 2 "Error" 1 "Rhumb Line calculations" 0 "Great Circle calculations" ;
VAL_ 2583238398 BearingRef 3 "Null" 2 "Error" 1 "Magnetic" 0 "True" ;
VAL_ 2583238398 SID 255 "nVldPsFxTTItTRng0T250FrVldPstnFx" ;
VAL_ 2381450750 Indic28 3 "[Unavailable, Unknown]" 2 "Error" 1 "[Yes, On, Enabled, Set, '1']" 0 "[No, Off, Disabled, Reset, '0']" ;
VAL_ 2381450750 Indic27 3 "[Unavailable, Unknown]" 2 "Error" 1 "[Yes, On, Enabled, Set, '1']" 0 "[No, Off, Disabled, Reset, '0']" ;
VAL_ 2381450750 Indic26 3 "[Unavailable, Unknown]" 2 "Error" 1 "[Yes, On, Enabled, Set, '1']" 0 "[No, Off, Disabled, Reset, '0']" ;
VAL_ 2381450750 Indic25 3 "[Unavailable, Unknown]" 2 "Error" 1 "[Yes, On, Enabled, Set, '1']" 0 "[No, Off, Disabled, Reset, '0']" ;
VAL_ 2381450750 Indic24 3 "[Unavailable, Unknown]" 2 "Error" 1 "[Yes, On, Enabled, Set, '1']" 0 "[No, Off, Disabled, Reset, '0']" ;
VAL_ 2381450750 Indic23 3 "[Unavailable, Unknown]" 2 "Error" 1 "[Yes, On, Enabled, Set, '1']" 0 "[No, Off, Disabled, Reset, '0']" ;
VAL_ 2381450750 Indic22 3 "[Unavailable, Unknown]" 2 "Error" 1 "[Yes, On, Enabled, Set, '1']" 0 "[No, Off, Disabled, Reset, '0']" ;
VAL_ 2381450750 Indic21 3 "[Unavailable, Unknown]" 2 "Error" 1 "[Yes, On, Enabled, Set, '1']" 0 "[No, Off, Disabled, Reset, '0']" ;
VAL_ 2381450750 Indic20 3 "[Unavailable, Unknown]" 2 "Error" 1 "[Yes, On, Enabled, Set, '1']" 0 "[No, Off, Disabled, Reset, '0']" ;
VAL_ 2381450750 Indic19 3 "[Unavailable, Unknown]" 2 "Error" 1 "[Yes, On, Enabled, Set, '1']" 0 "[No, Off, Disabled, Reset, '0']" ;
VAL_ 2381450750 Indic18 3 "[Unavailable, Unknown]" 2 "Error" 1 "[Yes, On, Enabled, Set, '1']" 0 "[No, Off, Disabled, Reset, '0']" ;
VAL_ 2381450750 Indic17 3 "[Unavailable, Unknown]" 2 "Error" 1 "[Yes, On, Enabled, Set, '1']" 0 "[No, Off, Disabled, Reset, '0']" ;
VAL_ 2381450750 Indic16 3 "[Unavailable, Unknown]" 2 "Error" 1 "[Yes, On, Enabled, Set, '1']" 0 "[No, Off, Disabled, Reset, '0']" ;
VAL_ 2381450750 Indic15 3 "[Unavailable, Unknown]" 2 "Error" 1 "[Yes, On, Enabled, Set, '1']" 0 "[No, Off, Disabled, Reset, '0']" ;
VAL_ 2381450750 Indic14 3 "[Unavailable, Unknown]" 2 "Error" 1 "[Yes, On, Enabled, Set, '1']" 0 "[No, Off, Disabled, Reset, '0']" ;
VAL_ 2381450750 Indic13 3 "[Unavailable, Unknown]" 2 "Error" 1 "[Yes, On, Enabled, Set, '1']" 0 "[No, Off, Disabled, Reset, '0']" ;
VAL_ 2381450750 Indic12 3 "[Unavailable, Unknown]" 2 "Error" 1 "[Yes, On, Enabled, Set, '1']" 0 "[No, Off, Disabled, Reset, '0']" ;
VAL_ 2381450750 Indic11 3 "[Unavailable, Unknown]" 2 "Error" 1 "[Yes, On, Enabled, Set, '1']" 0 "[No, Off, Disabled, Reset, '0']" ;
VAL_ 2381450750 Indic10 3 "[Unavailable, Unknown]" 2 "Error" 1 "[Yes, On, Enabled, Set, '1']" 0 "[No, Off, Disabled, Reset, '0']" ;
VAL_ 2381450750 Indic9 3 "[Unavailable, Unknown]" 2 "Error" 1 "[Yes, On, Enabled, Set, '1']" 0 "[No, Off, Disabled, Reset, '0']" ;
VAL_ 2381450750 Indic8 3 "[Unavailable, Unknown]" 2 "Error" 1 "[Yes, On, Enabled, Set, '1']" 0 "[No, Off, Disabled, Reset, '0']" ;
VAL_ 2381450750 Indic7 3 "[Unavailable, Unknown]" 2 "Error" 1 "[Yes, On, Enabled, Set, '1']" 0 "[No, Off, Disabled, Reset, '0']" ;
VAL_ 2381450750 Indic6 3 "[Unavailable, Unknown]" 2 "Error" 1 "[Yes, On, Enabled, Set, '1']" 0 "[No, Off, Disabled, Reset, '0']" ;
VAL_ 2381450750 Indic5 3 "[Unavailable, Unknown]" 2 "Error" 1 "[Yes, On, Enabled, Set, '1']" 0 "[No, Off, Disabled, Reset, '0']" ;
VAL_ 2381450750 Indic4 3 "[Unavailable, Unknown]" 2 "Error" 1 "[Yes, On, Enabled, Set, '1']" 0 "[No, Off, Disabled, Reset, '0']" ;
VAL_ 2381450750 Indic3 3 "[Unavailable, Unknown]" 2 "Error" 1 "[Yes, On, Enabled, Set, '1']" 0 "[No, Off, Disabled, Reset, '0']" ;
VAL_ 2381450750 Indic2 3 "[Unavailable, Unknown]" 2 "Error" 1 "[Yes, On, Enabled, Set, '1']" 0 "[No, Off, Disabled, Reset, '0']" ;
VAL_ 2381450750 Indic1 3 "[Unavailable, Unknown]" 2 "Error" 1 "[Yes, On, Enabled, Set, '1']" 0 "[No, Off, Disabled, Reset, '0']" ;
VAL_ 2582779134 SID 255 "nVldPsFxTTItTRng0T250FrVldPstnFx" ;
VAL_ 2381388286 SID 255 "nVldPsFxTTItTRng0T250FrVldPstnFx" ;
VAL_ 2314732798 Direction 3 "Null" 2 "Error" 1 "Magnetic" 0 "True" ;
VAL_ 2314732798 GNSSQuality 15 "NllPrcsGNSSMnsNDlbrtDgrdtnAndHgh" 14 "Error" 9 "Reserved" 8 "Simulate mode" 7 "Manual Input" 6 "Estimated (DR) mode" 5 "RTK Float" 4 "RTK Fixed Integer" 3 "Precise GNSS*" 2 "DGNSS fix" 1 "GNSS fix" 0 "no GPS" ;
VAL_ 2314732798 SequenceID_ 255 "nVldPsFxTTItTRng0T250FrVldPstnFx" ;
VAL_ 2650474750 AISTransceiverInformation 4 "Own information not broadcast" 3 "Channel B VDL transmission" 5 "Reserved" 2 "Channel A VDL transmission" 1 "Channel B VDL reception" 0 "Channel A VDL reception" ;
VAL_ 2650474750 RepeatIndicator 3 "FnlRTrnsSITURM13711FrMrInfrmton" 2 "Second retransmission" 1 "First retransmission" 0 "Default" ;
VAL_ 2650472958 TypeOfElectronicPosingDevice 8 "RsrvFrFtrUsSITURM13711FrMrInfrmt" ;
VAL_ 2650472958 AISTransceiverInformation 4 "Own information not broadcast" 3 "Channel B VDL transmission" 5 "Reserved" 2 "Channel A VDL transmission" 1 "Channel B VDL reception" 0 "Channel A VDL reception" ;
VAL_ 2650472958 PosTime 0 "midnight,  time is in UTC" ;
VAL_ 2650472958 RAIMflag 1 "RAIMInUsSITURM13711FrMrInfrmton" 0 "RAIM not in use (default)" ;
VAL_ 2650472958 RepeatIndicator 3 "FnlRTrnsSITURM13711FrMrInfrmton" 2 "Second retransmission" 1 "First retransmission" 0 "Default" ;
VAL_ 2650475262 AISTransceiverInformation 4 "Own information not broadcast" 3 "Channel B VDL transmission" 5 "Reserved" 2 "Channel A VDL transmission" 1 "Channel B VDL reception" 0 "Channel A VDL reception" ;
VAL_ 2650475262 RepeatIndicator 3 "FnlRTrnsSITURM13711FrMrInfrmton" 2 "Second retransmission" 1 "First retransmission" 0 "Default" ;
VAL_ 2650474238 AISTransceiverInformation 4 "Own information not broadcast" 3 "Channel B VDL transmission" 5 "Reserved" 2 "Channel A VDL transmission" 1 "Channel B VDL reception" 0 "Channel A VDL reception" ;
VAL_ 2650474238 TimeStamp 63 "PsngSystmIsInprtvSITURM13711FrMr" 62 "ElctrncPsFxngSystmOprtsInEstMde" 61 "PosingSystemIsInManualInputMode" 60 "timeStampNotAvailable" 0 "UTCSecondWhenReportWasGenerated" ;
VAL_ 2650474238 RAIMFlag 1 "RAIMInUsSITURM13711FrMrInfrmton" 0 "RAIM not in use (default)" ;
VAL_ 2650474238 RepeatIndicator 3 "FnlRTrnsSITURM13711FrMrInfrmton" 2 "Second retransmission" 1 "First retransmission" 0 "Default" ;
VAL_ 2650475518 AISTransceiverInformation 4 "Own information not broadcast" 3 "Channel B VDL transmission" 5 "Reserved" 2 "Channel A VDL transmission" 1 "Channel B VDL reception" 0 "Channel A VDL reception" ;
VAL_ 2650475518 RepeatIndicator 3 "FnlRTrnsSITURM13711FrMrInfrmton" 2 "Second retransmission" 1 "First retransmission" 0 "Default" ;
VAL_ 2650476030 AISTransceiverInformation 4 "Own information not broadcast" 3 "Channel B VDL transmission" 5 "Reserved" 2 "Channel A VDL transmission" 1 "Channel B VDL reception" 0 "Channel A VDL reception" ;
VAL_ 2650476030 RepeatIndicator 3 "FnlRTrnsSITURM13711FrMrInfrmton" 2 "Second retransmission" 1 "First retransmission" 0 "Default" ;
VAL_ 2583363838 AISTransceiverInformation 4 "Own information not broadcast" 3 "Channel B VDL transmission" 5 "Reserved" 2 "Channel A VDL transmission" 1 "Channel B VDL reception" 0 "Channel A VDL reception" ;
VAL_ 2583363838 RepeatIndicator 3 "FnlRTrnsSITURM13711FrMrInfrmton" 2 "Second retransmission" 1 "First retransmission" 0 "Default" ;
VAL_ 2650473214 RepeatIndicator 3 "FnlRTrnsSITURM13711FrMrInfrmton" 2 "Second retransmission" 1 "First retransmission" 0 "Default" ;
VAL_ 2448953342 AISTransceiverInformation 4 "Own information not broadcast" 3 "Channel B VDL transmission" 5 "Reserved" 2 "Channel A VDL transmission" 1 "Channel B VDL reception" 0 "Channel A VDL reception" ;
VAL_ 2448953342 TimeStamp 63 "PsngSystmIsInprtvSITURM13711FrMr" 62 "ElctrncPsFxngSystmOprtsInEstMde" 61 "PosingSystemIsInManualInputMode" 60 "timeStampNotAvailable" 0 "UTCSecondWhenReportWasGenerated" ;
VAL_ 2448953342 RAIMflag 1 "RAIMInUsSITURM13711FrMrInfrmton" 0 "RAIM not in use (default)" ;
VAL_ 2448953342 RepeatIndicator 3 "FnlRTrnsSITURM13711FrMrInfrmton" 2 "Second retransmission" 1 "First retransmission" 0 "Default" ;
VAL_ 2448953598 TypeOfElectronicPosingDevice 8 "RsrvFrFtrUsSITURM13711FrMrInfrmt" ;
VAL_ 2448953598 Ship_CargoType 255 "ReservedForFuture" 199 "ReservedForRegional200" 1 "100" ;
VAL_ 2448953598 TimeStamp 63 "PsngSystmIsInprtvSITURM13711FrMr" 62 "ElctrncPsFxngSystmOprtsInEstMde" 61 "PosingSystemIsInManualInputMode" 60 "timeStampNotAvailable" 0 "UTCSecondWhenReportWasGenerated" ;
VAL_ 2448953598 RAIMflag 1 "RAIMInUsSITURM13711FrMrInfrmton" 0 "RAIM not in use (default)" ;
VAL_ 2448953598 RepeatIndicator 3 "FnlRTrnsSITURM13711FrMrInfrmton" 2 "Second retransmission" 1 "First retransmission" 0 "Default" ;
VAL_ 2448953086 NavigationalStatus 15 "ntDfndSITURM13711FrMrInfrmation" 14 "reserved for future use" 10 "rsrvdFrFtrAmndmntOfNvgtnlSttsFrS" 8 "under way sailing" 7 "engaged in fishing" 6 "aground" 5 "moored" 4 "constrained by her draught" 3 "restricted manoeuvrability" 2 "not under command" 1 "at anchor" 0 "under way using engine" ;
VAL_ 2448953086 AISTransceiverInformation 4 "Own information not broadcast" 3 "Channel B VDL transmission" 5 "Reserved" 2 "Channel A VDL transmission" 1 "Channel B VDL reception" 0 "Channel A VDL reception" ;
VAL_ 2448953086 TimeStamp 63 "PsngSystmIsInprtvSITURM13711FrMr" 62 "ElctrncPsFxngSystmOprtsInEstMde" 61 "PosingSystemIsInManualInputMode" 60 "timeStampNotAvailable" 0 "UTCSecondWhenReportWasGenerated" ;
VAL_ 2448953086 RAIMflag 1 "RAIMInUsSITURM13711FrMrInfrmton" 0 "RAIM not in use (default)" ;
VAL_ 2448953086 RepeatIndicator 3 "FnlRTrnsSITURM13711FrMrInfrmton" 2 "Second retransmission" 1 "First retransmission" 0 "Default" ;
VAL_ 2650473982 AISTransceiverInformation 4 "Own information not broadcast" 3 "Channel B VDL transmission" 5 "Reserved" 2 "Channel A VDL transmission" 1 "Channel B VDL reception" 0 "Channel A VDL reception" ;
VAL_ 2650473982 RepeatIndicator 3 "FnlRTrnsSITURM13711FrMrInfrmton" 2 "Second retransmission" 1 "First retransmission" 0 "Default" ;
VAL_ 2650475774 AISTransceiverInformation 4 "Own information not broadcast" 3 "Channel B VDL transmission" 5 "Reserved" 2 "Channel A VDL transmission" 1 "Channel B VDL reception" 0 "Channel A VDL reception" ;
VAL_ 2650475774 RepeatIndicator 3 "FnlRTrnsSITURM13711FrMrInfrmton" 2 "Second retransmission" 1 "First retransmission" 0 "Default" ;
VAL_ 2650475006 AISTransceiverInformation 4 "Own information not broadcast" 3 "Channel B VDL transmission" 5 "Reserved" 2 "Channel A VDL transmission" 1 "Channel B VDL reception" 0 "Channel A VDL reception" ;
VAL_ 2650475006 RepeatIndicator 3 "FnlRTrnsSITURM13711FrMrInfrmton" 2 "Second retransmission" 1 "First retransmission" 0 "Default" ;
VAL_ 2650473470 AISTransceiverInformation 4 "Own information not broadcast" 3 "Channel B VDL transmission" 5 "Reserved" 2 "Channel A VDL transmission" 1 "Channel B VDL reception" 0 "Channel A VDL reception" ;
VAL_ 2650473470 RepeatIndicator 3 "FnlRTrnsSITURM13711FrMrInfrmton" 2 "Second retransmission" 1 "First retransmission" 0 "Default" ;
VAL_ 2650473726 AISTransceiverInformation 4 "Own information not broadcast" 3 "Channel B VDL transmission" 5 "Reserved" 2 "Channel A VDL transmission" 1 "Channel B VDL reception" 0 "Channel A VDL reception" ;
VAL_ 2650473726 RepeatIndicator 3 "FnlRTrnsSITURM13711FrMrInfrmton" 2 "Second retransmission" 1 "First retransmission" 0 "Default" ;
VAL_ 2365475070 WheelBasedMachineDirection 0 "Reverse" 1 "Forward" 2 "ErrorIndicator" 3 "NotAvailable" ;
VAL_ 2365475070 KeySwitchState 0 "KeySwitchOff" 1 "KeySwitchNotOff" 2 "ErrorIndication" 3 "NotAvailable" ;
VAL_ 2365475070 StartStopState 0 "Stop or disable implement work" 1 "Start or enable implement work" 2 "Reserved" 3 "Don't Care" ;
VAL_ 2365475070 OperatorDirectionReversed 3 "Not available" 2 "Error" 1 "Reversed" 0 "Not reversed" ;
VAL_ 2565340926 KeyActivationCode 3 "KeyPressAborted" 0 "KeyHasBeenReleased" 1 "KeyHasBeenPressed" 2 "KeyIsStillHeld" ;
VAL_ 2565340926 ButtonActivationCode 3 "ButtonPressAborted" 0 "ButtonHasBeenUnlatched" 1 "ButtonHasBeenLatched" 2 "ButtonsStillHeld" ;
VAL_ 2565340926 LockUnlockCommand 1 "LockMask" 0 "UnlockMask" ;
VAL_ 2565340926 KeyObjectID 0 "KeyHasBeenReleased" 1 "KeyHasBeenPressed" 2 "KeyIsStillHeld" ;
VAL_ 2565340926 ButtonObjectID 0 "ButtonHasBeenUnlatched" 1 "ButtonHasBeenLatched" 2 "ButtonsStillHeld" ;
VAL_ 2565340926 Status_1 1 "Shown" 0 "Hidden" ;
VAL_ 2565340926 VTSelectInputObjectStatus 0 "ObjectIsDeselected" 1 "ObjectIsSelected" ;
VAL_ 2565340926 SubCommandID 20 "CopyViewportToPictureGraphic" 19 "CopyCanvasToPictureGraphic" 18 "DrawVTObject" 17 "ChangeViewportSize" 16 "PanAndZoomViewport" 15 "ZoomViewport" 14 "PanViewport" 13 "DrawText" 12 "DrawPolygon" 11 "DrawClosedEllipse" 10 "DrawRectangle" 9 "DrawLine" 8 "DrawPoint" 7 "EraseRectangle" 6 "SetFontAttributesID" 5 "SetFillAttributesObjectID" 4 "SetLineAttributesObjectID" 3 "SetBackgroundColour" 2 "SetForegroundColour" 1 "MoveGraphicsCursor" 0 "SetGraphicsCursor" ;
VAL_ 2565340926 KeyObjectParentID 0 "KeyHasBeenReleased" 1 "KeyHasBeenPressed" 2 "KeyIsStillHeld" ;
VAL_ 2565340926 ButtonObjectParentID 0 "ButtonHasBeenUnlatched" 1 "ButtonHasBeenLatched" 2 "ButtonsStillHeld" ;
VAL_ 2565340926 ManufacturerCode 520 "Trapeze" 519 "Peeters Landbouwmachines b.v." 518 "Transas USA Inc." 517 "Noland Engineering" 516 "AVAT Automation GmbH" 515 "GINAF Trucks Nederland B.V." 514 "DISTek Integration, Inc." 513 "FarmscanAg" 512 "Inpower LLC" 511 "Sulky" 510 "Marinesoft Co. Ltd" 509 "MOTORTECH GmbH" 508 "Transtech Innovations" 507 "Test Center ISOBUS" 506 "IHI STAR Machinery Corporation" 505 "Yetter Farm Equipment" 504 "Vesper Marine" 503 "Naviop S.R.L." 502 "Attwood Corporation" 501 "Agrotronix S.A." 500 "Oxbo International Corporation" 499 "LCJ Capteurs" 498 "Innovative Design Solutions, Inc." 497 "SENTRON Sistemas Embarcados" 496 "W. Gessmann GmbH" 495 "HOLMER Maschinenbau GmbH" 494 "Synerject" 493 "Watcheye" 492 "Inergy Automotive Systems" 491 "Penny and Giles Ltd" 490 "QuikQ" 489 "Appareo Systems" 488 "The Charles Machine Works, Inc." 487 "DSE Test Solutions A/S" 486 "Westport Innovations Inc." 485 "MATT automotive" 484 "Headsight Inc." 483 "Valeo" 482 "Tricon Electronics" 481 "Chetco Digital Instruments" 480 "EnerDel, Inc." 454 "NGK Spark Plug Co. Ltd" 453 "Cooper Bussmann" 452 "WIKA Alexander Wiegand SE & Co. KG" 451 "Parker Hannifin Corp" 450 "Dycor Technologies Ltd." 449 "Polaris Industries Inc" 448 "Stanadyne Corporation, Electronics Systems" 447 "Great Plains Mfg." 446 "CertTech, L.L.C." 445 "KAT MECHATRONIC, Electronic Product Division" 444 "ITT Power Solutions" 443 "SignalQuest, Inc." 442 "Horsch Maschinen GmbH" 441 "PTG Reifendruckregelsysteme GmbH" 440 "Cummins Power Generation" 439 "Hyundai Heavy Industries" 438 "Comar Systems Ltd" 437 "Digital Yacht Limited" 436 "Kinze Manufacturing" 435 "Zunhammer GmbH" 434 "Stored Energy Systems" 433 "Rowe Electronics" 432 "S&A Systems, Inc." 431 "Tohatsu Corporation" 430 "Auteq Telematica S.A." 479 "Vapor Bus International" 478 "OceanSat BV" 477 "OilQuick AB" 476 "Hummingbird Marine Electronics" 475 "GME" 474 "Persen Technologies Inc." 473 "Boss Industries, Inc." 472 "Tenneco Inc." 471 "Sea Cross Marine AB" 470 "SI-TEX Marine Electronics" 469 "RA Consulting GmbH" 468 "Tyco Fire Protection Products" 467 "Lely Industries N.V." 466 "Veethree Electronics and Marine LLC" 465 "Ashcroft Inc" 464 "Leach International Corporation" 463 "PROBOTIQ" 462 "IHI Shibaura Machinery Corporation" 461 "HAWE Hydraulik SE" 460 "San Giorgio S.E.I.N." 459 "Alltek Marine Electronics Corp" 458 "Control Solutions, Inc." 457 "RUSELPROM-ElectricDrive Ltd" 456 "General Kinetics" 455 "ADZ NAGANO GmbH" 429 "Rota Engineering Ltd." 428 "Mfg_428" 427 "em-trak Marine Electronics Ltd" 426 "Egersund Marine Electronics AS" 425 "Methode Electronics Inc, MDI" 424 "Odyne LLC" 423 "BSM Wireless, Inc." 422 "True Heading AB" 421 "Vertex Standard Co., Ltd" 420 "Vermeer Corporation, ACS Group" 419 "Fusion Electronics Ltd" 418 "Intellistick Inc" 417 "KZValve" 416 "Kubota Corporation" 415 "Valid Manufacturing Ltd." 414 "Cattron Group International" 413 "Datapross Nijbroek bv" 412 "WebTech Wireless Inc." 411 "Hy-Drive Technologies Ltd." 410 "COBO S.p.A. Divisione 3B6" 409 "Transfluid S.r.L." 408 "Corvus Energy Ltd." 407 "Comtech Mobile Datacom" 406 "Vecima Networks Inc." 405 "Wema System AS" 404 "Com Nav Marine Ltd" 403 "Trackwell ADS, Inc." 402 "Simma Software, Inc." 401 "Torqeedo GmbH" 400 "Livorsi Marine" 399 "ISEKI & Co., Ltd." 398 "Hilite International" 397 "Sanyo-kiki Co Ltd." 396 "Beyond Measure" 395 "GENTEC S.R.L." 394 "Capi 2 Nederland BV" 393 "Harvest Tec, Inc" 392 "Tianyuan Technology Co Ltd." 391 "Electronic Design for Industry, Inc" 390 "Partech Inc." 389 "Benchmark Electronics, Minnesota Division" 388 "Innomatix, LLC" 387 "Orscheln Products, LLC" 386 "JLG Automation BVBA" 385 "Johnson Outdoor Marine Electronics" 384 "Camano Light" 383 "MCL Industries" 382 "National Agricultural and Food Research Organization" 380 "Suntech International Ltd." 379 "Yamabiko Corporation" 378 "Glendinning Marine Products" 377 "ifm electronic gmbh" 376 "Quake Global" 375 "Williams Controls Inc." 372 "Delphi" 381 "B&G" 374 "Northern Lights, Inc." 373 "Electronic Design Inc." 371 "Heinzmann GmbH & Co. KG" 370 "Rolls-Royce Marine AS" 369 "Power Torque Engineering Ltd" 368 "HANSENHOF_electronic" 367 "Fliegl Agrartechnik" 366 "Viewnyx Corp." 365 "Digi-Star, LLC" 364 "OEM Controls Inc." 363 "BEI Duncan" 362 "Alois Poettinger Maschinenfabrik GmbH" 361 "InMach" 360 "HJS Emission Technology GmbH & Co KG" 359 "Ludwig Bergmann GmbH" 358 "Victron Energy BV" 357 "Hardi International A/S" 356 "Fischer Panda Generators, Inc" 355 "Mastervolt International B.V." 354 "Junkkari OY" 353 "Hegemon Electronics, Inc." 352 "SAME DEUTZ-FAHR" 351 "Thrane & Thrane" 350 "Noris Marine Systems GmbH & Co KG" 349 "Suonentiet" 348 "Amazonen Werke H. Dreyer" 347 "Honeywell" 346 "Control Solutions" 345 "Korean Maritime University" 344 "Parvus Corporation" 343 "Baumer Group" 342 "THOMAS MAGNETE GmbH" 341 "Boning GmbH & Co" 340 "Continental AG" 339 "Competence Center ISOBUS e.V." 338 "GRAF-SYTECO" 337 "Carraro S.p.A." 336 "APE s.r.o." 335 "Evo Electric Ltd" 334 "Takata-Petri AG" 333 "Hadley Products Corporation" 332 "HWH Corporation" 331 "Horton, Inc." 330 "Kidde Aerospace and Defense" 329 "Deif A/S" 328 "Qwerty Electronik AB" 252 "Sensor-Technik Wiedemann GmbH" 251 "German Agricultural Society" 250 "Kuhn Group" 249 "Schaltbau GmbH" 233 "Yacht Monitoring Solutions Inc." 232 "TSD Integrated Controls" 1863 "Thomas G. Faria Co." 1862 "Sanshin" 1861 "Vector CANtech" 1860 "MMP" 1859 "Kvasar AB" 1858 "Litton" 1857 "Simrad" 1856 "Trimble" 1855 "Furuno USA" 1854 "Northstar Technologies" 1853 "Japan Radio Co." 1852 "Navionics" 1851 "Raymarine" 1850 "Teleflex" 222 "Generac Power Systems, Inc." 221 "SiE" 220 "Beede Electrical Instrument Company, Inc." 219 "Cat OEM Solutions" 218 "Gits Manufacturing Company" 217 "RM Michaelides Software & Elektronik GmbH" 216 "Paneltronics Inc." 215 "Aetna Engineering/Fireboy-Xintex" 214 "MC elettronica Srl" 213 "CNH Belgium N.V." 212 "Sure Power Industries, Inc." 211 "DNA Group" 210 "Iteris, Inc." 209 "Bell Equip. Co. SA (PTY) LTD" 208 "Drew Technologies, Inc." 207 "Otto Engineering" 206 "port GmbH" 205 "SmarTire Systems Inc" 204 "The Morey Corporation" 203 "MILtronik GmbH" 202 "Curtis Instruments, Inc." 201 "Disenos y Tecnologia S.A." 200 "MGM Brakes" 199 "Actia Corp." 198 "Mystic Valley Communications" 197 "Mechron Power Systems" 196 "LEMKEN GmbH & Co. KG" 195 "General Engine Products" 194 "TriMark Corporation" 193 "Nobletec" 192 "Floscan" 191 "XRS Corporation" 190 "Hella KGaA Hueck & Co." 189 "QUALCOMM" 188 "EMP Corp." 187 "Air-Weigh" 186 "Altronic, Inc." 185 "Beede Electrical Instrument Company" 184 "EIA Electronics" 183 "KDS Controls, Inc." 182 "Vehicle Systems Engineering B.V." 181 "Coretronics, Inc." 180 "Smart Power Systems" 179 "TeeJet Technologies Denmark" 178 "Siemens VDO Automotive AG" 177 "Diagnostic System Associates" 176 "Moritz Aerospace" 175 "Veris Technologies, Inc." 174 "AB Volvo Penta" 173 "Ryeso, Inc." 172 "Yanmar Marine USA" 171 "Wachendorff Elektronik GmbH & Co. KG" 170 "Computronics Corporation Ltd." 169 "Marlin Technologies Inc." 168 "Xantrex" 167 "JLG Industries Inc." 166 "Phoenix International" 165 "CPAC Systems AB" 164 "DaimlerChrysler Off-Highway" 163 "BRP Inc." 162 "Axiomatic Technologies" 161 "Offshore Systems (UK) Limited" 160 "Nido" 159 "NTech Industries Inc." 158 "Firestone Industrial Products Company" 157 "ISSPRO Inc." 156 "ITT Industries - Cannon" 155 "Vetronix Corporation" 154 "Westerbeke Corporation" 153 "Woodward, Industrial Controls Division" 152 "elobau GmbH & Co. KG" 151 "Raven Industries Inc. - Flow Controls Division" 150 "Fleetguard" 149 "Holset" 148 "Blue Water Data, Inc." 147 "Nautibus Electronic GmbH" 146 "Maxima Technologies" 145 "MurCal Controls" 144 "Mercury Marine" 143 "W. Gmeiner GmbH & Co." 142 "TRW Automotive (Commercial Steering Systems)" 141 "Thales Navigation Ltd." 140 "Lowrance Electronics, Inc." 139 "Caterpillar Trimble Control Technologies (CTCT), LLC" 138 "Georg Fritzmeier GmbH & Co. KG" 137 "Maretron" 136 "Komatsu Ltd." 135 "Airmar Technology Corporation" 134 "Iris Technology Ltd." 133 "Bucher Schoerling GmbH" 132 "Mulag-Fahrzeugwerk" 131 "ITT Industries" 130 "Nido - Universal Machines B.V." 129 "OMNEX Control Systems, Inc." 128 "Gerhard Duecker GmbH & Co. KG" 127 "Holland USA" 126 "Driver Tech" 125 "Nevada Automotive Test Center" 124 "Hydac Electronic" 123 "Basler Electric" 122 "FG Wilson (Engineering) Limited" 121 "HED (Hydro Electronic Devices, Inc.)" 120 "RDS Technology Ltd." 119 "IntegriNautics" 118 "Intron GmbH" 117 "HUSCO International" 116 "BEELINE Technologies" 115 "NACCO Materials Handling Group, Inc." 114 "EControls, Inc." 113 "Stress-Tek, Inc." 112 "MECALAC" 111 "Maschinenfabrik Bernard Krone GmbH" 110 "EPIQ Sensor-Nite" 109 "TeeJet Technologies Denmark" 108 "WTK-Elecktronik GmbH" 107 "Grimme Landmaschinen GmbH & Co. KG" 106 "BAE Systems Controls, Inc." 105 "Kiepe Elektrik GmbH & Co. KG" 104 "Claas Selbstfahrende Erntemaschinen GmbH" 103 "CLAAS Agrosystems GmbH & Co. KG" 102 "AGCO GmbH & Co." 101 "Sensoria" 100 "VDO Technik AG" 99 "International Transmissions Ltd (ITL)" 98 "Mueller-Elektronik GmbH & Co." 97 "Ag Leader Technology, Inc." 96 "Mech@tronic IT GmbH" 95 "Pacific Insight Electronics Corp." 94 "CNH Global N.V." 93 "Perkins Engines Company Ltd." 92 "Ag-Chem Equipment Co., Inc." 91 "BSG Bodensee Steuergeraete GmbH" 90 "Knorr-Bremse SfN GmbH" 89 "Kverneland Group, Electronics Division" 88 "Satloc Precision GPS" 87 "J.C. Bamford Excavators Ltd (JCB)" 86 "C.E. Niehoff & Company" 85 "Kohler Co." 84 "New Holland UK Limited" 83 "Bendix VORAD Technologies" 82 "Bobcat/Ingersoll-Rand" 81 "Fire Research Corp" 80 "Twin Disc, Inc." 79 "Daimler Benz AG - Engine Division (PBM)" 78 "Frank W. Murphy Manufacturing, Inc." 77 "Deere Power Systems Group" 76 "unused" 75 "Deere & Co. Agricultural Division" 74 "Eaton Axle-Brake Division" 73 "LeTourneau, Inc." 72 "Sisu Corporation" 71 "Vansco Electronics Ltd." 70 "Flex-Coil Limited" 69 "Trimble Navigation" 68 "Scania" 67 "Funk Manufacturing Company" 66 "John Deere Construction Equipment Division" 65 "MAN Nutzfahrzeuge AG" 64 "unused" 63 "ZF Industries Inc." 62 "Wabco" 61 "Volvo Truck Corp." 60 "Volvo Trucks North America Inc." 59 "VES Inc." 58 "SPX Corporation, OTC Division" 57 "Sauer-Danfoss Co." 56 "SAIC" 55 "Ryder System Inc." 54 "Meritor Wabco" 53 "Continental Automotive Systems US, Inc." 52 "Meritor Automotive, Inc." 51 "Robert Bosch GmbH" 50 "Robert Bosch Corp" 49 "RE America Inc." 48 "Pollak Alphabet" 47 "Phillips Semiconductor" 46 "Noregon Systems, Inc" 45 "PACCAR" 44 "Nippondenso Co. Ltd." 43 "International Truck and Engine Corp. Vehicle Electronics" 42 "International Truck and Engine Corp. Engine Electronics" 41 "Motorola Inc." 40 "Motorola AIEG Inc." 39 "Microfirm Inc." 38 "Micro Processor Systems Inc." 37 "Mack Trucks Inc." 36 "Lucas Ltd." 35 "Kenworth Truck Co." 34 "Kelsey Hayes Co." 33 "John Deere" 32 "Jacobs Vehicle Systems" 31 "J Pollak Corp." 30 "Isuzu Motors Ltd." 29 "Hino Motors Ltd." 28 "Grote Ind. Inc." 27 "GMC" 26 "General Motors Corp., Service Technology Group" 25 "Daimler Trucks North America LLC" 24 "Ford Motor Co., Vehicle Controls" 23 "Ford Motor Co., Heavy Truck" 22 "Ford Motor Co., Electronic Concepts $ Systems" 21 "Echilin Inc., Midland Brake Inc." 20 "Eaton Ltd" 19 "Eaton Corp. Trucking Info Services" 18 "Eaton Corp, Transmission Division" 17 "Eaton Corp. Res & Dev" 16 "Eaton Corp." 15 "Dickey-John Corp." 14 "Detroit Diesel Corporation" 13 "Delco Electronics" 12 "Deere & Company, Precision Farming" 11 "Dearborn Group Inc." 10 "Cummins Engine Co." 9 "Chrysler Corp." 8 "Caterpillar Inc." 7 "Case Corp." 6 "Berifors Electronics AB" 5 "AMP Inc." 4 "Ametek-Dixson" 3 "Ametek, US Gauge Division" 2 "Allison Transmission, GMC" 1 "Allied Signal Inc." 0 "Reserved" 231 "Topcon Positioning Systems, Inc." 230 "Saucon Technologies" 229 "Garmin International Inc." 228 "ZF Marine Electronics" 227 "Lykketronic A/S" 226 "Monaco Coach Corporation" 225 "SKF" 224 "EMMI Network, S.L." 223 "Vaueo Retarder Co., Ltd." 263 "IMMI" 262 "HydraForce, Inc" 261 "Red Dot Corporation" 260 "Reichhardt GmbH" 259 "Jetter AG" 258 "ARAG" 257 "Honda Motor Co., Ltd" 256 "Tyco Electronics AMP" 255 "MEAS France" 254 "GE Sensing" 253 "Mobile Control Systems" 298 "Holley Performance" 297 "Zonar Systems Inc" 296 "micro dynamics GmbH" 295 "BEP Marine" 294 "Grayhill Inc." 293 "Spyder Controls Corp." 292 "IKUSI - Angel Iglesias S.A." 291 "Groeneveld Transport Efficiency BV" 290 "Kuebler GmbH" 289 "Watlow" 288 "Mitsubishi FUSO Truck & Bus Corp." 287 "NTech Industries, Inc" 286 "Coelmo srl" 285 "Sea Recovery Corp" 284 "Mobile Tech Chile" 283 "CWF Hamilton & Co Ltd" 282 "Medallion Instrumentation Systems" 281 "Precision Governors LLC" 311 "Patrick Power Products" 310 "TECNORD srl" 309 "Krauss-Maffei Wegmann GmbH & Co. KG" 308 "Cyntrx" 307 "MBW Technologies" 306 "Sleipner Motor AB" 305 "NovAtel Inc" 304 "EmpirBus AB" 303 "CTS Corporation" 302 "Nissin Kogyo Co., LTD" 301 "Parker Hannifin (UK) Ltd FDE group" 300 "Systron Donner Automotive" 299 "Rauch Landmaschinen GmbH" 280 "Leica Geosystems Pty Ltd" 279 "Geometris LP" 278 "Takata Electronics" 277 "LHP Telematics" 276 "Aqua-Hot Heating Systems" 275 "Navico Egersund AS" 274 "LTW Technology Co., LTD" 273 "Active Research Limited" 272 "Gross Mechanical Laboratories, Inc" 327 "Sonceboz SA" 326 "Akron Brass Company" 325 "ASM Automation Sensorik Messtechnik GmbH" 324 "Snap-on Diagnostics" 323 "Mobileye Vision Technologies Ltd." 322 "MICHENKA s.r.o." 321 "Ultra Electronics, Electrics" 320 "Miedema Landbouwwerktuigenfabriek B.V." 319 "Cadec Global" 318 "SAT Plan" 317 "Navtronics Bvba" 316 "ITT Flow Control" 315 "Icom Incorporated" 314 "CSM GmbH" 313 "Ilmor Engineering, Inc" 312 "Lectronix, Inc." 271 "Cole Hersee" 270 "Tennant" 269 "Saft America Inc.,  Space & Defense Division" 268 "Accurate Technologies" 267 "Red Lion Controls, Inc" 266 "International Thermal Research Ltd" 265 "MTS Sensor Technologie GmbH" 264 "Autolync" 248 "Cooper Standard Automotive Active Systems Group" 247 "ePULSE" 246 "Class 1, Inc" 245 "Capstan Ag Systems, Inc." 244 "Techno-Matic" 243 "eRide, Inc." 242 "Kokusandenki Co. Ltd" 241 "Schneider Automation SAS " 240 "Vanair Mfg" 239 "May & Scofield Ltd" 238 "ZF Friedrichshafen AG" 237 "Agtron Enterprises Inc" 236 "Norac Systems International Inc" 235 "SailorMade Marine Telemetry - Tetra Technology Ltd." 234 "Mondial electronic GmbH" ;
VAL_ 2565340926 TouchState 255 "Pressed" 2 "Held" 1 "Pressed" 0 "Released" ;
VAL_ 2565340926 Status_2 1 "Shown" 0 "Hidden" ;
VAL_ 2565340926 SoftKeyCode 0 "AlarmACK" ;
VAL_ 2565340926 OperatingState1 1 "LearnModeActive" 0 "LearnModeInactive" ;
VAL_ 2565340926 Function 127 "Reserved" 126 "Reserved" 125 "Reserved" 124 "Reserved" 123 "Reserved" 122 "Reserved" 121 "Reserved" 120 "Reserved" 119 "Reserved" 118 "Reserved" 117 "Reserved" 116 "Reserved" 115 "Reserved" 114 "Reserved" 113 "Reserved" 112 "Reserved" 111 "Reserved" 110 "Reserved" 109 "Reserved" 108 "Reserved" 107 "Reserved" 106 "Reserved" 105 "Reserved" 104 "Reserved" 103 "Reserved" 102 "Reserved" 101 "Reserved" 42 "Water Pump Control" 41 "Lighting - Operator Controls" 40 "Seat Control" 39 "Ignition Control Module" 38 "Tire Pressure Control" 37 "Cab Controller" 36 "Pneumatic - System Controller" 35 "Suspension - System Controller" 34 "Hydraulic Pump Controller" 33 "System Monitor" 32 "Headway Controller" 31 "Propulsion Battery Charger" 30 "Management Computer" 29 "Virtual Terminal (in cab)" 28 "Off Vehicle Gateway" 27 "Power TakeOff (Secondary or Front)" 26 "Body Controller" 25 "Network Interconnect ECU" 24 "Vehicle Security" 23 "Vehicle Navigation" 22 "Aerodynamic Control" 21 "Cab Climate Control" 20 "Trip Recorder" 19 "Instrument Cluster" 18 "Suspension - Drive Axle" 17 "Suspension - Steer Axle" 16 "Steering Controller" 15 "Fuel System" 14 "Cruise Control" 13 "Retarder - Driveline" 12 "Retarder - Engine" 11 "Brakes - Drive Axle" 10 "Brakes - Steer Axle" 9 "Brakes - System Controller" 8 "Axle - Drive" 7 "Axle - Steering" 6 "Power TakeOff - (Main or Rear)" 5 "Shift Control/Console" 4 "Battery Pack Monitor" 3 "Transmission" 2 "Electric Propulsion Control" 1 "Auxiliary Power Unit (APU)" 0 "Engine" 100 "Reserved" 99 "Reserved" 98 "Reserved" 97 "Reserved" 96 "Reserved" 95 "Reserved" 94 "Reserved" 93 "Reserved" 92 "Reserved" 91 "Reserved" 90 "Reserved" 89 "Reserved" 88 "Reserved" 87 "Reserved" 86 "Reserved" 85 "Reserved" 84 "Reserved" 83 "Reserved" 82 "Reserved" 81 "Reserved" 80 "Reserved" 79 "Reserved" 78 "Fire Suppression System" 77 "Fuel Properties Sensor" 76 "Temperature Sensor" 75 "Supplemental Fan" 74 "Lubrication System" 73 "Rollover Detection Control" 72 "Coolant Valve Controller" 71 "Transfer Case Control" 70 "Auxiliary Regeneration Device" 69 "Engine Emission Aftertreatement System" 68 "Aftertreatment system gas measurement" 67 "Electrical System Controller" 66 "I/O Controller" 65 "Gas Flow Measurement" 64 "Endurance Braking" 63 "Engine Valve Controller" 62 "On-Board Diagnostic Unit" 61 "File Server/Printer" 60 "Cab Display" 59 "Starter" 58 "Fan Drive Control" 57 "Steering Column Unit" 56 "Communications Unit, Radio" 55 "Communications Unit, Satellite" 54 "Communications Unit, Cellular" 53 "Alternator/Charging System" 52 "Chassis Controller" 51 "Forward-Looking Collision Warning System" 50 "Auxiliary Heater" 49 "Clutch/Converter Control" 48 "Ramp Control" 47 "Information System Controller" 46 "Oil Sensor Unit" 45 "Vehicle Dynamic Stability Control" 44 "Exhaust Emission Control" 43 "Transmission Display" ;
VAL_ 2565340926 OperatingState2 1 "InputActivatedInLearnMode" 0 "InputNotActivatedInLearnMode" ;
VAL_ 2565340926 VehicleSystem2 25 "Slurry Applicators" 24 "Utility Vehicles" 23 "Mulchers" 22 "Timber Processing Machines" 21 "Timber loaders" 20 "Forwarders" 19 "Timber Harvesters" 17 "Sensor Systems" 16 "Skidder" 15 "Earth Work" 14 "Special Crops" 13 "Powered Auxiliary Device" 12 "Farm Yard Operations" 11 "Transport/Trailer" 10 "Irrigation" 9 "Forage" 8 "Root Harvesters" 7 "Harvesters" 6 "Sprayers" 5 "Fertilizers" 4 "Planters/Seeders" 3 "Secondary Tillage" 2 "Tillage" 1 "Tractor" 127 "Not Available" 0 "Non-specific System" ;
VAL_ 2565340926 IndustryGroup 6 "Reserved for SAE" 0 "Global" 1 "On-Highway" 2 "Agricultural and Forestry" 3 "Construction" 4 "Marine" 5 "IndustrialProcessCtrlStationary" 7 "Reserved for SAE" ;
VAL_ 2565340926 VTFunctionECUtoVT 39 "AuxiliaryCapabilitiesRequest" 214 "ExtendedDeleteVersion" 213 "ExtendedLoadVersion" 212 "ExtendedStoreVersion" 211 "ExtendedGetVersions" 191 "Execute OpCode" 188 "ExecuteExtendedMacro" 197 "GetSupportedObjects" 187 "Identify VT" 36 "AuxiliaryAssignmentResponseType2" 33 "Auxiliary Input Status" 193 "GetSupported WideChars" 37 "AuxiliaryInputStatusEnableCommandResponse" 35 "AuxiliaryInputMaintenance" 190 "ExecuteMacro" 189 "LockUnlockMask" 34 "AuxiliaryPreferredAssignment" 9 "VTOnUserLayoutHideShowResponse" 186 "SelectColourMap" 185 "GetAttribute" 184 "GraphicsContextCommand" 183 "ChangePolygonScale" 182 "ChangePolygonPoint" 181 "SetObjectLabel" 0 "SoftKeyActivationResponse" 1 "ButtonActivationResponse" 2 "PointingEventResponse" 18 "EndOfObjectPool" 32 "AuxiliaryAssignmentResponse" 146 "ESC" 160 "ShowHideObject" 161 "EnableDisableObject" 162 "SelectInputObject" 163 "ControlAudioDevice" 164 "SetAudioVolume" 165 "ChangeChildLocation" 166 "ChangeSize" 167 "ChangeBackgroundColour" 168 "ChangeNumericValue" 169 "ChangeEndPoint" 170 "ChangeFontAttributes" 171 "ChangeLineAttributes" 172 "ChangeFillAttributes" 173 "ChangeActiveMask" 174 "ChangeSoftKeyMask" 175 "ChangeAttribute" 176 "ChangePriority" 177 "ChangeListItem" 178 "DeleteObjectPool" 192 "GetMemory" 194 "GetNumberOfSoftKeys" 195 "GetTextFontData" 199 "GetHardware" 208 "StoreVersion" 209 "LoadVersion" 210 "DeleteVersion" 223 "GetVersions" 255 "WorkingSetMaintenance" 179 "ChangeStringValue" 3 "VTSelectInputObjectResponse" 4 "VTESCResponse" 5 "VTChangeNumericValueResponse" 6 "VTChangeActiveMaskResponse" 7 "VTChangeSoftKeyMaskResponse" 196 "GetWindowMaskData" 17 "ObjectPoolTransfer" 180 "ChangeChildPosition" 8 "VTChangeStringValueResponse" ;
VAL_ 2565340926 MaskType 1 "Data" 2 "Alarm" ;
VAL_ 2565340926 AuxCapabilitiesRequestType 1 "RequestCapabilitiesOfAuxFunctions" 0 "RequestCapabilitiesOfAuxiliaryInputs" ;
VAL_ 2565340926 OperationCode 36 "<=" 35 ">=" 34 "<" 33 ">" 32 "!=" 31 "==" 13 "--" 12 "++" 11 ">>=" 10 "<<=" 9 "|=" 8 "^=" 7 "&=" 6 "%=" 5 "/=" 4 "*=" 3 "-=" 2 "+=" 1 "=" 0 "Notification" ;
VAL_ 2565340926 RValueSelector 1 "RValueIsValueReferencedByObjectIDAndAID" 0 "RValueIsImmediateOperationValue " ;
VAL_ 2565340926 WSMaintenanceVersion 255 "CompliantWithVTVersion2AndPrior" 4 "CompliantWithVTVersion4" 3 "CompliantWithVTVersion3" ;
VAL_ 2565340926 AssignmentErrorNotAccepted 0 "AssignmentAccepted" 1 "AssignmentNotAccepted" ;
VAL_ 2565340926 ShowOrHide 0 "Hide" 1 "Show" ;
VAL_ 2565340926 EnableOrDisable 0 "Disable" 1 "Enable" ;
VAL_ 2565340926 TextOption 1 "Transparent" 0 "Opaque" ;
SIG_VALTYPE_ 2565340926 ZoomValue : 1;
SIG_VALTYPE_ 2565340926 ZoomValue_PanZoom : 1;

SG_MUL_VAL_ 2565340926 InputObjectId VTFunctionECUtoVT 33-33;
SG_MUL_VAL_ 2565340926 KeyActivationCode VTFunctionECUtoVT 0-0;
SG_MUL_VAL_ 2565340926 ButtonActivationCode VTFunctionECUtoVT 1-1;
SG_MUL_VAL_ 2565340926 XPosition VTFunctionECUtoVT 2-2;
SG_MUL_VAL_ 2565340926 VTSelectInputObjectID VTFunctionECUtoVT 3-3;
SG_MUL_VAL_ 2565340926 VTEscObjectID VTFunctionECUtoVT 4-4;
SG_MUL_VAL_ 2565340926 VTChangeNumericValueObjectID VTFunctionECUtoVT 5-5;
SG_MUL_VAL_ 2565340926 VTChangeActiveMaskObjectID VTFunctionECUtoVT 6-6;
SG_MUL_VAL_ 2565340926 VTChangeSoftKeyMaskParentID VTFunctionECUtoVT 7-7;
SG_MUL_VAL_ 2565340926 AuxiliaryFunctionObjectID VTFunctionECUtoVT 36-36;
SG_MUL_VAL_ 2565340926 InputStatusObjectId VTFunctionECUtoVT 37-37;
SG_MUL_VAL_ 2565340926 SelectInputObjectID VTFunctionECUtoVT 162-162;
SG_MUL_VAL_ 2565340926 ObjectToSizeID VTFunctionECUtoVT 166-166;
SG_MUL_VAL_ 2565340926 ObjectToChangeColourID VTFunctionECUtoVT 167-167;
SG_MUL_VAL_ 2565340926 ObjectToChangeNumValueID VTFunctionECUtoVT 168-168;
SG_MUL_VAL_ 2565340926 ObjectToChangeEndPointID VTFunctionECUtoVT 169-169;
SG_MUL_VAL_ 2565340926 ObjectToChangeFontID VTFunctionECUtoVT 170-170;
SG_MUL_VAL_ 2565340926 ObjectToChangeFillAttributesID VTFunctionECUtoVT 172-172;
SG_MUL_VAL_ 2565340926 ObjectToChangeAttributeID VTFunctionECUtoVT 175-175;
SG_MUL_VAL_ 2565340926 AlarmMaskObjectID VTFunctionECUtoVT 176-176;
SG_MUL_VAL_ 2565340926 ListInputObjectID VTFunctionECUtoVT 177-177;
SG_MUL_VAL_ 2565340926 PolygonObjectToChangeID VTFunctionECUtoVT 182-182;
SG_MUL_VAL_ 2565340926 PolygonObjectToScaleID VTFunctionECUtoVT 183-183;
SG_MUL_VAL_ 2565340926 GraphicsContextObjectID VTFunctionECUtoVT 184-184;
SG_MUL_VAL_ 2565340926 ObjectToGetAttributeID VTFunctionECUtoVT 185-185;
SG_MUL_VAL_ 2565340926 ColourMapObjectID VTFunctionECUtoVT 186-186;
SG_MUL_VAL_ 2565340926 LockUnlockCommand VTFunctionECUtoVT 189-189;
SG_MUL_VAL_ 2565340926 MacroObjecID VTFunctionECUtoVT 190-190;
SG_MUL_VAL_ 2565340926 CodePlane VTFunctionECUtoVT 193-193;
SG_MUL_VAL_ 2565340926 KeyObjectID VTFunctionECUtoVT 0-0;
SG_MUL_VAL_ 2565340926 ButtonObjectID VTFunctionECUtoVT 1-1;
SG_MUL_VAL_ 2565340926 DataOrAlarmMaskObjectID VTFunctionECUtoVT 174-174;
SG_MUL_VAL_ 2565340926 MemoryRequired VTFunctionECUtoVT 192-192;
SG_MUL_VAL_ 2565340926 FirstWideChar VTFunctionECUtoVT 193-193;
SG_MUL_VAL_ 2565340926 IdentityNumber VTFunctionECUtoVT 34-34;
SG_MUL_VAL_ 2565340926 Status_1 VTFunctionECUtoVT 9-9;
SG_MUL_VAL_ 2565340926 YPosition VTFunctionECUtoVT 2-2;
SG_MUL_VAL_ 2565340926 VTSelectInputObjectStatus VTFunctionECUtoVT 3-3;
SG_MUL_VAL_ 2565340926 VTChangeSoftKeyMaskObjectID VTFunctionECUtoVT 7-7;
SG_MUL_VAL_ 2565340926 AuxInputEnable VTFunctionECUtoVT 37-37;
SG_MUL_VAL_ 2565340926 ChangeChildPositionObjectID VTFunctionECUtoVT 180-180;
SG_MUL_VAL_ 2565340926 NewBackgroundColour VTFunctionECUtoVT 167-167;
SG_MUL_VAL_ 2565340926 AttributeID VTFunctionECUtoVT 185-185;
SG_MUL_VAL_ 2565340926 NewPriority VTFunctionECUtoVT 176-176;
SG_MUL_VAL_ 2565340926 ListIndex VTFunctionECUtoVT 177-177;
SG_MUL_VAL_ 2565340926 ChangeChildLocationObjectID VTFunctionECUtoVT 165-165;
SG_MUL_VAL_ 2565340926 NewWidthAttribute VTFunctionECUtoVT 183-183;
SG_MUL_VAL_ 2565340926 SubCommandID VTFunctionECUtoVT 184-184;
SG_MUL_VAL_ 2565340926 Value1 VTFunctionECUtoVT 33-33;
SG_MUL_VAL_ 2565340926 KeyObjectParentID VTFunctionECUtoVT 0-0;
SG_MUL_VAL_ 2565340926 ButtonObjectParentID VTFunctionECUtoVT 1-1;
SG_MUL_VAL_ 2565340926 VTChangeNumericValueValue VTFunctionECUtoVT 5-5;
SG_MUL_VAL_ 2565340926 NewObjectID VTFunctionECUtoVT 177-177;
SG_MUL_VAL_ 2565340926 LastWideChar VTFunctionECUtoVT 193-193;
SG_MUL_VAL_ 2565340926 ManufacturerCode VTFunctionECUtoVT 34-34;
SG_MUL_VAL_ 2565340926 TouchState VTFunctionECUtoVT 2-2;
SG_MUL_VAL_ 2565340926 NewHeigthAttribute VTFunctionECUtoVT 183-183;
SG_MUL_VAL_ 2565340926 Value2 VTFunctionECUtoVT 33-33;
SG_MUL_VAL_ 2565340926 Status_2 VTFunctionECUtoVT 9-9;
SG_MUL_VAL_ 2565340926 SoftKeyCode VTFunctionECUtoVT 0-0;
SG_MUL_VAL_ 2565340926 ButtonKeyCode VTFunctionECUtoVT 1-1;
SG_MUL_VAL_ 2565340926 ECUInstance VTFunctionECUtoVT 34-34;
SG_MUL_VAL_ 2565340926 FunctionInstance VTFunctionECUtoVT 34-34;
SG_MUL_VAL_ 2565340926 OperatingState1 VTFunctionECUtoVT 33-33;
SG_MUL_VAL_ 2565340926 Function VTFunctionECUtoVT 34-34;
SG_MUL_VAL_ 2565340926 OperatingState2 VTFunctionECUtoVT 33-33;
SG_MUL_VAL_ 2565340926 VehicleSystem2 VTFunctionECUtoVT 34-34;
SG_MUL_VAL_ 2565340926 VehicleSystemInstance VTFunctionECUtoVT 34-34;
SG_MUL_VAL_ 2565340926 IndustryGroup VTFunctionECUtoVT 34-34;
SG_MUL_VAL_ 2565340926 ArbitraryAddressCapable VTFunctionECUtoVT 34-34;
SG_MUL_VAL_ 2565340926 ObjectId_1 VTFunctionECUtoVT 9-9;
SG_MUL_VAL_ 2565340926 SourceAddressOfAuxiliaryInputDev VTFunctionECUtoVT 32-32;
SG_MUL_VAL_ 2565340926 ChangeChildPositionParentOb_0000 VTFunctionECUtoVT 180-180;
SG_MUL_VAL_ 2565340926 ObjectPoolRecord VTFunctionECUtoVT 17-17;
SG_MUL_VAL_ 2565340926 NumberOfInpuUnits VTFunctionECUtoVT 34-34;
SG_MUL_VAL_ 2565340926 AuxModelIdentification VTFunctionECUtoVT 35-35;
SG_MUL_VAL_ 2565340926 ObjectToShowHideID VTFunctionECUtoVT 160-160;
SG_MUL_VAL_ 2565340926 ObjectoEnableDisbaleID VTFunctionECUtoVT 161-161;
SG_MUL_VAL_ 2565340926 NumberOfRepetitions_Audio VTFunctionECUtoVT 163-163;
SG_MUL_VAL_ 2565340926 AudioVolume VTFunctionECUtoVT 164-164;
SG_MUL_VAL_ 2565340926 ChangeChildLocationParentOb_0000 VTFunctionECUtoVT 165-165;
SG_MUL_VAL_ 2565340926 ObjectToChangeLineAttributesID VTFunctionECUtoVT 171-171;
SG_MUL_VAL_ 2565340926 WorkingSetObjectID VTFunctionECUtoVT 173-173;
SG_MUL_VAL_ 2565340926 MaskType VTFunctionECUtoVT 174-174;
SG_MUL_VAL_ 2565340926 ObjectToChangeStringValueID VTFunctionECUtoVT 179-179;
SG_MUL_VAL_ 2565340926 ParentObjectID VTFunctionECUtoVT 8-8;
SG_MUL_VAL_ 2565340926 ObjectToAssociateLabelWithID VTFunctionECUtoVT 181-181;
SG_MUL_VAL_ 2565340926 VersionLabelToStore VTFunctionECUtoVT 208-208;
SG_MUL_VAL_ 2565340926 VersionLabelToLoad VTFunctionECUtoVT 209-209;
SG_MUL_VAL_ 2565340926 VersionLabelToDelete VTFunctionECUtoVT 210-210;
SG_MUL_VAL_ 2565340926 WSMaintenanceInitiating WSMaintenanceVersion 3-254;
SG_MUL_VAL_ 2565340926 AuxCapabilitiesRequestType VTFunctionECUtoVT 39-39;
SG_MUL_VAL_ 2565340926 OperationCode VTFunctionECUtoVT 191-191;
SG_MUL_VAL_ 2565340926 MacroObjectID_2 VTFunctionECUtoVT 188-188;
SG_MUL_VAL_ 2565340926 ExtendedVersionLabelToStore VTFunctionECUtoVT 212-212;
SG_MUL_VAL_ 2565340926 ExtendedVersionLabelToLoad VTFunctionECUtoVT 213-213;
SG_MUL_VAL_ 2565340926 ExtendedVersionLabelToDelete VTFunctionECUtoVT 214-214;
SG_MUL_VAL_ 2565340926 RValueSelector OperationCode 1-127;
SG_MUL_VAL_ 2565340926 LeftObjectID OperationCode 1-13, 31-36;
SG_MUL_VAL_ 2565340926 AuxiliaryInputNumber VTFunctionECUtoVT 32-32;
SG_MUL_VAL_ 2565340926 WSMaintenanceVersion VTFunctionECUtoVT 255-255;
SG_MUL_VAL_ 2565340926 Frequency_Audio VTFunctionECUtoVT 163-163;
SG_MUL_VAL_ 2565340926 ObjectIDOfDataMaskToLock VTFunctionECUtoVT 189-189;
SG_MUL_VAL_ 2565340926 AuxiliaryFunctionID VTFunctionECUtoVT 32-32;
SG_MUL_VAL_ 2565340926 ObjectOfChangedStringValueID VTFunctionECUtoVT 8-8;
SG_MUL_VAL_ 2565340926 AssignmentErrorNotAccepted VTFunctionECUtoVT 36-36;
SG_MUL_VAL_ 2565340926 ShowOrHide VTFunctionECUtoVT 160-160;
SG_MUL_VAL_ 2565340926 EnableOrDisable VTFunctionECUtoVT 161-161;
SG_MUL_VAL_ 2565340926 SetFocusOpenForEditing VTFunctionECUtoVT 162-162;
SG_MUL_VAL_ 2565340926 NewWidth VTFunctionECUtoVT 166-166;
SG_MUL_VAL_ 2565340926 Width VTFunctionECUtoVT 169-169;
SG_MUL_VAL_ 2565340926 FontColour VTFunctionECUtoVT 170-170;
SG_MUL_VAL_ 2565340926 LineColour VTFunctionECUtoVT 171-171;
SG_MUL_VAL_ 2565340926 FillType VTFunctionECUtoVT 172-172;
SG_MUL_VAL_ 2565340926 NewActiveMaskObjectID VTFunctionECUtoVT 173-173;
SG_MUL_VAL_ 2565340926 StringVariableObjectID VTFunctionECUtoVT 181-181;
SG_MUL_VAL_ 2565340926 IndexOfThePointToReplace VTFunctionECUtoVT 182-182;
SG_MUL_VAL_ 2565340926 AttributeIDToChange VTFunctionECUtoVT 175-175;
SG_MUL_VAL_ 2565340926 TotalNumberOfBytes VTFunctionECUtoVT 179-179;
SG_MUL_VAL_ 2565340926 ObjectId_2 VTFunctionECUtoVT 9-9;
SG_MUL_VAL_ 2565340926 AuxErrorInvalidInputID VTFunctionECUtoVT 37-37;
SG_MUL_VAL_ 2565340926 OnTimeDuration_Audio VTFunctionECUtoVT 163-163;
SG_MUL_VAL_ 2565340926 NewValue VTFunctionECUtoVT 168-168;
SG_MUL_VAL_ 2565340926 FontSize VTFunctionECUtoVT 170-170;
SG_MUL_VAL_ 2565340926 LineWidth VTFunctionECUtoVT 171-171;
SG_MUL_VAL_ 2565340926 FillColour VTFunctionECUtoVT 172-172;
SG_MUL_VAL_ 2565340926 NewSoftKeyMaskObjectID VTFunctionECUtoVT 174-174;
SG_MUL_VAL_ 2565340926 NewAttributeValue VTFunctionECUtoVT 175-175;
SG_MUL_VAL_ 2565340926 NewValueX VTFunctionECUtoVT 182-182;
SG_MUL_VAL_ 2565340926 LockTimeout VTFunctionECUtoVT 189-189;
SG_MUL_VAL_ 2565340926 PictureGraphicsID_Viewport SubCommandID 20-20;
SG_MUL_VAL_ 2565340926 PictureGraphicsID_Canvas SubCommandID 19-19;
SG_MUL_VAL_ 2565340926 ObjectID SubCommandID 18-18;
SG_MUL_VAL_ 2565340926 NewViewportWidth SubCommandID 17-17;
SG_MUL_VAL_ 2565340926 ViewportX_PanZoom SubCommandID 16-16;
SG_MUL_VAL_ 2565340926 ZoomValue SubCommandID 15-15;
SG_MUL_VAL_ 2565340926 ViewportX SubCommandID 14-14;
SG_MUL_VAL_ 2565340926 TextOption SubCommandID 13-13;
SG_MUL_VAL_ 2565340926 NumberOfPoints SubCommandID 12-12;
SG_MUL_VAL_ 2565340926 EllipseWidth SubCommandID 11-11;
SG_MUL_VAL_ 2565340926 RectangleWidth_Draw SubCommandID 10-10;
SG_MUL_VAL_ 2565340926 EndPixelOffsetX SubCommandID 9-9;
SG_MUL_VAL_ 2565340926 PixelOffsetX SubCommandID 8-8;
SG_MUL_VAL_ 2565340926 RectangleHeight_Erase SubCommandID 7-7;
SG_MUL_VAL_ 2565340926 RectangleWidth_Erase SubCommandID 7-7;
SG_MUL_VAL_ 2565340926 FontAttributesObjectID SubCommandID 6-6;
SG_MUL_VAL_ 2565340926 FillAttributesObjectID SubCommandID 5-5;
SG_MUL_VAL_ 2565340926 LineAttributesObjectID SubCommandID 4-4;
SG_MUL_VAL_ 2565340926 BackgroundColour SubCommandID 3-3;
SG_MUL_VAL_ 2565340926 ForegroundColour SubCommandID 2-2;
SG_MUL_VAL_ 2565340926 LeftAID OperationCode 1-13, 31-36;
SG_MUL_VAL_ 2565340926 ImmediateOperandValue RValueSelector 0-0;
SG_MUL_VAL_ 2565340926 RightObjectID RValueSelector 1-1;
SG_MUL_VAL_ 2565340926 CursorOffsetX SubCommandID 1-1;
SG_MUL_VAL_ 2565340926 CursorPosX SubCommandID 0-0;
SG_MUL_VAL_ 2565340926 AuxErrorAnyOther VTFunctionECUtoVT 37-37;
SG_MUL_VAL_ 2565340926 TextLength SubCommandID 13-13;
SG_MUL_VAL_ 2565340926 XPosChangeTopLeft VTFunctionECUtoVT 165-165;
SG_MUL_VAL_ 2565340926 NewHeight VTFunctionECUtoVT 166-166;
SG_MUL_VAL_ 2565340926 Height VTFunctionECUtoVT 169-169;
SG_MUL_VAL_ 2565340926 LabelFontType VTFunctionECUtoVT 181-181;
SG_MUL_VAL_ 2565340926 LineArt VTFunctionECUtoVT 171-171;
SG_MUL_VAL_ 2565340926 FillPatternObjectID VTFunctionECUtoVT 172-172;
SG_MUL_VAL_ 2565340926 XPosChangeTopLeftLong VTFunctionECUtoVT 180-180;
SG_MUL_VAL_ 2565340926 FontType VTFunctionECUtoVT 170-170;
SG_MUL_VAL_ 2565340926 NewStringValue VTFunctionECUtoVT 179-179;
SG_MUL_VAL_ 2565340926 CursorPosY SubCommandID 0-0;
SG_MUL_VAL_ 2565340926 CursorOffsetY SubCommandID 1-1;
SG_MUL_VAL_ 2565340926 PixelOffsetY SubCommandID 8-8;
SG_MUL_VAL_ 2565340926 EndPixelOffsetY SubCommandID 9-9;
SG_MUL_VAL_ 2565340926 RectangleHeight_Draw SubCommandID 10-10;
SG_MUL_VAL_ 2565340926 EllipseHeight SubCommandID 11-11;
SG_MUL_VAL_ 2565340926 ViewportY SubCommandID 14-14;
SG_MUL_VAL_ 2565340926 ViewportY_PanZoom SubCommandID 16-16;
SG_MUL_VAL_ 2565340926 NewViewportHeight SubCommandID 17-17;
SG_MUL_VAL_ 2565340926 OffTimeDuration_Audio VTFunctionECUtoVT 163-163;
SG_MUL_VAL_ 2565340926 YPosChangeTopLeft VTFunctionECUtoVT 165-165;
SG_MUL_VAL_ 2565340926 FontStyle VTFunctionECUtoVT 170-170;
SG_MUL_VAL_ 2565340926 GraphicRepresentationObjectID VTFunctionECUtoVT 181-181;
SG_MUL_VAL_ 2565340926 NewValueY VTFunctionECUtoVT 182-182;
SG_MUL_VAL_ 2565340926 LineDirection VTFunctionECUtoVT 169-169;
SG_MUL_VAL_ 2565340926 YPosChangeTopLeftLong VTFunctionECUtoVT 180-180;
SG_MUL_VAL_ 2565340926 RightAID RValueSelector 1-1;
SG_MUL_VAL_ 2565340926 ZoomValue_PanZoom SubCommandID 16-16;
SG_MUL_VAL_ 2565340926 NotificationValue1 OperationCode 0-0;
SG_MUL_VAL_ 2565340926 ThenMacroObjectID OperationCode 31-36;
SG_MUL_VAL_ 2565340926 ModelIdentificationCode VTFunctionECUtoVT 34-34;
SG_MUL_VAL_ 2565340926 NotificationValue2 OperationCode 0-0;
SG_MUL_VAL_ 2565340926 ElseMacroObjectID OperationCode 31-36;
SG_MUL_VAL_ 2565340926 NumOfPreferredFunctions VTFunctionECUtoVT 34-34;
SG_MUL_VAL_ 2565340926 AuxiliaryFunctionID_1 VTFunctionECUtoVT 34-34;
SG_MUL_VAL_ 2565340926 AuxiliaryInputID_1 VTFunctionECUtoVT 34-34;
